VERSION "HNNBNNNYNNNNNNNNNNNNNNNNNNNNNNNNNNNNNNNNNN/4/%%%/4/'%**4NNN///"

NS_ :

BS_:

BU_: BAP_Tester BCM1 Gateway Gateway_PAG Klima_MSB Lift_VA VAS_L VAS_R

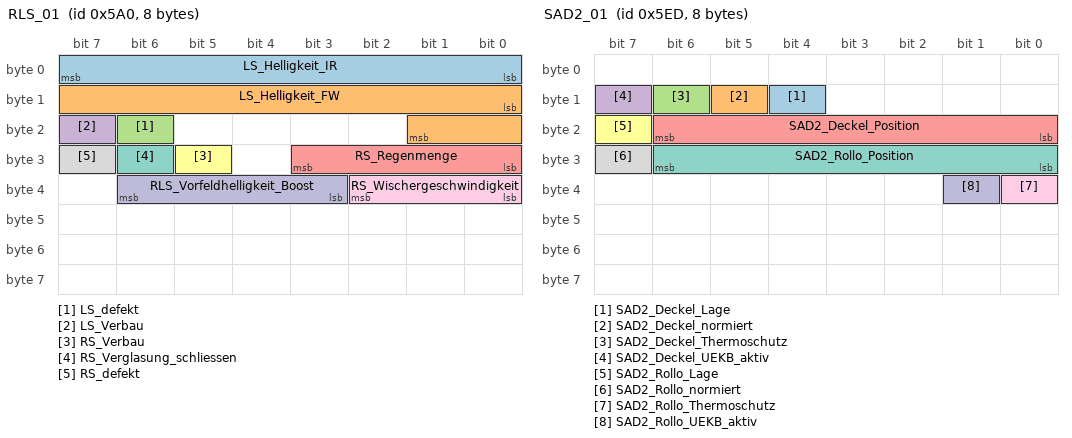
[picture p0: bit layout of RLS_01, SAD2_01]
BO_ 1440 RLS_01: 8 BCM1
 SG_ LS_Helligkeit_IR : 0|8@1+ (400,0) [0|101200] "Unit_Lux"  Gateway,Gateway_PAG,VAS_L,VAS_R
 SG_ LS_Helligkeit_FW : 8|10@1+ (6,0) [0|6126] "Unit_Lux"  Gateway,Gateway_PAG,VAS_L,VAS_R
 SG_ LS_defekt : 22|1@1+ (1.0,0.0) [0.0|1] ""  Gateway,Gateway_PAG,VAS_L,VAS_R
 SG_ LS_Verbau : 23|1@1+ (1.0,0.0) [0.0|1] ""  Gateway,Gateway_PAG,VAS_L,VAS_R
 SG_ RS_Regenmenge : 24|4@1+ (1.0,0.0) [0.0|15] ""  Gateway,Gateway_PAG,Klima_MSB
 SG_ RS_Verbau : 29|1@1+ (1.0,0.0) [0.0|1] ""  Gateway,Gateway_PAG,VAS_L,VAS_R
 SG_ RS_Verglasung_schliessen : 30|1@1+ (1.0,0.0) [0.0|1] ""  Gateway,Gateway_PAG
 SG_ RS_defekt : 31|1@1+ (1.0,0.0) [0.0|1] ""  Gateway,Gateway_PAG,VAS_L,VAS_R
 SG_ RS_Wischergeschwindigkeit : 32|3@1+ (1.0,0.0) [0.0|7] ""  Gateway,Gateway_PAG,VAS_L,VAS_R
 SG_ RLS_Vorfeldhelligkeit_Boost : 35|4@1+ (1.0,0.0) [0.0|15] ""  Gateway,Gateway_PAG

BO_ 1517 SAD2_01: 8 Gateway
 SG_ SAD2_Deckel_Lage : 12|1@1+ (1.0,0.0) [0.0|1] ""  Vector__XXX
 SG_ SAD2_Deckel_normiert : 13|1@1+ (1.0,0.0) [0.0|1] ""  Vector__XXX
 SG_ SAD2_Deckel_Thermoschutz : 14|1@1+ (1.0,0.0) [0.0|1] ""  Vector__XXX
 SG_ SAD2_Deckel_UEKB_aktiv : 15|1@1+ (1.0,0.0) [0.0|1] ""  Vector__XXX
 SG_ SAD2_Deckel_Position : 16|7@1+ (1,0) [0|100] "Unit_PerCent"  Vector__XXX
 SG_ SAD2_Rollo_Lage : 23|1@1+ (1.0,0.0) [0.0|1] ""  BCM1,Klima_MSB
 SG_ SAD2_Rollo_Position : 24|7@1+ (1,0) [0|100] "Unit_PerCent"  BCM1,Klima_MSB
 SG_ SAD2_Rollo_normiert : 31|1@1+ (1.0,0.0) [0.0|1] ""  Vector__XXX
 SG_ SAD2_Rollo_Thermoschutz : 32|1@1+ (1.0,0.0) [0.0|1] ""  Vector__XXX
 SG_ SAD2_Rollo_UEKB_aktiv : 33|1@1+ (1.0,0.0) [0.0|1] ""  Vector__XXX

BO_ 1504 SAD_01: 8 Gateway
 SG_ MD1_Position : 8|7@1+ (1,0) [0|100] "Unit_PerCent"  BCM1,Klima_MSB
 SG_ MD1_Lage : 15|1@1+ (1.0,0.0) [0.0|1] ""  BCM1,Klima_MSB
 SG_ MD3_Position : 16|7@1+ (1,0) [0|100] "Unit_PerCent"  BCM1,Klima_MSB
 SG_ MD3_Lage : 23|1@1+ (1.0,0.0) [0.0|1] ""  BCM1,Klima_MSB
 SG_ MRollo_Position : 24|7@1+ (1,0) [0|100] "Unit_PerCent"  BCM1,Klima_MSB
 SG_ MRollo_Lage : 31|1@1+ (1.0,0.0) [0.0|1] ""  BCM1,Klima_MSB
 SG_ SAD_normiert : 32|1@1+ (1.0,0.0) [0.0|1] ""  Vector__XXX
 SG_ SAD_Thermoschutz : 33|1@1+ (1.0,0.0) [0.0|1] ""  Vector__XXX
 SG_ SAD_UEKB_aktiv : 34|1@1+ (1.0,0.0) [0.0|1] ""  Vector__XXX
 SG_ Rollo_normiert : 35|1@1+ (1.0,0.0) [0.0|1] ""  Vector__XXX
 SG_ Rollo_Thermoschutz : 36|1@1+ (1.0,0.0) [0.0|1] ""  Vector__XXX
 SG_ Rollo_UEKB_aktiv : 37|1@1+ (1.0,0.0) [0.0|1] ""  Vector__XXX
 SG_ SAD_Taster_Deckel_hi : 38|4@1+ (1.0,0.0) [0.0|15] ""  Vector__XXX
 SG_ SAD_Taster_Deckel_vo : 42|4@1+ (1.0,0.0) [0.0|15] ""  Vector__XXX
 SG_ SAD_Taster_Rollo_hi : 46|3@1+ (1.0,0.0) [0.0|7] ""  Vector__XXX
 SG_ SAD_Taster_Rollo_vo : 49|3@1+ (1.0,0.0) [0.0|7] ""  Vector__XXX
 SG_ SAD_Anf_ESC_Zuschaltung : 52|1@1+ (1.0,0.0) [0.0|1] ""  Vector__XXX
 SG_ SAD_Text : 53|1@1+ (1.0,0.0) [0.0|1] ""  Vector__XXX
 SG_ SAD_ToggleBit : 54|1@1+ (1,0) [0|1] ""  Vector__XXX
 SG_ SAD_ParityBit : 55|1@1+ (1,0) [0|1] ""  Vector__XXX

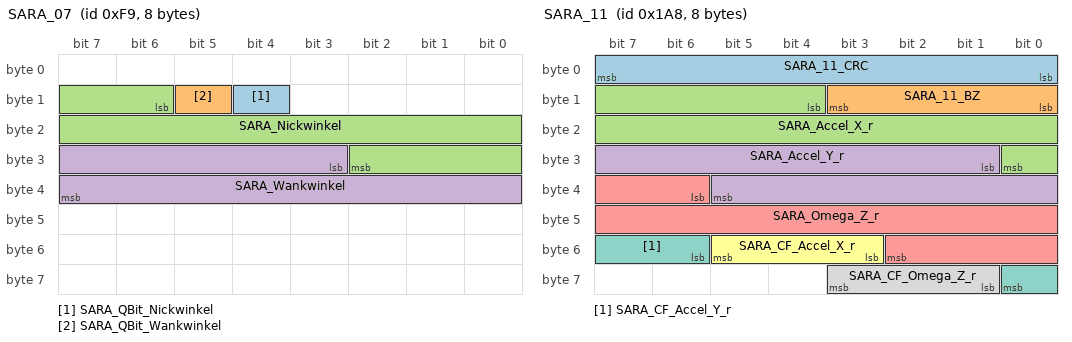
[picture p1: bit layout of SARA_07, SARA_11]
BO_ 249 SARA_07: 8 Gateway
 SG_ SARA_QBit_Nickwinkel : 12|1@1+ (1.0,0.0) [0.0|1] ""  BCM1,Klima_MSB
 SG_ SARA_QBit_Wankwinkel : 13|1@1+ (1.0,0.0) [0.0|1] ""  BCM1,Klima_MSB
 SG_ SARA_Nickwinkel : 14|13@1+ (0.025,-102.3) [-102.300|102.450] "Unit_DegreOfArc"  BCM1,Klima_MSB
 SG_ SARA_Wankwinkel : 27|13@1+ (0.025,-102.3) [-102.300|102.450] "Unit_DegreOfArc"  BCM1,Klima_MSB

BO_ 424 SARA_11: 8 Gateway
 SG_ SARA_11_CRC : 0|8@1+ (1,0) [0|255] ""  BCM1
 SG_ SARA_11_BZ : 8|4@1+ (1,0) [0|15] ""  BCM1
 SG_ SARA_Accel_X_r : 12|13@1+ (0.16,-655.36) [-655.20|655.04] "Unit_MeterPerSeconSquar"  BCM1,Lift_VA,VAS_L,VAS_R
 SG_ SARA_Accel_Y_r : 25|13@1+ (0.16,-655.36) [-655.20|655.04] "Unit_MeterPerSeconSquar"  BCM1,Lift_VA,VAS_L,VAS_R
 SG_ SARA_Omega_Z_r : 38|13@1+ (0.08,-327.68) [-327.60|327.52] "Unit_DegreOfArcPerSecon"  BCM1,VAS_L,VAS_R
 SG_ SARA_CF_Accel_X_r : 51|3@1+ (1.0,0.0) [0.0|7] ""  BCM1,VAS_L,VAS_R
 SG_ SARA_CF_Accel_Y_r : 54|3@1+ (1.0,0.0) [0.0|7] ""  BCM1,VAS_L,VAS_R
 SG_ SARA_CF_Omega_Z_r : 57|3@1+ (1.0,0.0) [0.0|7] ""  BCM1,VAS_L,VAS_R

BO_ 1522 Sensorik_Dimmung_01: 2 Gateway
 SG_ KBI_Phototransistor : 0|8@1+ (1,0) [0|253] ""  BCM1
 SG_ KBI_Dimmpoti : 8|7@1+ (1,0) [0|100] "Unit_PerCent"  BCM1

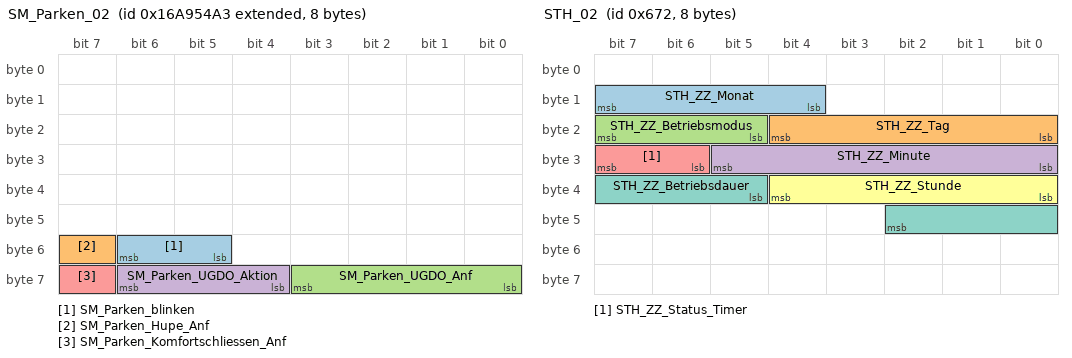
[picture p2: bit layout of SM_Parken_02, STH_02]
BO_ 2527679651 SM_Parken_02: 8 Gateway
 SG_ SM_Parken_blinken : 53|2@1+ (1.0,0.0) [0.0|3] ""  Vector__XXX
 SG_ SM_Parken_Hupe_Anf : 55|1@1+ (1.0,0.0) [0.0|1] ""  BCM1
 SG_ SM_Parken_UGDO_Anf : 56|4@1+ (1.0,0.0) [0.0|15] ""  BCM1
 SG_ SM_Parken_UGDO_Aktion : 60|3@1+ (1.0,0.0) [0.0|7] ""  BCM1
 SG_ SM_Parken_Komfortschliessen_Anf : 63|1@1+ (1.0,0.0) [0.0|1] ""  Vector__XXX

BO_ 980 SMLS_01: 8 Gateway
 SG_ SMLS_01_CRC : 0|8@1+ (1,0) [0|255] ""  BCM1
 SG_ SMLS_01_BZ : 8|4@1+ (1,0) [0|15] ""  BCM1
 SG_ BH_Blinker_li : 12|1@1+ (1.0,0.0) [0.0|1] ""  BCM1
 SG_ BH_Blinker_re : 13|1@1+ (1.0,0.0) [0.0|1] ""  BCM1
 SG_ BH_Lichthupe : 14|1@1+ (1.0,0.0) [0.0|1] ""  BCM1
 SG_ BH_Fernlicht : 15|1@1+ (1.0,0.0) [0.0|1] ""  BCM1
 SG_ WH_Tipwischen : 16|1@1+ (1.0,0.0) [0.0|1] ""  BCM1,VAS_L,VAS_R
 SG_ WH_Intervall : 17|1@1+ (1.0,0.0) [0.0|1] ""  BCM1
 SG_ WH_WischerStufe1 : 18|1@1+ (1.0,0.0) [0.0|1] ""  BCM1
 SG_ WH_WischerStufe2 : 19|1@1+ (1.0,0.0) [0.0|1] ""  BCM1
 SG_ WH_Frontwaschen : 20|1@1+ (1.0,0.0) [0.0|1] ""  BCM1
 SG_ WH_Heckintervall : 21|1@1+ (1.0,0.0) [0.0|1] ""  BCM1
 SG_ WH_Heckwaschen : 22|1@1+ (1.0,0.0) [0.0|1] ""  BCM1
 SG_ WH_Intervallstufen : 23|4@1+ (1.0,0.0) [0.0|15] ""  BCM1
 SG_ FAS_Taster : 27|1@1+ (1.0,0.0) [0.0|1] ""  Vector__XXX
 SG_ FAS_Taster_Fehler : 28|1@1+ (1.0,0.0) [0.0|1] ""  Vector__XXX
 SG_ SMLS_Hupe : 29|1@1+ (1.0,0.0) [0.0|1] ""  BCM1
 SG_ LRH_On_Off : 30|2@1+ (1.0,0.0) [0.0|3] ""  BCM1,Klima_MSB
 SG_ LRH_aktiv : 40|1@1+ (1.0,0.0) [0.0|1] ""  Vector__XXX
 SG_ SMLS_P_verriegelt_plausibel : 43|1@1+ (1.0,0.0) [0.0|1] ""  Vector__XXX
 SG_ WH_SRA : 44|1@1+ (1.0,0.0) [0.0|1] ""  BCM1
 SG_ WH_Wischer_Fehler : 45|1@1+ (1.0,0.0) [0.0|1] ""  BCM1
 SG_ BH_Blinker_Fehler : 46|1@1+ (1.0,0.0) [0.0|1] ""  Vector__XXX
 SG_ SMLS_PTT : 47|1@1+ (1.0,0.0) [0.0|1] ""  Vector__XXX
 SG_ WH_Tipwischen_lang : 48|1@1+ (1.0,0.0) [0.0|1] ""  BCM1

BO_ 1467 SoSe_01: 8 BCM1
 SG_ SoSe_SunInt_2D_Li : 0|8@1+ (5,0) [0|1200] "Unit_WattPerMeterSquar"  Gateway,Gateway_PAG,Klima_MSB
 SG_ SoSe_SunInt_2D_Re : 8|8@1+ (5,0) [0|1200] "Unit_WattPerMeterSquar"  Gateway,Gateway_PAG,Klima_MSB

BO_ 1710 Spiegel_01: 8 Gateway
 SG_ SP_FT_oben : 0|1@1+ (1.0,0.0) [0.0|1] ""  Vector__XXX
 SG_ SP_FT_unten : 1|1@1+ (1.0,0.0) [0.0|1] ""  Vector__XXX
 SG_ SP_FT_links : 2|1@1+ (1.0,0.0) [0.0|1] ""  Vector__XXX
 SG_ SP_FT_rechts : 3|1@1+ (1.0,0.0) [0.0|1] ""  Vector__XXX
 SG_ SP_BT_oben : 4|1@1+ (1.0,0.0) [0.0|1] ""  Vector__XXX
 SG_ SP_BT_unten : 5|1@1+ (1.0,0.0) [0.0|1] ""  Vector__XXX
 SG_ SP_BT_links : 6|1@1+ (1.0,0.0) [0.0|1] ""  Vector__XXX
 SG_ SP_BT_rechts : 7|1@1+ (1.0,0.0) [0.0|1] ""  Vector__XXX
 SG_ SP_abklappen : 8|1@1+ (1.0,0.0) [0.0|1] ""  Vector__XXX
 SG_ SP_anklappen : 9|1@1+ (1.0,0.0) [0.0|1] ""  Vector__XXX
 SG_ SP_normieren : 10|1@1+ (1.0,0.0) [0.0|1] ""  Vector__XXX
 SG_ SP_Hzg_Taster : 12|1@1+ (1.0,0.0) [0.0|1] ""  VAS_L,VAS_R
 SG_ SP_S_oben : 16|1@1+ (1.0,0.0) [0.0|1] ""  BCM1,VAS_L,VAS_R
 SG_ SP_S_unten : 17|1@1+ (1.0,0.0) [0.0|1] ""  BCM1,VAS_L,VAS_R
 SG_ SP_S_links : 18|1@1+ (1.0,0.0) [0.0|1] ""  BCM1,VAS_L,VAS_R
 SG_ SP_S_rechts : 19|1@1+ (1.0,0.0) [0.0|1] ""  BCM1,VAS_L,VAS_R
 SG_ SP_Auswahl_li : 20|1@1+ (1.0,0.0) [0.0|1] ""  BCM1,VAS_L,VAS_R
 SG_ SP_Auswahl_re : 21|1@1+ (1.0,0.0) [0.0|1] ""  BCM1,VAS_L,VAS_R
 SG_ SP_ARA_Status : 22|1@1+ (1.0,0.0) [0.0|1] ""  BCM1
 SG_ SP_S_Klappen : 23|1@1+ (1.0,0.0) [0.0|1] ""  BCM1,VAS_L,VAS_R
 SG_ SP_Verstellschalter_Fehler : 24|1@1+ (1.0,0.0) [0.0|1] ""  BCM1,VAS_L,VAS_R

BO_ 1313 STH_01: 8 Gateway
 SG_ STH_Funk_ein : 0|1@1+ (1.0,0.0) [0.0|1] ""  BCM1,Klima_MSB
 SG_ STH_Funk_aus : 1|1@1+ (1.0,0.0) [0.0|1] ""  BCM1,Klima_MSB
 SG_ STH_Zusatzheizung : 2|1@1+ (1.0,0.0) [0.0|1] ""  BCM1,Klima_MSB
 SG_ STH_LED : 3|1@1+ (1.0,0.0) [0.0|1] ""  BCM1,Klima_MSB
 SG_ STH_Pumpe_ein : 4|1@1+ (1,0) [0|1] ""  BCM1,Klima_MSB
 SG_ STH_Geblaese : 5|1@1+ (1.0,0.0) [0.0|1] ""  BCM1,Klima_MSB
 SG_ STH_EKP_Anst : 6|1@1+ (1.0,0.0) [0.0|1] ""  BCM1,Klima_MSB
 SG_ STH_Start_folgt : 7|1@1+ (1.0,0.0) [0.0|1] ""  Vector__XXX
 SG_ STH_Ventiloeffnungszeit : 8|6@1+ (1,0) [0|63] "Unit_Minut"  BCM1,Klima_MSB
 SG_ STH_Ventil_Status : 14|1@1+ (1.0,0.0) [0.0|1] ""  BCM1,Klima_MSB
 SG_ STH_Fehler_ElWaPu : 15|1@1+ (1.0,0.0) [0.0|1] ""  BCM1,Klima_MSB
 SG_ STH_Waermeeintrag : 16|6@1+ (1,0) [0|63] "Unit_None"  BCM1,Klima_MSB
 SG_ STH_Pumpen_Anf_extern : 22|1@1+ (1.0,0.0) [0.0|1] ""  Vector__XXX
 SG_ STH_KL_HUP : 23|1@1+ (1.0,0.0) [0.0|1] ""  Vector__XXX
 SG_ STH_KVS : 24|13@1+ (1,0) [0|8191] "Unit_MilliLiter"  BCM1,Klima_MSB
 SG_ STH_Fehlerstatus : 37|3@1+ (1.0,0.0) [0.0|7] ""  BCM1,Klima_MSB
 SG_ STH_Heizleistung : 40|8@1+ (1,0) [0|255] ""  BCM1,Klima_MSB
 SG_ STH_Wassertemp : 48|8@1+ (0.75,-40) [-40.00|142.25] "Unit_DegreCelsi"  BCM1,Klima_MSB
 SG_ STH_Texte : 56|3@1+ (1.0,0.0) [0.0|7] ""  BCM1,Klima_MSB
 SG_ STH_Motorvorwaermung : 59|1@1+ (1.0,0.0) [0.0|1] ""  BCM1,Klima_MSB
 SG_ STH_Servicemode : 60|1@1+ (1.0,0.0) [0.0|1] ""  BCM1,Klima_MSB
 SG_ STH_war_aktiv : 61|1@1+ (1.0,0.0) [0.0|1] ""  BCM1,Klima_MSB
 SG_ STH_KVS_Ueberlauf : 62|1@1+ (1.0,0.0) [0.0|1] ""  BCM1,Klima_MSB
 SG_ STH_SH_ZH : 63|1@1+ (1.0,0.0) [0.0|1] ""  Vector__XXX

BO_ 1650 STH_02: 8 Gateway
 SG_ STH_ZZ_Monat : 12|4@1+ (1,0) [1|12] ""  BCM1,Klima_MSB
 SG_ STH_ZZ_Tag : 16|5@1+ (1,0) [1|31] "Unit_Day"  BCM1,Klima_MSB
 SG_ STH_ZZ_Betriebsmodus : 21|3@1+ (1.0,0.0) [0.0|7] ""  BCM1,Klima_MSB
 SG_ STH_ZZ_Minute : 24|6@1+ (1,0) [0|59] ""  BCM1,Klima_MSB
 SG_ STH_ZZ_Status_Timer : 30|2@1+ (1.0,0.0) [0.0|3] ""  BCM1,Klima_MSB
 SG_ STH_ZZ_Stunde : 32|5@1+ (1,0) [0|23] ""  BCM1,Klima_MSB
 SG_ STH_ZZ_Betriebsdauer : 37|6@1+ (1,0) [0|63] "Unit_Minut"  BCM1,Klima_MSB

BO_ 505 STP_03: 8 Gateway
 SG_ STP_03_CRC : 0|8@1+ (1,0) [0|255] ""  Vector__XXX
 SG_ STP_03_BZ : 8|4@1+ (1,0) [0|15] ""  Vector__XXX
 SG_ STP_Slave_Status : 12|4@1+ (1.0,0.0) [0.0|15] ""  Vector__XXX
 SG_ FZE_STP_Abschaltbedingung : 16|3@1+ (1.0,0.0) [0.0|7] ""  Vector__XXX
 SG_ ACA_HF_Grund_AV_AB : 19|3@1+ (1.0,0.0) [0.0|7] ""  Vector__XXX
 SG_ FZE_STP_Status : 22|2@1+ (1.0,0.0) [0.0|3] ""  Vector__XXX
 SG_ STP_Notlaufaktivierung : 25|1@1+ (1.0,0.0) [0.0|1] ""  Vector__XXX
 SG_ STP_Funktion_freigegeben : 26|1@1+ (1.0,0.0) [0.0|1] ""  BCM1
 SG_ ACA_QF_Status_Anzeige : 27|4@1+ (1.0,0.0) [0.0|15] ""  Vector__XXX
 SG_ ACF_SwuFahrerUnaufmerksam : 31|1@1+ (1.0,0.0) [0.0|1] ""  Vector__XXX
 SG_ ACA_QF_Fahreruebernahme : 32|2@1+ (1.0,0.0) [0.0|3] ""  Vector__XXX
 SG_ ACA_HF_Status : 34|4@1+ (1.0,0.0) [0.0|15] ""  Vector__XXX
 SG_ FZE_Spurwechsel_erkannt_li : 40|1@1+ (1.0,0.0) [0.0|1] ""  Vector__XXX
 SG_ FZE_Spurwechsel_erkannt_re : 41|1@1+ (1.0,0.0) [0.0|1] ""  Vector__XXX
 SG_ ACF_Spurwechsel_moeglich : 42|1@1+ (1.0,0.0) [0.0|1] ""  Vector__XXX
 SG_ ACF_Spurwechsel_wahrscheinlich : 43|1@1+ (1.0,0.0) [0.0|1] ""  Vector__XXX
 SG_ FZE_STP_Aktivierverhinderung : 44|2@1+ (1.0,0.0) [0.0|3] ""  Vector__XXX

BO_ 1172 STS_01: 8 Gateway
 SG_ STS_01_CRC : 0|8@1+ (1,0) [0|255] ""  Vector__XXX
 SG_ STS_01_BZ : 8|4@1+ (1,0) [0|15] ""  Vector__XXX
 SG_ STS_Car_not_under_theft : 12|1@1+ (1.0,0.0) [0.0|1] ""  Vector__XXX
 SG_ STS_Car_under_theft : 13|1@1+ (1.0,0.0) [0.0|1] ""  Vector__XXX
 SG_ STS_Door_Lock : 14|1@1+ (1.0,0.0) [0.0|1] ""  Vector__XXX
 SG_ STS_Anlassersperre : 15|1@1+ (1.0,0.0) [0.0|1] ""  Vector__XXX
 SG_ STS_Typencodierung : 16|5@1+ (1.0,0.0) [0.0|31] ""  Vector__XXX
 SG_ STS_Spiegel_Anklappen : 21|1@1+ (1.0,0.0) [0.0|1] ""  Vector__XXX
 SG_ GW_STS2_Privatsphaere : 22|1@1+ (1.0,0.0) [0.0|1] ""  Vector__XXX
 SG_ STS_LIN_aktiv : 23|1@1+ (1.0,0.0) [0.0|1] ""  Vector__XXX
 SG_ STS_Standlicht : 24|1@1+ (1.0,0.0) [0.0|1] ""  BCM1
 SG_ STS_Fahrlicht : 25|1@1+ (1.0,0.0) [0.0|1] ""  BCM1
 SG_ STS_Alarm_still : 26|1@1+ (1.0,0.0) [0.0|1] ""  Vector__XXX
 SG_ STS_Texte : 27|4@1+ (1.0,0.0) [0.0|15] ""  Vector__XXX
 SG_ STS_Laderelais : 38|1@1+ (1.0,0.0) [0.0|1] ""  Vector__XXX
 SG_ STS_Summer : 48|1@1+ (1.0,0.0) [0.0|1] ""  Vector__XXX
 SG_ STS_Alarm_Blinker : 50|1@1+ (1.0,0.0) [0.0|1] ""  Vector__XXX
 SG_ STS_Notstart : 51|1@1+ (1.0,0.0) [0.0|1] ""  Vector__XXX
 SG_ STS_Signalhorn : 55|1@1+ (1.0,0.0) [0.0|1] ""  BCM1
 SG_ STS_Leerlaufschaltung : 56|1@1+ (1.0,0.0) [0.0|1] ""  Vector__XXX

BO_ 783 SWA_01: 8 Gateway
 SG_ SWA_01_CRC : 0|8@1+ (1,0) [0|255] ""  Vector__XXX
 SG_ SWA_01_BZ : 8|4@1+ (1,0) [0|15] ""  Vector__XXX
 SG_ SWA_Anzeigen : 12|4@1+ (1.0,0.0) [0.0|15] ""  Vector__XXX
 SG_ SWA_Blindheit_erkannt : 16|1@1+ (1.0,0.0) [0.0|1] ""  Vector__XXX
 SG_ SWA_rel_Nichtverf : 17|1@1+ (1.0,0.0) [0.0|1] ""  Vector__XXX
 SG_ SWA_rel_Fehler : 18|1@1+ (1.0,0.0) [0.0|1] ""  Vector__XXX
 SG_ SWA_Sta_aktiv : 19|1@1+ (1.0,0.0) [0.0|1] ""  Vector__XXX
 SG_ SWA_Sta_passiv : 20|1@1+ (1.0,0.0) [0.0|1] ""  Vector__XXX
 SG_ SWA_FT_RueckLED : 21|1@1+ (1.0,0.0) [0.0|1] ""  BCM1
 SG_ ASW_Status : 22|2@1+ (1.0,0.0) [0.0|3] ""  VAS_L,VAS_R
 SG_ SWA_Standziele_li : 24|1@1+ (1.0,0.0) [0.0|1] ""  Vector__XXX
 SG_ SWA_Kolonne_li : 25|1@1+ (1.0,0.0) [0.0|1] ""  Vector__XXX
 SG_ SWA_Infostufe_SWA_li : 26|1@1+ (1.0,0.0) [0.0|1] ""  VAS_L,VAS_R
 SG_ SWA_Warnung_SWA_li : 27|1@1+ (1.0,0.0) [0.0|1] ""  VAS_L,VAS_R
 SG_ ASW_Warnung_FS : 28|1@1+ (1.0,0.0) [0.0|1] ""  VAS_L,VAS_R
 SG_ ASW_Warnung_BFS : 29|1@1+ (1.0,0.0) [0.0|1] ""  VAS_L,VAS_R
 SG_ ASW_Kombitexte : 30|3@1+ (1.0,0.0) [0.0|7] ""  Vector__XXX
 SG_ SWA_Kolonne_mi : 33|1@1+ (1.0,0.0) [0.0|1] ""  Vector__XXX
 SG_ ASW_Modus : 34|3@1+ (1.0,0.0) [0.0|7] ""  VAS_L,VAS_R
 SG_ SWA_Modus : 37|3@1+ (1.0,0.0) [0.0|7] ""  VAS_L,VAS_R
 SG_ SWA_Standziele_re : 40|1@1+ (1.0,0.0) [0.0|1] ""  Vector__XXX
 SG_ SWA_Kolonne_re : 41|1@1+ (1.0,0.0) [0.0|1] ""  Vector__XXX
 SG_ SWA_Infostufe_SWA_re : 42|1@1+ (1.0,0.0) [0.0|1] ""  VAS_L,VAS_R
 SG_ SWA_Warnung_SWA_re : 43|1@1+ (1.0,0.0) [0.0|1] ""  VAS_L,VAS_R
 SG_ HRE_Anzeigetexte : 44|4@1+ (1.0,0.0) [0.0|15] ""  Vector__XXX
 SG_ SWA_Status_02 : 48|2@1+ (1.0,0.0) [0.0|3] ""  VAS_L,VAS_R
 SG_ Heckradar_Kombitexte : 56|5@1+ (1.0,0.0) [0.0|31] ""  Vector__XXX
 SG_ RCTA_Kombitexte : 61|3@1+ (1.0,0.0) [0.0|7] ""  Vector__XXX

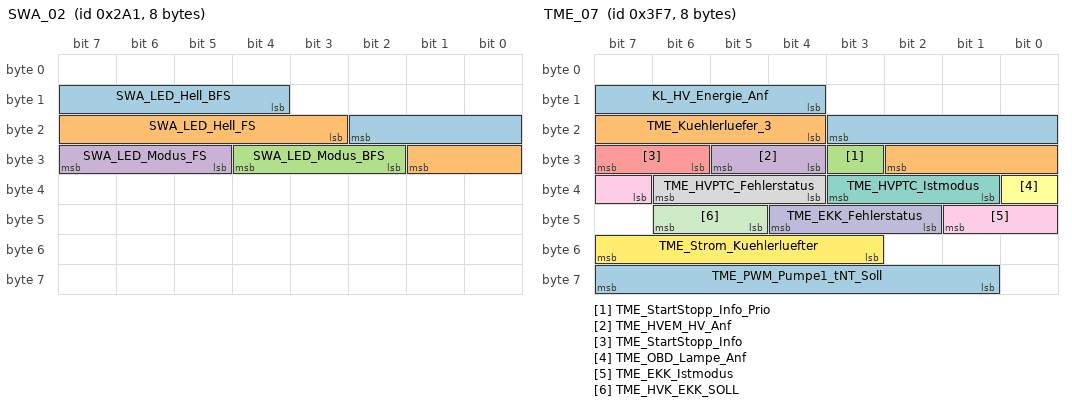
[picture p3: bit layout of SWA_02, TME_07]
BO_ 673 SWA_02: 8 Gateway
 SG_ SWA_LED_Hell_BFS : 12|7@1+ (1,0) [0|100] "Unit_PerCent"  VAS_L,VAS_R
 SG_ SWA_LED_Hell_FS : 19|7@1+ (1,0) [0|100] "Unit_PerCent"  VAS_L,VAS_R
 SG_ SWA_LED_Modus_BFS : 26|3@1+ (1.0,0.0) [0.0|7] ""  VAS_L,VAS_R
 SG_ SWA_LED_Modus_FS : 29|3@1+ (1.0,0.0) [0.0|7] ""  VAS_L,VAS_R

BO_ 1413 Systeminfo_01: 8 Gateway
 SG_ SI_Sammel_SG_Fehler : 0|6@1+ (1,0) [0|60] ""  Vector__XXX
 SG_ SI_Diagnose_Aktiv : 7|1@1+ (1.0,0.0) [0.0|1] ""  Vector__XXX
 SG_ SI_QRS_Mode : 8|1@1+ (1.0,0.0) [0.0|1] ""  BCM1,Klima_MSB,VAS_L,VAS_R
 SG_ SI_T_Mode : 9|1@1+ (1.0,0.0) [0.0|1] ""  BCM1,Klima_MSB,Lift_VA,VAS_L,VAS_R
 SG_ SI_NWDF : 10|1@1+ (1.0,0.0) [0.0|1] ""  BCM1,Klima_MSB,Lift_VA,VAS_L,VAS_R
 SG_ SI_NWDF_gueltig : 11|1@1+ (1.0,0.0) [0.0|1] ""  BCM1,Klima_MSB,Lift_VA,VAS_L,VAS_R
 SG_ SI_Sammelfehler : 12|1@1+ (1.0,0.0) [0.0|1] ""  Vector__XXX
 SG_ GW_KD_Fehler : 13|1@1+ (1.0,0.0) [0.0|1] ""  Vector__XXX
 SG_ SI_T_Schutz : 14|1@1+ (1.0,0.0) [0.0|1] ""  BCM1,Lift_VA
 SG_ SI_BUS_01 : 16|1@1+ (1.0,0.0) [0.0|1] ""  BCM1
 SG_ SI_BUS_02 : 17|1@1+ (1.0,0.0) [0.0|1] ""  Vector__XXX
 SG_ SI_BUS_03 : 18|1@1+ (1.0,0.0) [0.0|1] ""  BCM1
 SG_ SI_BUS_04 : 19|1@1+ (1.0,0.0) [0.0|1] ""  BCM1
 SG_ SI_BUS_05 : 20|1@1+ (1.0,0.0) [0.0|1] ""  Vector__XXX
 SG_ SI_BUS_06 : 21|1@1+ (1.0,0.0) [0.0|1] ""  BCM1
 SG_ SI_BUS_07 : 22|1@1+ (1.0,0.0) [0.0|1] ""  Vector__XXX
 SG_ SI_BUS_08 : 23|1@1+ (1.0,0.0) [0.0|1] ""  Vector__XXX
 SG_ SI_BUS_09 : 24|1@1+ (1.0,0.0) [0.0|1] ""  Vector__XXX
 SG_ SI_BUS_10 : 25|1@1+ (1.0,0.0) [0.0|1] ""  BCM1
 SG_ SI_BUS_11 : 26|1@1+ (1.0,0.0) [0.0|1] ""  Vector__XXX
 SG_ SI_BUS_12 : 27|1@1+ (1.0,0.0) [0.0|1] ""  Vector__XXX
 SG_ SI_BUS_13 : 28|1@1+ (1.0,0.0) [0.0|1] ""  BCM1
 SG_ SI_BUS_14 : 29|1@1+ (1.0,0.0) [0.0|1] ""  Vector__XXX
 SG_ SI_BUS_15 : 30|1@1+ (1.0,0.0) [0.0|1] ""  Vector__XXX
 SG_ SI_Bus_Identifikation : 32|8@1+ (1.0,0.0) [0.0|255] ""  Vector__XXX
 SG_ SI_CAB : 40|24@1+ (1.0,0.0) [0.0|16777215] ""  Vector__XXX

BO_ 1015 TME_07: 8 Gateway
 SG_ KL_HV_Energie_Anf : 12|8@1+ (50,0) [0|12600] "Unit_WattHour"  Vector__XXX
 SG_ TME_Kuehlerluefer_3 : 20|7@1+ (1,0) [0|100] "Unit_PerCent"  Vector__XXX
 SG_ TME_StartStopp_Info_Prio : 27|1@1+ (1.0,0.0) [0.0|1] ""  Vector__XXX
 SG_ TME_HVEM_HV_Anf : 28|2@1+ (1.0,0.0) [0.0|3] ""  Vector__XXX
 SG_ TME_StartStopp_Info : 30|2@1+ (1.0,0.0) [0.0|3] ""  Klima_MSB
 SG_ TME_OBD_Lampe_Anf : 32|1@1+ (1.0,0.0) [0.0|1] ""  Vector__XXX
 SG_ TME_HVPTC_Istmodus : 33|3@1+ (1.0,0.0) [0.0|7] ""  Vector__XXX
 SG_ TME_HVPTC_Fehlerstatus : 36|3@1+ (1.0,0.0) [0.0|7] ""  Vector__XXX
 SG_ TME_EKK_Istmodus : 39|3@1+ (1.0,0.0) [0.0|7] ""  Vector__XXX
 SG_ TME_EKK_Fehlerstatus : 42|3@1+ (1.0,0.0) [0.0|7] ""  Vector__XXX
 SG_ TME_HVK_EKK_SOLL : 45|2@1+ (1.0,0.0) [0.0|3] ""  Vector__XXX
 SG_ TME_Strom_Kuehlerluefter : 51|5@1+ (5,0) [0|145] "Unit_Amper"  Vector__XXX
 SG_ TME_PWM_Pumpe1_tNT_Soll : 57|7@1+ (1,0) [0|100] "Unit_PerCent"  Vector__XXX

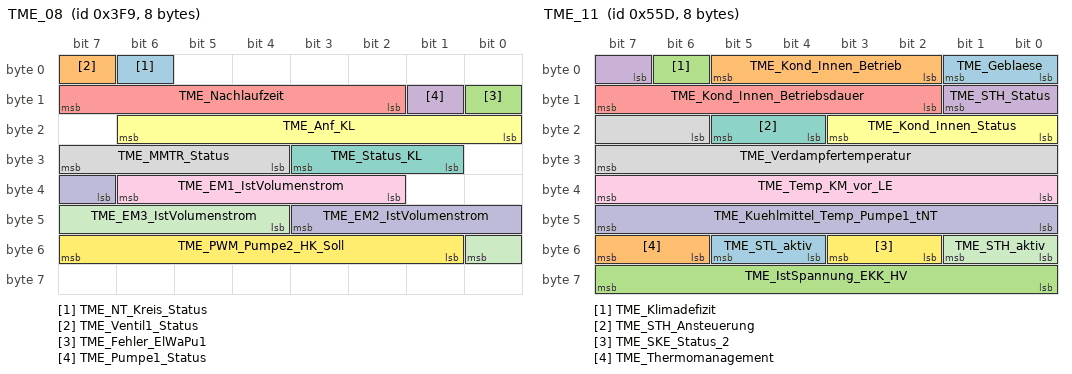
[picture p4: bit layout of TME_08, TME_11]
BO_ 1017 TME_08: 8 Gateway
 SG_ TME_NT_Kreis_Status : 6|1@1+ (1.0,0.0) [0.0|1] ""  Vector__XXX
 SG_ TME_Ventil1_Status : 7|1@1+ (1.0,0.0) [0.0|1] ""  BCM1,Klima_MSB
 SG_ TME_Fehler_ElWaPu1 : 8|1@1+ (1.0,0.0) [0.0|1] ""  BCM1,Klima_MSB
 SG_ TME_Pumpe1_Status : 9|1@1+ (1.0,0.0) [0.0|1] ""  BCM1
 SG_ TME_Nachlaufzeit : 10|6@1+ (15,0) [15|945] "Unit_Secon"  Vector__XXX
 SG_ TME_Anf_KL : 16|7@1+ (1,0) [0|100] "Unit_PerCent"  Vector__XXX
 SG_ TME_Status_KL : 25|3@1+ (1.0,0.0) [0.0|7] ""  Vector__XXX
 SG_ TME_MMTR_Status : 28|4@1+ (1.0,0.0) [0.0|15] ""  Klima_MSB
 SG_ TME_EM1_IstVolumenstrom : 34|5@1+ (0.5,0) [0.0|14.5] "Unit_LiterPerMinut"  Vector__XXX
 SG_ TME_EM2_IstVolumenstrom : 39|5@1+ (0.5,0) [0.0|14.5] "Unit_LiterPerMinut"  Vector__XXX
 SG_ TME_EM3_IstVolumenstrom : 44|5@1+ (0.5,0) [0.0|14.5] "Unit_LiterPerMinut"  Vector__XXX
 SG_ TME_PWM_Pumpe2_HK_Soll : 49|7@1+ (1,0) [0|100] "Unit_PerCent"  Vector__XXX

BO_ 1375 TME_10: 8 Gateway
 SG_ TME_VoKo_Strategie_Anzeige : 2|4@1+ (1.0,0.0) [0.0|15] ""  Vector__XXX
 SG_ TME_Zuheizer_Freigabe : 6|1@1+ (1.0,0.0) [0.0|1] ""  Vector__XXX
 SG_ TME_AC_LED : 7|1@1+ (1.0,0.0) [0.0|1] ""  BCM1,Klima_MSB
 SG_ TME_Heizstrategie : 8|4@1+ (1.0,0.0) [0.0|15] ""  BCM1,Klima_MSB
 SG_ TME_Systemstatus : 12|2@1+ (1.0,0.0) [0.0|3] ""  BCM1,Klima_MSB
 SG_ TME_Kbr_Innenraum : 14|1@1+ (1.0,0.0) [0.0|1] ""  BCM1,Klima_MSB
 SG_ TME_Freigabe_Vorkond : 15|1@1+ (1.0,0.0) [0.0|1] ""  BCM1,Klima_MSB
 SG_ TME_Verdampfer_Status : 16|1@1+ (1.0,0.0) [0.0|1] ""  BCM1,Klima_MSB
 SG_ TME_Kuehlmittel_Sensor : 17|1@1+ (1.0,0.0) [0.0|1] ""  Vector__XXX
 SG_ TME_AC_Rueckmeldung : 18|2@1+ (1.0,0.0) [0.0|3] ""  BCM1,Klima_MSB
 SG_ TME_Heizungspumpen_Anst : 20|4@1+ (10,0) [0|100] "Unit_PerCent"  Vector__XXX
 SG_ TME_Frischluftklappe_Soll : 24|7@1+ (1,0) [0|100] "Unit_PerCent"  BCM1,Klima_MSB
 SG_ TME_Freigabe_Luft_PTC : 31|1@1+ (1.0,0.0) [0.0|1] ""  BCM1,Klima_MSB
 SG_ TME_Umluftklappe_Soll : 32|7@1+ (1,0) [0|100] "Unit_PerCent"  BCM1,Klima_MSB
 SG_ TME_Waermepumpe_aktiv : 39|1@1+ (1.0,0.0) [0.0|1] ""  BCM1,Klima_MSB
 SG_ TME_Nachlaufzeit_Heizp : 40|6@1+ (15,0) [0|945] "Unit_Secon"  Vector__XXX
 SG_ TME_Absperrventil1_oeffnen : 46|2@1+ (1.0,0.0) [0.0|3] ""  Vector__XXX
 SG_ TME_Klima_Defizit : 48|8@1+ (40,0) [0|10000] "Unit_Watt"  BCM1,Klima_MSB
 SG_ TME_Temp_KM_vor_HWT : 56|8@1+ (0.75,-40) [-40.00|149.75] "Unit_DegreCelsi"  BCM1,Klima_MSB

BO_ 1373 TME_11: 8 Gateway
 SG_ TME_Geblaese : 0|2@1+ (1.0,0.0) [0.0|3] ""  Vector__XXX
 SG_ TME_Kond_Innen_Betrieb : 2|4@1+ (1.0,0.0) [0.0|15] ""  BCM1
 SG_ TME_Klimadefizit : 6|1@1+ (1.0,0.0) [0.0|1] ""  BCM1,Klima_MSB
 SG_ TME_STH_Status : 7|3@1+ (1.0,0.0) [0.0|7] ""  Vector__XXX
 SG_ TME_Kond_Innen_Betriebsdauer : 10|6@1+ (1,0) [0|60] "Unit_Minut"  BCM1,Klima_MSB
 SG_ TME_Kond_Innen_Status : 16|4@1+ (1.0,0.0) [0.0|15] ""  BCM1
 SG_ TME_STH_Ansteuerung : 20|2@1+ (1.0,0.0) [0.0|3] ""  BCM1
 SG_ TME_Verdampfertemperatur : 22|10@1+ (0.1,-20) [-20.0|70.0] "Unit_DegreCelsi"  Vector__XXX
 SG_ TME_Temp_KM_vor_LE : 32|8@1+ (0.75,-48) [-48.00|141.75] "Unit_DegreCelsi"  Vector__XXX
 SG_ TME_Kuehlmittel_Temp_Pumpe1_tNT : 40|8@1+ (1,-40) [-40|213] "Unit_DegreCelsi"  Vector__XXX
 SG_ TME_STH_aktiv : 48|2@1+ (1.0,0.0) [0.0|3] ""  BCM1
 SG_ TME_SKE_Status_2 : 50|2@1+ (1.0,0.0) [0.0|3] ""  Vector__XXX
 SG_ TME_STL_aktiv : 52|2@1+ (1.0,0.0) [0.0|3] ""  BCM1
 SG_ TME_Thermomanagement : 54|2@1+ (1.0,0.0) [0.0|3] ""  Vector__XXX
 SG_ TME_IstSpannung_EKK_HV : 56|8@1+ (2,0) [0|508] "Unit_Volt"  Vector__XXX

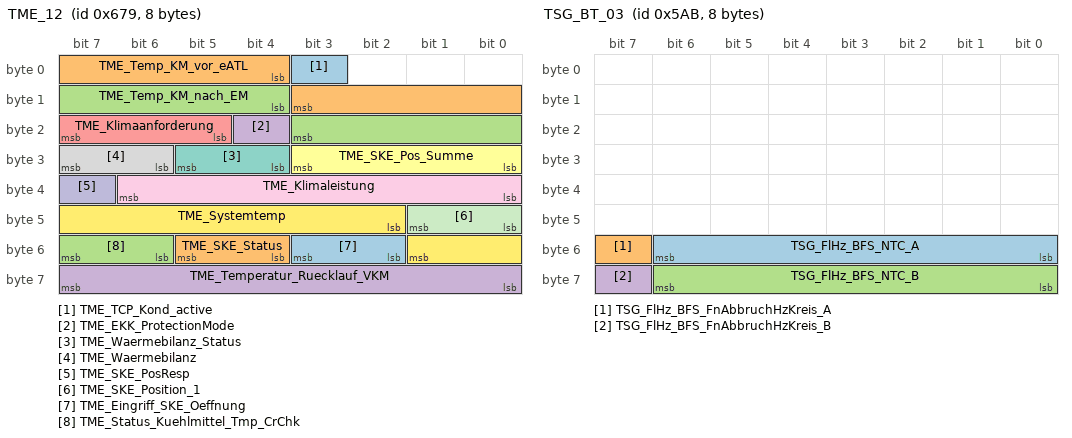
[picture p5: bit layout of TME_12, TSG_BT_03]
BO_ 1657 TME_12: 8 Gateway
 SG_ TME_TCP_Kond_active : 3|1@1+ (1.0,0.0) [0.0|1] ""  Klima_MSB
 SG_ TME_Temp_KM_vor_eATL : 4|8@1+ (1,-40) [-40|213] "Unit_DegreCelsi"  Vector__XXX
 SG_ TME_Temp_KM_nach_EM : 12|8@1+ (0.75,-48) [-48.00|141.00] "Unit_DegreCelsi"  Vector__XXX
 SG_ TME_EKK_ProtectionMode : 20|1@1+ (1.0,0.0) [0.0|1] ""  Vector__XXX
 SG_ TME_Klimaanforderung : 21|3@1+ (1.0,0.0) [0.0|7] ""  BCM1
 SG_ TME_SKE_Pos_Summe : 24|4@1+ (10,0) [0|100] "Unit_PerCent"  Vector__XXX
 SG_ TME_Waermebilanz_Status : 28|2@1+ (1.0,0.0) [0.0|3] ""  Vector__XXX
 SG_ TME_Waermebilanz : 30|2@1+ (1.0,0.0) [0.0|3] ""  Vector__XXX
 SG_ TME_Klimaleistung : 32|7@1+ (0.04,0) [0.00|5.00] "Unit_KiloWatt"  Vector__XXX
 SG_ TME_SKE_PosResp : 39|1@1+ (1.0,0.0) [0.0|1] ""  Vector__XXX
 SG_ TME_SKE_Position_1 : 40|2@1+ (1.0,0.0) [0.0|3] ""  Vector__XXX
 SG_ TME_Systemtemp : 42|8@1+ (0.75,-48) [-48.00|141.75] "Unit_DegreCelsi"  Vector__XXX
 SG_ TME_Eingriff_SKE_Oeffnung : 50|2@1+ (1.0,0.0) [0.0|3] ""  Vector__XXX
 SG_ TME_SKE_Status : 52|2@1+ (1.0,0.0) [0.0|3] ""  Vector__XXX
 SG_ TME_Status_Kuehlmittel_Tmp_CrChk : 54|2@1+ (1.0,0.0) [0.0|3] ""  Vector__XXX
 SG_ TME_Temperatur_Ruecklauf_VKM : 56|8@1+ (0.75,-40) [-40.00|149.75] "Unit_DegreCelsi"  BCM1,Klima_MSB

BO_ 977 TSG_BT_01: 8 Gateway
 SG_ BT_Tuer_geoeffnet : 0|1@1+ (1.0,0.0) [0.0|1] ""  BCM1,Klima_MSB,Lift_VA,VAS_L,VAS_R
 SG_ BT_verriegelt : 1|1@1+ (1.0,0.0) [0.0|1] ""  VAS_L,VAS_R
 SG_ BT_gesafet : 2|1@1+ (1.0,0.0) [0.0|1] ""  Vector__XXX
 SG_ BT_Schluesselschalter_auf : 3|1@1+ (1.0,0.0) [0.0|1] ""  Vector__XXX
 SG_ BT_Schluesselschalter_zu : 4|1@1+ (1.0,0.0) [0.0|1] ""  Vector__XXX
 SG_ BT_Unlock_Taster : 5|1@1+ (1.0,0.0) [0.0|1] ""  Vector__XXX
 SG_ BT_Lock_Taster : 6|1@1+ (1.0,0.0) [0.0|1] ""  Vector__XXX
 SG_ BT_Sperrklinke : 7|1@1+ (1.0,0.0) [0.0|1] ""  Vector__XXX
 SG_ BT_TAG_betaetigt : 8|1@1+ (1.0,0.0) [0.0|1] ""  VAS_L,VAS_R
 SG_ BT_TIG_betaetigt : 9|1@1+ (1.0,0.0) [0.0|1] ""  BCM1,VAS_L,VAS_R
 SG_ BT_EC_Spiegel_Helligkeit : 10|5@1+ (3.125,0) [0.000|96.875] "Unit_PerCent"  Vector__XXX
 SG_ BT_Sp_Heizung_Anf : 15|1@1+ (100,0) [0|100] "Unit_PerCent"  Vector__XXX
 SG_ BT_Tuer_Status : 16|2@1+ (1.0,0.0) [0.0|3] ""  Vector__XXX
 SG_ BT_TSG_hinten_verbaut : 18|1@1+ (1.0,0.0) [0.0|1] ""  Vector__XXX
 SG_ BT_Sp_Blk_def : 19|1@1+ (1.0,0.0) [0.0|1] ""  BCM1
 SG_ BT_FH_S_ManHoch : 20|1@1+ (1.0,0.0) [0.0|1] ""  Vector__XXX
 SG_ BT_FH_S_AutoHoch : 21|1@1+ (1.0,0.0) [0.0|1] ""  Vector__XXX
 SG_ BT_FH_S_ManTief : 22|1@1+ (1.0,0.0) [0.0|1] ""  Vector__XXX
 SG_ BT_FH_S_AutoTief : 23|1@1+ (1.0,0.0) [0.0|1] ""  Vector__XXX
 SG_ BT_FH_Oeffnung : 24|8@1+ (0.5,0) [0.0|100.0] "Unit_PerCent"  BCM1,Klima_MSB
 SG_ BT_FH_Bew_hoch : 32|1@1+ (1.0,0.0) [0.0|1] ""  Vector__XXX
 SG_ BT_FH_Bew_tief : 33|1@1+ (1.0,0.0) [0.0|1] ""  Vector__XXX
 SG_ BT_FH_Fang : 34|1@1+ (1.0,0.0) [0.0|1] ""  Vector__XXX
 SG_ BT_FH_Block : 35|1@1+ (1.0,0.0) [0.0|1] ""  Vector__XXX
 SG_ BT_FH_Thermo : 36|1@1+ (1.0,0.0) [0.0|1] ""  Vector__XXX
 SG_ BT_UEKB_aktiviert : 37|1@1+ (1.0,0.0) [0.0|1] ""  Vector__XXX
 SG_ BT_Kisi_Fehler : 38|1@1+ (1.0,0.0) [0.0|1] ""  Vector__XXX
 SG_ BT_FH_normiert : 39|1@1+ (1.0,0.0) [0.0|1] ""  Vector__XXX
 SG_ BT_Schliesstaster : 40|1@1+ (1.0,0.0) [0.0|1] ""  Vector__XXX
 SG_ BT_Zuziehhilfe_aktiv : 41|1@1+ (1.0,0.0) [0.0|1] ""  Vector__XXX
 SG_ BT_SP_ausgerastet : 42|1@1+ (1.0,0.0) [0.0|1] ""  Vector__XXX
 SG_ BT_SP_lr_aktiv : 43|1@1+ (1.0,0.0) [0.0|1] ""  Vector__XXX
 SG_ BT_SP_ht_aktiv : 44|1@1+ (1.0,0.0) [0.0|1] ""  Vector__XXX
 SG_ BT_SP_Heizung_aktiv : 45|1@1+ (1.0,0.0) [0.0|1] ""  Vector__XXX
 SG_ BT_Oben_Block_erw : 46|1@1+ (1.0,0.0) [0.0|1] ""  Vector__XXX
 SG_ BT_Unten_Block_erw : 47|1@1+ (1.0,0.0) [0.0|1] ""  Vector__XXX
 SG_ BT_Tuer_Status_QBit : 48|1@1+ (1.0,0.0) [0.0|1] ""  Vector__XXX
 SG_ BFS_Status_eTAG : 49|2@1+ (1.0,0.0) [0.0|3] ""  Vector__XXX
 SG_ BT_TCR_Mode_aktiv : 51|1@1+ (1.0,0.0) [0.0|1] ""  Vector__XXX
 SG_ BT_SP_Heizung_Status : 55|1@1+ (1.0,0.0) [0.0|1] ""  BCM1
 SG_ ASW_Warnung_aktiv_BFS : 56|1@1+ (1.0,0.0) [0.0|1] ""  BCM1
 SG_ BT_FH_Pos_oben : 57|1@1+ (1.0,0.0) [0.0|1] ""  Vector__XXX
 SG_ BT_Tuerschloss_defekt : 58|1@1+ (1.0,0.0) [0.0|1] ""  Vector__XXX
 SG_ BT_Tueroeffnen_Warnung : 59|1@1+ (1.0,0.0) [0.0|1] ""  Vector__XXX
 SG_ BT_Lock_Taster_inv : 60|1@1+ (1.0,0.0) [0.0|1] ""  Vector__XXX
 SG_ BT_Schluesselschalter_zu_inv : 61|1@1+ (1.0,0.0) [0.0|1] ""  Vector__XXX
 SG_ BT_SWA_HMI_defekt : 62|1@1+ (1.0,0.0) [0.0|1] ""  Vector__XXX
 SG_ BT_ASW_HMI_defekt : 63|1@1+ (1.0,0.0) [0.0|1] ""  Vector__XXX

BO_ 1451 TSG_BT_03: 8 Gateway
 SG_ TSG_FlHz_BFS_NTC_A : 48|7@1+ (1,-40) [-40|80] "Unit_DegreCelsi"  BCM1,Klima_MSB
 SG_ TSG_FlHz_BFS_FnAbbruchHzKreis_A : 55|1@1+ (1.0,0.0) [0.0|1] ""  BCM1,Klima_MSB
 SG_ TSG_FlHz_BFS_NTC_B : 56|7@1+ (1,-40) [-40|80] "Unit_DegreCelsi"  BCM1
 SG_ TSG_FlHz_BFS_FnAbbruchHzKreis_B : 63|1@1+ (1.0,0.0) [0.0|1] ""  BCM1

BO_TX_BU_ 1517 :Gateway,Gateway_PAG;
BO_TX_BU_ 1504 :Gateway,Gateway_PAG;
BO_TX_BU_ 249 :Gateway,Gateway_PAG;
BO_TX_BU_ 424 :Gateway,Gateway_PAG;
BO_TX_BU_ 1522 :Gateway,Gateway_PAG;
BO_TX_BU_ 2527679651 :Gateway,Gateway_PAG;
BO_TX_BU_ 980 :Gateway,Gateway_PAG;
BO_TX_BU_ 1710 :Gateway,Gateway_PAG;
BO_TX_BU_ 1313 :Gateway,Gateway_PAG;
BO_TX_BU_ 1650 :Gateway,Gateway_PAG;
BO_TX_BU_ 505 :Gateway,Gateway_PAG;
BO_TX_BU_ 1172 :Gateway,Gateway_PAG;
BO_TX_BU_ 783 :Gateway,Gateway_PAG;
BO_TX_BU_ 673 :Gateway,Gateway_PAG;
BO_TX_BU_ 1413 :Gateway,Gateway_PAG;
BO_TX_BU_ 1015 :Gateway,Gateway_PAG;
BO_TX_BU_ 1017 :Gateway,Gateway_PAG;
BO_TX_BU_ 1375 :Gateway,Gateway_PAG;
BO_TX_BU_ 1373 :Gateway,Gateway_PAG;
BO_TX_BU_ 1657 :Gateway,Gateway_PAG;
BO_TX_BU_ 977 :Gateway,Gateway_PAG;
BO_TX_BU_ 1451 :Gateway,Gateway_PAG;
CM_ BO_ 1440 "8Byte ab MLBevo
LIN-CAN (1:1) Botschaften werden geroutet
-  wenn entsprechender Slave codiert ist
-  wenn fehlerfreie Kommunikation zum Slave besteht
-  bei fehlerhafter Kommunikation zum Slave wird die Botschaft für 4s mit den letzten gültigen Werte";
CM_ BO_ 1517 "


";
CM_ BO_ 1504 "MLBevo 8Byte
LIN-CAN (1:1) Botschaft wird geroutet:
- wenn entsprechender Slave codiert ist
- wenn fehlerfreie Kommunikation zum Slave besteht
- bei fehlerhafter Kommunikation zum Slave wird die Botschaft für 4s mit den letzten gültigen Werten versend";
CM_ BO_ 424 "CAN-Botschaft";
CM_ BO_ 1522 "MQB";
CM_ BO_ 980 "Ab MQB 7.2";
CM_ BO_ 1710 "MLBevo 8Byte";
CM_ BO_ 1650 "Zielzeittimeranzeige im Display des MMI";
CM_ BO_ 783 "ab MQB mit CRC-8";
CM_ BO_ 1413 "MQB, MLBevo";
CM_ BO_ 977 "ab MQB 7.05";

CM_ SG_ 1440 LS_defekt "Fehlererkennung Lichtsensor
";
CM_ SG_ 1440 LS_Helligkeit_FW "Vorfeldhelligkeit";
CM_ SG_ 1440 LS_Helligkeit_IR "Globalfeldhelligkeit";
CM_ SG_ 1440 LS_Verbau "Verbauinfo Lichtsensor";
CM_ SG_ 1440 RLS_Vorfeldhelligkeit_Boost "erweiterte Helligkeitssensierung für HUD";
CM_ SG_ 1440 RS_defekt "Fehlererkennung Regensensor";
CM_ SG_ 1440 RS_Regenmenge "Regenmenge";
CM_ SG_ 1440 RS_Verbau "Verbauinfo Regensensor";
CM_ SG_ 1440 RS_Verglasung_schliessen "Anforderung: Verglasung schliessen
";
CM_ SG_ 1440 RS_Wischergeschwindigkeit "Wischergeschwindigkeit (Hübe/min)";

CM_ SG_ 1517 SAD2_Deckel_Lage "Lage Schiebeausstelldach";
CM_ SG_ 1517 SAD2_Deckel_normiert "Anzeige Normierung des Schiebeausstelldaches 2";
CM_ SG_ 1517 SAD2_Deckel_Position "Aktuelle Öffnungsweite des Schiebeausstelldaches 2";
CM_ SG_ 1517 SAD2_Deckel_Thermoschutz "Anzeige aktivierter Thermoschutz des Schiebeausstelldaches 2";
CM_ SG_ 1517 SAD2_Deckel_UEKB_aktiv "Anzeige aktivierter Überschusskraftbegrenzung des Schiebeausstelldaches 2";
CM_ SG_ 1517 SAD2_Rollo_Lage "Lage des Rollo 2";
CM_ SG_ 1517 SAD2_Rollo_normiert "Signal für die Anzeige, dass das Rollo2 korrekt normiert wurde.";
CM_ SG_ 1517 SAD2_Rollo_Position "Aktuelle Öffnungsweite des Dachrollo 2.";
CM_ SG_ 1517 SAD2_Rollo_Thermoschutz "Anzeigen aktivierter Thermoschutz des Dachrollo 2";
CM_ SG_ 1517 SAD2_Rollo_UEKB_aktiv "Anzeigen aktivierter Überschusskraftbegrenzung des Dachrollos 2";

CM_ SG_ 1504 MD1_Lage "Lage Schiebedachstellung 1 (Signal wird 1:1 vom BCM2 geroutet; ursprünglicher Sender: SAD = LIN-Slave vom BCM2)";
CM_ SG_ 1504 MD1_Position "Aktuelle Öffnungsweite Schiebedach.";
CM_ SG_ 1504 MD3_Lage "Lage Schiebedachstellung 3 
(Signal wird 1:1 vom BCM2 geroutet; ursprünglicher Sender: SAD = LIN-Slave vom BCM2) 
";
CM_ SG_ 1504 MD3_Position "Schiebedachstellung 3 
(Signal wird 1:1 vom BCM2 geroutet; ursprünglicher Sender: SAD = LIN-Slave vom BCM2)
";
CM_ SG_ 1504 MRollo_Lage "Lage Rollo
(Signal wird 1:1 vom BCM2 geroutet; ursprünglicher Sender: Rollo = LIN-Slave vom BCM2)";
CM_ SG_ 1504 MRollo_Position "Aktuelle Öffnungsweite des Dachrollos.";
CM_ SG_ 1504 Rollo_normiert "Anzeigen Normierung des Dachrollos";
CM_ SG_ 1504 Rollo_Thermoschutz "Anzeigen aktivierter Thermoschutz des Dachrollo";
CM_ SG_ 1504 Rollo_UEKB_aktiv "Anzeigen aktivierter Überschusskraftbegrenzung des Dachrollos";
CM_ SG_ 1504 SAD_Anf_ESC_Zuschaltung "Zwangsaktivierung ESP durch SAD-SG (bei geöffnetem Schiebedach und V> xx km/h).";
CM_ SG_ 1504 SAD_normiert "Anzeige Normierung des Schiebeausstelldaches";
CM_ SG_ 1504 SAD_ParityBit "SIL A Absicherung für die Signale: SAD_normiert, MD1_Lage, MD1_Position, SAD_Anf_ESC_Zuschaltung";
CM_ SG_ 1504 SAD_Taster_Deckel_hi "Taster für SAD Deckel hinten";
CM_ SG_ 1504 SAD_Taster_Deckel_vo "Taster für SAD Deckel vorne";
CM_ SG_ 1504 SAD_Taster_Rollo_hi "Taster für SAD Rollo hinten";
CM_ SG_ 1504 SAD_Taster_Rollo_vo "Taster für SAD Rollo vorne";
CM_ SG_ 1504 SAD_Text "Fehler Windabweiser in Abhängigkeit von der Geschwindigkeit";
CM_ SG_ 1504 SAD_Thermoschutz "Anzeige aktivierter Thermoschutz des Schiebeausstelldaches";
CM_ SG_ 1504 SAD_ToggleBit "SIL A Absicherung für die Signale: SAD_normiert, MD1_Lage, MD1_Position, SAD_Anf_ESC_Zuschaltung";
CM_ SG_ 1504 SAD_UEKB_aktiv "Anzeige aktivierter Überschusskraftbegrenzung des Schiebeausstelldaches";

CM_ SG_ 249 SARA_Nickwinkel "Nickwinkel des Fahrzeugs relativ zum Gravitationsvektor; 
Vorzeichen nach DIN70000";
CM_ SG_ 249 SARA_Wankwinkel "Wankwinkel des Fahrzeugs relativ zum Gravitationsvektor; 
Vorzeichen nach DIN70000";

CM_ SG_ 424 SARA_11_CRC "Für MLB:
'Berechnung siehe Lastenheft 'Kommunikationsabsicherung für Flexray und CAN''

Ab MQB und MLBevo:
'Berechnung siehe Lastenheft 'End-to-End Kommunikationsabsicherung'

Endwerte siehe Begleitdokument 'S-PDU Kennungsfolge'";
CM_ SG_ 424 SARA_Accel_X_r "Beschleunigung Acceleration-X routable:
- 0x0000= Sensor nicht verbaut, Signal wird nicht berechnet
- genutzter Wertebereich ± 640 m/s²

Filterung: 60 Hz Sensorfilter + 15 Hz uC-Filter (Cheby-II 3.Ordnung)";
CM_ SG_ 424 SARA_Accel_Y_r "Beschleunigung Acceleration-Y routable:
- 0x0000= Sensor nicht verbaut, Signal wird nicht berechnet
- genutzter Wertebereich ± 640 m/s²

Filterung: 60 Hz Sensorfilter + 15 Hz uC-Filter (Cheby-II 3.Ordnung)";
CM_ SG_ 424 SARA_CF_Accel_X_r "Confidence Faktor Beschleunigung Acceleration-X routable:

0=gültiger Wert
1=nicht belegt
2=nicht belegt
3=Temporärer Fehler {solange möglich werden aktuelle Sensorwerte gesendet, ansonsten 0xFFFF}
4=Init {0x8000 wird gesendet}
5=Sensor nicht verba";
CM_ SG_ 424 SARA_CF_Accel_Y_r "Confidence Faktor Beschleunigung Acceleration-Y routable:

0=gültiger Wert
1=nicht belegt
2=nicht belegt
3=Temporärer Fehler {solange möglich werden aktuelle Sensorwerte gesendet, ansonsten 0xFFFF}
4=Init {0x8000 wird gesendet}
5=Sensor nicht verba";
CM_ SG_ 424 SARA_CF_Omega_Z_r "Confidence Faktor Winkelgeschwindigkeit Omega-Z routable:

0=gültiger Wert
1=nicht belegt
2=nicht belegt
3=Temporärer Fehler {solange möglich werden aktuelle Sensorwerte gesendet, ansonsten 0xFFFF}
4=Init {0x8000 wird gesendet}
5=Sensor nicht verba";
CM_ SG_ 424 SARA_Omega_Z_r "Winkelgeschwindigkeit Omega-Z routable:
- 0x0000 = Sensor nicht verbaut, Signal wird nicht berechnet
- genutzter Wertebereich ± 320 Deg/s

Filterung: 60 Hz Sensorfilter + 15 Hz uC-Filter (Cheby-II 3.Ordnung)";

CM_ SG_ 1522 KBI_Dimmpoti "Signal wird benötigt für Dimmung im Audi B8. Der Signalfluss erfolgt vom Kombi an das BCM1.";
CM_ SG_ 1522 KBI_Phototransistor "Signal wird benötigt für die Dimmung von Such- Funktions- und Displaybeleuchtungen. Der Signalfluss erfolgt vom Steuergerät mit Fotosensor an die jeweiligen Dimmmaster-Steuergeräte.

Für Audi B8/Q5 und D4/C7/VW526 vor PA: 
0xFE Phototransistor nicht ve";

CM_ SG_ 2527679651 SM_Parken_blinken "Blinkerstatus ARA auf Smartphone";
CM_ SG_ 2527679651 SM_Parken_Hupe_Anf "Ansteuerung der Hupe beim PiloPa";
CM_ SG_ 2527679651 SM_Parken_Komfortschliessen_Anf "Anforderung für Komfortschließen der Fenster und des SAD (Schiebeaufstelldach) beim PiloPa";
CM_ SG_ 2527679651 SM_Parken_UGDO_Aktion "Ansteuerung des UGDO (Universal Garage Door Opener) beim PiloPa für:
- Garagentor öffnen oder toggeln (garagentorabhängig),
- Garagentor schließen,
- Garagentor stoppen (z. B. bei Gefahr),
- Status des Garagentors abfragen (Antwort ist UGDO_DoorState)";
CM_ SG_ 2527679651 SM_Parken_UGDO_Anf "Ansteuerung von bis zu 15 verschiedenen UGDOs (Universal Garage Door Opener) beim PiloPa";

CM_ SG_ 980 BH_Blinker_Fehler "Anzeige, ob am Lenkstockschalter ein Fehler anliegt.
Notwendig aufgrund ASIL-Einstufung";
CM_ SG_ 980 BH_Blinker_li "Blinkerhebel Richtung links";
CM_ SG_ 980 BH_Blinker_re "Blinkerhebel Richtung rechts";
CM_ SG_ 980 BH_Fernlicht "Betaetigung Fernlicht
";
CM_ SG_ 980 BH_Lichthupe "Betaetigung Lichthupe
";
CM_ SG_ 980 FAS_Taster "Betaetigung FAS Taster
";
CM_ SG_ 980 FAS_Taster_Fehler "Fehlerstatus FAS Taster
";
CM_ SG_ 980 LRH_aktiv "Signal gibt an, ob ein Heizstrom durch die Lenkradheizung fließt. Es dient der Auswertung durch das Energiemanagement.";
CM_ SG_ 980 LRH_On_Off "Status Lenkradheizung";
CM_ SG_ 980 SMLS_01_BZ "4bit Botschaftszaehler, wird mit jeder Sendebotschaft inkrementiert";
CM_ SG_ 980 SMLS_01_CRC "Für MLB:
'Berechnung siehe Lastenheft 'Kommunikationsabsicherung für FlexRay und CAN''

Ab MQB und MLBevo:
'Berechnung siehe Lastenheft 'End-to-End Kommunikationsabsicherung''

Endwerte siehe Begleitdokument 'S-PDU Kennungsfolgen'";
CM_ SG_ 980 SMLS_Hupe "Betaetigung Hupe
";
CM_ SG_ 980 SMLS_P_verriegelt_plausibel "Signal stellt den Plausibilisierungstatus des Signals p_verriegelt auf den Fahrzeugbus zur Verfügung. Eine Plausibilität muss explizit erkannt werden. Initial wird 'unplausibel' gesendet. Ein plausibles Signal wird erkannt, wenn p_verriegelt plausibel geg";
CM_ SG_ 980 SMLS_PTT "Betaetigung PTT";
CM_ SG_ 980 WH_Frontwaschen "Wischerhebel: Stellung Wisch Wasch vorne
";
CM_ SG_ 980 WH_Heckintervall "Wischerhebel: Stellung Heckintervall
";
CM_ SG_ 980 WH_Heckwaschen "Wischerhebel: Stellung Wisch Wasch hinten
";
CM_ SG_ 980 WH_Intervall "Wischerhebel: Stellung Intervall
";
CM_ SG_ 980 WH_Intervallstufen "Wischerhebel: Stellung Intervallstufen";
CM_ SG_ 980 WH_SRA "Scheinwerferreinigungsanlage

derzeit nur bei PAG umgesetzt";
CM_ SG_ 980 WH_Tipwischen "Wischerhebel: Tippwischen

MQB A0/ PQ26: Bei Verbau LSS (kein SMLS): gespiegelter Wert zu Signal WH_WischerStufe1";
CM_ SG_ 980 WH_Tipwischen_lang "Wischerhebel: Tippwischen lang
(dient zur Auswertung für die Unterscheidung Tippwischen oder Serviceposition Wischer)";
CM_ SG_ 980 WH_Wischer_Fehler "Anzeige, ob am Lenkstockschalter ein Fehler anliegt.
Notwendig aufgrund ASIL-Einstufung";
CM_ SG_ 980 WH_WischerStufe1 "Wischerhebel: Stufe Wischen 1
";
CM_ SG_ 980 WH_WischerStufe2 "Wischerhebel: Stufe Wischen 2
";

CM_ SG_ 1467 SoSe_SunInt_2D_Li "Sonnenintensität links (2D Sensor)";
CM_ SG_ 1467 SoSe_SunInt_2D_Re "Sonnenintensität rechts (2D Sensor)";

CM_ SG_ 1710 SP_abklappen "Spiegel abklappen";
CM_ SG_ 1710 SP_anklappen "Spiegel anklappen";
CM_ SG_ 1710 SP_ARA_Status "Rückkanal TSG im ARA-Modus";
CM_ SG_ 1710 SP_Auswahl_li "Spiegelschalter in Stellung Auswahl links";
CM_ SG_ 1710 SP_Auswahl_re "Spiegelschalter in Stellung Auswahl rechts";
CM_ SG_ 1710 SP_BT_links "Spiegel Beifahrertür nach links";
CM_ SG_ 1710 SP_BT_oben "Spiegel Beifahrertür nach oben";
CM_ SG_ 1710 SP_BT_rechts "Spiegel Beifahrertür nach rechts";
CM_ SG_ 1710 SP_BT_unten "Spiegel Beifahrertür nach unten";
CM_ SG_ 1710 SP_FT_links "Spiegel Fahrertür nach links";
CM_ SG_ 1710 SP_FT_oben "Spiegel Fahrertür nach oben";
CM_ SG_ 1710 SP_FT_rechts "Spiegel Fahrertür nach rechts";
CM_ SG_ 1710 SP_FT_unten "Spiegel Fahrertür nach unten";
CM_ SG_ 1710 SP_Hzg_Taster "Heizungstaster/schalter aktiv";
CM_ SG_ 1710 SP_normieren "Spiegel normieren";
CM_ SG_ 1710 SP_S_Klappen "Spiegelschalter in Stellung Klappen";
CM_ SG_ 1710 SP_S_links "Spiegelschalter in Stellung links";
CM_ SG_ 1710 SP_S_oben "Spiegelschalter in Stellung oben";
CM_ SG_ 1710 SP_S_rechts "Spiegelschalter in Stellung rechts";
CM_ SG_ 1710 SP_S_unten "Spiegelschalter in Stellung unten";
CM_ SG_ 1710 SP_Verstellschalter_Fehler "Erkennung eines hängenden Spiegelverstellschalters";

CM_ SG_ 1313 STH_EKP_Anst "STH sendet die Anforderung zur Ansteuerung der EKP an den Motor, um Kraftstoffbehälter der STH zu befüllen.";
CM_ SG_ 1313 STH_Fehler_ElWaPu "Fehler der el. Zusatzwasserpumpe der zur Deaktivierung der Wasserpumpe führt ";
CM_ SG_ 1313 STH_Fehlerstatus "Übermittlung der unterschiedlichen Fehlerzustände der Standheizung";
CM_ SG_ 1313 STH_Funk_aus "Funkbefehl über Funkfernbedienung zum Ausschalten Standheizung";
CM_ SG_ 1313 STH_Funk_ein "Funkbefehl über Funkfernbedienung zum Einschalten Standheizung";
CM_ SG_ 1313 STH_Geblaese "Ein-/ Ausschaltbefehl an die Klimaanlage, Gebläse";
CM_ SG_ 1313 STH_Heizleistung "Heizleistung in %";
CM_ SG_ 1313 STH_KL_HUP "Signal HUP Aktivierung an Klima

0 = HUP aus
1 = HUP ein";
CM_ SG_ 1313 STH_KVS "Kraftstoffverbrauch";
CM_ SG_ 1313 STH_KVS_Ueberlauf "Kraftstoffverbrauch, Überlauf hat stattgefunden";
CM_ SG_ 1313 STH_LED "Funktionslampe";
CM_ SG_ 1313 STH_Motorvorwaermung "Info an der Motor, dass der Aufheizvorgang mit Motorvorwärmung erfolgt ist";
CM_ SG_ 1313 STH_Pumpen_Anf_extern "Anforderung der motorseitigen elektr. (externen) Wasserpumpe zur Kreislaufunterstützung im Standheizbetrieb";
CM_ SG_ 1313 STH_Servicemode "Rückmeldung, dass die Standheizung sich gerade im Diagnosemodus befindet, gestartet über Diagnosetester";
CM_ SG_ 1313 STH_SH_ZH "0 = Heizgerät ist Standheizung
1 = Heizgerät ist Zuheizer
Gerätekennung WZH oder ZH
";
CM_ SG_ 1313 STH_Start_folgt "Thema Start/Stop: Im Stop-Modus muß das KBT einen Wiederstart anfordern, da ein STH-Start notwendig ist.";
CM_ SG_ 1313 STH_Texte "Anforderung der unterschiedlichen Anzeigetexte im Mitteldisplay des Kombi.

0: Keine Anzeige
1: Kein Standheizungs- bzw Lueftungsbetrieb wegen Batteriemanagementeinschraenkung
2: Kein Standheizungs- bzw Lueftungsbetrieb wegen Kraftstoffmangels
3: Kei";
CM_ SG_ 1313 STH_Ventil_Status "Statusrückmeldung Ansteuerung 3/2 Wege-Ventil";
CM_ SG_ 1313 STH_Ventiloeffnungszeit "Die Standheizung sendet an den Motor die Information darüber wie lange das Magnetventil die Wasserkreisläufe von 'klein' aus 'gross' geschaltet hat. ";
CM_ SG_ 1313 STH_Waermeeintrag "Signal enthält die Brenndauer in 1min-Schritten, über welche die Standheizung gelaufen ist";
CM_ SG_ 1313 STH_war_aktiv "Bit beeinhaltet die Info, dass die Standheizung während der letzten halbe Stunde aktiv war.";
CM_ SG_ 1313 STH_Wassertemp "Kühlmitteltemperatur der Standheizung";
CM_ SG_ 1313 STH_Zusatzheizung "Kraftstoffzuheizer aktiv";

CM_ SG_ 1650 STH_ZZ_Betriebsdauer "Betriebsdauer der Standheizung, die über die Funkfernbedienung verändert wurde";
CM_ SG_ 1650 STH_ZZ_Betriebsmodus "Betriebsdauerberechnung anhand Aussentemperaturauswertung mit Faktor 'ZZ_Betriebsmodus'";
CM_ SG_ 1650 STH_ZZ_Minute "Zielzeittimeranzeige im Display des MMI (Minute); Initwert ist der zuletzt gültige Wert";
CM_ SG_ 1650 STH_ZZ_Monat "Zielzeittimeranzeige im Display des MMI (Datum, Monat); Initwert ist der zuletzt gültige Wert";
CM_ SG_ 1650 STH_ZZ_Status_Timer "Zielzeittimeranzeige im Display des MMI (Timer aktiv/n.aktiv)";
CM_ SG_ 1650 STH_ZZ_Stunde "Zielzeittimeranzeige im Display des MMI (Stunde); Initwert ist der zuletzt gültige Wert";
CM_ SG_ 1650 STH_ZZ_Tag "Zielzeittimeranzeige im Display des MMI (Datum, Tag); Initwert ist der zuletzt gültige Wert";

CM_ SG_ 505 ACA_HF_Grund_AV_AB "Abschaltbedingung und Aktivierverhinderung";
CM_ SG_ 505 ACA_HF_Status "Status der Hands-Off-Querfuehrung";
CM_ SG_ 505 ACA_QF_Fahreruebernahme "Anforderung einer Fahrerübernhame durch die ACA Querführung für die HMI Ansteuerung im ACC-SG";
CM_ SG_ 505 ACA_QF_Status_Anzeige "Status der ACA Querführung, angepasst für die HMI Ansteuerung im ACC-SG";
CM_ SG_ 505 ACF_Spurwechsel_moeglich "Spurwechselmöglichkeit in Überholrichtung (verkehrssinnabh.) gegeben";
CM_ SG_ 505 ACF_Spurwechsel_wahrscheinlich "Spurwechsel in Überholrichtung (verkehrssinnabh.) wahrscheinlich";
CM_ SG_ 505 ACF_SwuFahrerUnaufmerksam "Erkannte Fahrerunaufmerksamkeit von der FZE (ACF)";
CM_ SG_ 505 FZE_Spurwechsel_erkannt_li "Spurwechsel nach links erkannt.";
CM_ SG_ 505 FZE_Spurwechsel_erkannt_re "Spurwechsel nach rechts erkannt.";
CM_ SG_ 505 FZE_STP_Abschaltbedingung "Es liegt eine FZE Bedienhandlung für eine Abschaltung vor";
CM_ SG_ 505 FZE_STP_Aktivierverhinderung "Aktivierverhinderungen STP aus Sicht der FZE";
CM_ SG_ 505 FZE_STP_Status "'Initialisierung / Auskodiert
FZE_STP Signale können verwendet werden
Es liegt ein reversibler Fehler für STP Signale vor
Es liegt ein irreversibler Fehler für STP Signale vor'
";
CM_ SG_ 505 STP_03_BZ "Botschaftszähler
Botschaft asynchron geroutet. Zählerwert kann springen.";
CM_ SG_ 505 STP_03_CRC "End-to-End Absicherung";
CM_ SG_ 505 STP_Funktion_freigegeben "Gibt in ASIL D an, ob die Funktion Staupilot zum Betrieb freigegeben ist.";
CM_ SG_ 505 STP_Notlaufaktivierung "Aktivierung des Notlaufs im ESC/EBKV durch den STP";
CM_ SG_ 505 STP_Slave_Status "Zustandsbeschreibung für STP-Slave-State-Machine";

CM_ SG_ 1172 GW_STS2_Privatsphaere "Übertraegt den Status der Privatsphaere vom ZR/MIB an das Steuergeraet VTS (STS2).";
CM_ SG_ 1172 STS_01_BZ "4bit Botschaftszähler, wird in jeder Sendebotschaft inkrementiert
";
CM_ SG_ 1172 STS_01_CRC "Für MLB:
'Berechnung siehe Lastenheft 'Kommunikationsabsicherung für FlexRay und CAN''

Ab MQB und MLBevo:
'Berechnung siehe Lastenheft 'End-to-End Kommunikationsabsicherung''

Endwerte siehe Begleitdokument 'S-PDU Kennungsfolgen'";
CM_ SG_ 1172 STS_Alarm_Blinker "Taxialarmblinken, wie DWA ohne Fanfare";
CM_ SG_ 1172 STS_Alarm_still "VTS hat einen Alarm erkannt. Alarm ist aber noch nicht bestätigt.";
CM_ SG_ 1172 STS_Anlassersperre "Wiederstartverhinderung (Anlassersperre)";
CM_ SG_ 1172 STS_Door_Lock "Remote Door lock angefordert: ZV zu/verriegeln";
CM_ SG_ 1172 STS_Fahrlicht "statisch oder auch mit Blink_modi für interm. Fahrlicht";
CM_ SG_ 1172 STS_Laderelais "Signal für die Auswertung zur Anzeige der Batterie-Schwach-Anzeige im Kombi ";
CM_ SG_ 1172 STS_Leerlaufschaltung "Versetzt das Fahrzeug in einen Zustand in dem es nicht mehr auf EGas-Anforderungen reagiert";
CM_ SG_ 1172 STS_LIN_aktiv "Tracking System über LIN";
CM_ SG_ 1172 STS_Notstart "Signal zeigt an, dass ein Notstart erfolgte.";
CM_ SG_ 1172 STS_Signalhorn "Versehrte, Fahrschule oder Taxi (bei Alarm)";
CM_ SG_ 1172 STS_Spiegel_Anklappen "Anklappen der Außenspiegel über Remote MOD Anforderung";
CM_ SG_ 1172 STS_Standlicht "statisch oder auch mit Blink_modi für Taxialarm";
CM_ SG_ 1172 STS_Summer "Warnsummer für Funkhauptschalter und Fahrschulpedal";
CM_ SG_ 1172 STS_Texte "Nummer des Textes die im Kombi angezeigt werden soll.

Signalwert ---- Meldungstext Audi ---- Meldungstext PAG:
0x0, kein_Text ---- kein Text ---- kein Text
0x1, Text_01 ---- kein Text ---- Driver Card nicht erkannt
0x2, Text_02 ---- Ortungsassistent";
CM_ SG_ 1172 STS_Typencodierung "Typcodierung Schnittstelle für Tracking Systeme
";

CM_ SG_ 783 ASW_Kombitexte "ASW_Kombitexte bestimmt welcher Text im Kombi angezeigt wird. Darüber hinaus werden auch Kombi-Akkustik durch dieses Signal ausgelöst.

Dieses Signal ersetzt SWA_Anzeigen für den ASW-Anteil. Der SWA-Anteil des alten Signals findet sich in SWA-Kombitexte";
CM_ SG_ 783 ASW_Modus "gibt die Verfügbarkeit der ASW Modus an";
CM_ SG_ 783 ASW_Status "Funktionsstatus Ausstiegswarnung (ASW)";
CM_ SG_ 783 ASW_Warnung_BFS "Modus Beifahrerseite der Funktion Ausstiegswarnung (ASW)";
CM_ SG_ 783 ASW_Warnung_FS "Modus Beifahrerseite der Funktion Ausstiegswarnung (ASW)";
CM_ SG_ 783 Heckradar_Kombitexte "Heckradar_Kombitexte bestimmt welcher Text im Kombi angezeigt wird. Darüber hinaus werden auch Kombi-Akkustik durch dieses Signal ausgelöst.

Dieses Signal ersetzt SWA_Anzeigen und deckt alle Kombinationsmöglichkeiten der Heckradarfunktionen ab. Die Fun";
CM_ SG_ 783 HRE_Anzeigetexte "HRE-Texte und -Akustik zur Anzeige im Kombiinstrument";
CM_ SG_ 783 RCTA_Kombitexte "RCTA_Kombitexte bestimmt welcher Text im Kombi angezeigt wird. Darüber hinaus werden auch Kombi-Akkustik durch dieses Signal ausgelöst.";
CM_ SG_ 783 SWA_01_BZ "Fehlende Beschreibung (Import)
Botschaft asynchron geroutet. Zählerwert kann springen.";
CM_ SG_ 783 SWA_01_CRC "Für MLB:
'Berechnung siehe Lastenheft 'Kommunikationsabsicherung für FlexRay und CAN''

Ab MQB und MLBevo:
'Berechnung siehe Lastenheft 'End-to-End Kommunikationsabsicherung''

Endwerte siehe Begleitdokument 'S-PDU Kennungsfolgen'";
CM_ SG_ 783 SWA_Anzeigen "SWA- Texte und -Akustik zur Anzeige im Kombiinstrument
0x7-0xF = reserviert";
CM_ SG_ 783 SWA_Blindheit_erkannt "SWA erkennt selbständig eigene Blindheit durch äußere Einflüsse.";
CM_ SG_ 783 SWA_FT_RueckLED "SWA/ASW Rückmelde-LED. Zeigt den Aktivierungszustand der Funktionen SWA/ASW";
CM_ SG_ 783 SWA_Infostufe_SWA_li "Aktion der SWA-Funktion auf der entsprechenden Fahrzeugseite";
CM_ SG_ 783 SWA_Infostufe_SWA_re "Aktion der SWA-Funktion auf der entsprechenden Fahrzeugseite";
CM_ SG_ 783 SWA_Kolonne_li "Info, dass auf der entspr. Spur mehr als zwei Fahrzeuge zu finden sind. ";
CM_ SG_ 783 SWA_Kolonne_mi "Info, dass auf der entspr. Spur mehr als zwei Fahrzeuge zu finden sind. ";
CM_ SG_ 783 SWA_Kolonne_re "Info, dass auf der entspr. Spur mehr als zwei Fahrzeuge zu finden sind. ";
CM_ SG_ 783 SWA_Modus "gibt die Verfügbarkeit der SWA Modus an";
CM_ SG_ 783 SWA_rel_Fehler "Hinweis: In Zukunft das Signal SWA_Modus anstatt SWA_rel_Fehler verwenden!

SWA erkennt einen Fehler, die Objektdetektion betreffend, mit FSP-Eintrag.";
CM_ SG_ 783 SWA_rel_Nichtverf "Hinweis: In Zukunft das Signal SWA_Modus anstatt SWA_rel_Nichtverf verwenden!

SWA erkennt eine Nichtverfuegbarkeit, die Objektdetektion betreffend, ohne FSP-Eintrag";
CM_ SG_ 783 SWA_Sta_aktiv "SWA Status aktiv; Lampenansteuerung im Kombi";
CM_ SG_ 783 SWA_Sta_passiv "Hinweis: In Zukunft das Signal SWA_Status anstatt SWA_Sta_passiv verwenden!

SWA Status passiv; Lampenansteuerung im Kombi";
CM_ SG_ 783 SWA_Standziele_li "Hinweis: In Zukunft das Signal SWA_StrukturLinks_querAbstand anstatt SWA_Standziele_li verwenden!

Abstand zwischen Fahrzeug und Standziele links geringer als ein applizierbarer Wert.";
CM_ SG_ 783 SWA_Standziele_re "Hinweis: In Zukunft das Signal SWA_StrukturRechts_querAbstand anstatt SWA_Standziele_re verwenden!

Abstand zwischen Fahrzeug und Standziele links geringer als ein applizierbarer Wert.";
CM_ SG_ 783 SWA_Status_02 "gibt die Verfügbarkeit der SWA_Status an";
CM_ SG_ 783 SWA_Warnung_SWA_li "Aktion der SWA-Funktion auf der entsprechenden Fahrzeugseite";
CM_ SG_ 783 SWA_Warnung_SWA_re "Aktion der SWA-Funktion auf der entsprechenden Fahrzeugseite";

CM_ SG_ 673 SWA_LED_Hell_BFS "Helligkeitswert SWA LED Beifahrerseite";
CM_ SG_ 673 SWA_LED_Hell_FS "Helligkeitswert SWA LED Fahrerseite";
CM_ SG_ 673 SWA_LED_Modus_BFS "Ansteuerung SWA LED Beifahrerseite";
CM_ SG_ 673 SWA_LED_Modus_FS "Ansteuerung SWA LED Fahrerseite";

CM_ SG_ 1413 GW_KD_Fehler "Kundendienstfehlerbit Gateway zur Anzeige eines im Gateway abgelegten Fehlerspeichereintrages.";
CM_ SG_ 1413 SI_BUS_01 "MQB/MQB_A0/PQ26: ACAN
MQB2020: ACAN(FD)
MLBevo: HCAN
E3_Volumen: ACAN(FD)
MQBw_Baseline: ACAN(FD)";
CM_ SG_ 1413 SI_BUS_02 "MQB/MQB A0 Standard+, High: FCAN
MQB2020: FCAN(FD)
MLBevo: Frei
E3_Volumen: FCAN(FD)
MQBw_Baseline: FCAN(FD)";
CM_ SG_ 1413 SI_BUS_03 "MQB/MQB A0/PQ26: KCAN
MQB2020: KCAN
MLBevo: KCAN
E3_Volumen: KCAN(HS) / K2CAN(FD) (Buskopplung)
MQBw_Baseline: KCAN(HS)";
CM_ SG_ 1413 SI_BUS_04 "MQB/MQB A0 Standard+, High: ICAN
MQB2020: ICAN(HS)
MLBevo: ICAN
E3_Volumen: ABCAN(FD)
MQBw_Baseline: ICAN(HS)";
CM_ SG_ 1413 SI_BUS_05 "MQB/MQB A0/PQ26: DiagCAN
MQB2020: DiagCAN(FD)
MLBevo: DiagCAN
E3_Volumen: DiagCAN(FD)
MQBw_Baseline: DiagCAN(FD)";
CM_ SG_ 1413 SI_BUS_06 "MQB/MQB A0/PQ26: ECAN
MQB2020: FASCAN(FD)
MLBevo: ECAN
E3_Volumen: FASCAN_1(FD)
MQBw_Baseline: FASCAN_1(FD)";
CM_ SG_ 1413 SI_BUS_07 "MQB: LIN1 (Energie)
MQB2020: LIN1 (Energie)
MLBevo: LIN1 (Energie)
E3_Volumen: LIN 1 (Energie)
MQBw_Baseline: LIN1 (Energie)";
CM_ SG_ 1413 SI_BUS_08 "MQB: LIN2 (MFL)
MQB2020: LIN2 (MFL)
MLBevo: LIN2 (MFL)
E3_Volumen: LIN2 (MFL)
MQBw_Baseline: LIN2 (MFL)";
CM_ SG_ 1413 SI_BUS_09 "MQB: LIN3 (unbelegt)
MQB2020: LIN3 (Uhr/FES)
MLBevo: LIN3 (Energie2)
MEB: LIN3
E³ 1.1 UNECE: MDKCAN";
CM_ SG_ 1413 SI_BUS_10 "MLBevo: Flexray
MQB2020: MCAN
MQBw_Baseline: FASCAN_2(FD)
E³ 1.1 UNECE: FASCAN_2(FD)";
CM_ SG_ 1413 SI_BUS_11 "MLBevo: Ethernet
MEB: LIN4";
CM_ SG_ 1413 SI_BUS_12 "MQB: unbelegt
MLBevo: K2CAN
E3_Volumen: MFLCAN
MQBw_Baseline: K2CAN(FD)";
CM_ SG_ 1413 SI_BUS_13 "MQB: unbelegt
MLBevo: DCAN
MEB: CCAN
MQBw_Baseline: K3CAN(FD)";
CM_ SG_ 1413 SI_BUS_14 "MQB/MQB A0: unbelegt
MQB2020: HCAN
MLBevo: CCAN
E3_Volumen: EVCAN(FD)
MQBw_Baseline: EVCANFD(FD)";
CM_ SG_ 1413 SI_BUS_15 "MQB: frei
MQB2020: frei
MLBevo: frei
MEB: AFSCAN";
CM_ SG_ 1413 SI_Bus_Identifikation "Das Signal identifiziert den Bus eindeutig. Das Signal ist konstant auf jedem Bus.
Der Signalwert entspricht dem Wert 'Busnummer' aus der VW80127 Gateway_component_list_databus_identification (0x2A2D) 'Bus-Identifier'.";
CM_ SG_ 1413 SI_CAB "CAB = Clusteraktivbits 
(Verwendung nur für Empfänger die nicht den AutoSar-SSW Stack implementiert haben)";
CM_ SG_ 1413 SI_Diagnose_Aktiv "Gibt an ob Diagnose-Botschaften empfangen werden und somit eine Diagnose aktiv ist.
MQB: Gibt an ob Diagnose-Bus Botschaften empfangen werden und somit eine Diagnose aktiv ist.";
CM_ SG_ 1413 SI_NWDF "Netzwerk-Diagnose Freigebe zur zentralen Aktivierung der Netzwerkdiagnose";
CM_ SG_ 1413 SI_NWDF_gueltig "Gültigkeitsbit zu SI_NWDF gemäß Lastenheft: Zentrale Aktivierung Netzwerkdiagnose";
CM_ SG_ 1413 SI_QRS_Mode "Messmodus Quick-Ruhestrom";
CM_ SG_ 1413 SI_Sammel_SG_Fehler "Anzahl der gesetzten KD-Fehler direkt angeschlossener Steuergeräte der DK3 und DK4 gemäß 80127.
Hinweis: Ein Subbusmaster stellt nur die gesammelte Information der an ihn angeschlossenen Steuergeräte der DK3 und DK4 zur Verfügung.

Für ServiceKey Auswe";
CM_ SG_ 1413 SI_Sammelfehler "Sammelfehlermeldung zur Anzeige im Kombi - siehe Spez. Sammelfehlermeldung
Hinweis: Einzelne Steuergeräte können zur Anpassung an den Produktionsprozess im Gateway auskodiert werden!";
CM_ SG_ 1413 SI_T_Mode "0x0: Transportmodus nicht aktiv
0x1: Transportmodus aktiv";
CM_ SG_ 1413 SI_T_Schutz "Transportschutz-Signal, das bei Transportmodus und Motorlauf aktiv bleibt
0x0: Transportschutz nicht aktiv
0x1: Transportschutz aktiv";

CM_ SG_ 1015 KL_HV_Energie_Anf "Anforderung HV - Energiebedarf, für VoKo 
";
CM_ SG_ 1015 TME_EKK_Fehlerstatus "aktueller Fehlerstatus des EKK";
CM_ SG_ 1015 TME_EKK_Istmodus "aktuelle IstModus des elektrischen Klimakompressors";
CM_ SG_ 1015 TME_HVEM_HV_Anf "Anforderung 'HV-Netz aktivieren' wegen Innenraumkonditionierung mit HV-Komponente";
CM_ SG_ 1015 TME_HVK_EKK_SOLL "Anforderung an HVK den HV EKK abzuschalten.";
CM_ SG_ 1015 TME_HVPTC_Fehlerstatus "aktueller Fehlerstatus des HVPTC";
CM_ SG_ 1015 TME_HVPTC_Istmodus "aktuelle Ist-Betriebsart der HV-PTC";
CM_ SG_ 1015 TME_Kuehlerluefer_3 "Soll-PWM für Lüfter3";
CM_ SG_ 1015 TME_OBD_Lampe_Anf "MIL-Request durch TME-Steuergerät";
CM_ SG_ 1015 TME_PWM_Pumpe1_tNT_Soll "Soll-PWM für Pumpe 1 im Tiefniedertemperaturkreis";
CM_ SG_ 1015 TME_StartStopp_Info "Stopp-Freigabe und Start-Anforderung an den Start-Stopp-Koordinator";
CM_ SG_ 1015 TME_StartStopp_Info_Prio "Priorität der Stopp-Freigabe und Start-Anforderung an den Start-Stopp-Koordinator";
CM_ SG_ 1015 TME_Strom_Kuehlerluefter "aktueller Kühlerlüfterstrom, +-20% ";

CM_ SG_ 1017 TME_Anf_KL "Max. Kühlerlüfteransteuerung der TME in %";
CM_ SG_ 1017 TME_EM1_IstVolumenstrom "Aktueller Ist-Wert des Vorlaufvolumenstromes LE/EM 1";
CM_ SG_ 1017 TME_EM2_IstVolumenstrom "Aktueller Ist-Wert des Vorlaufvolumenstromes LE/EM 2";
CM_ SG_ 1017 TME_EM3_IstVolumenstrom "Aktueller Ist-Wert des Vorlaufvolumenstromes LE/EM 3";
CM_ SG_ 1017 TME_Fehler_ElWaPu1 "Fehler der el. Zusatzwasserpumpe der zur Deaktivierung der Wasserpumpe führt";
CM_ SG_ 1017 TME_MMTR_Status "Status der Funktion Make me track ready für die Anzeige im Zentraldisplay";
CM_ SG_ 1017 TME_Nachlaufzeit "Nachlaufzeit TME für SKE am MSG";
CM_ SG_ 1017 TME_NT_Kreis_Status "Status gibt an ob der NT Kreis funktional i.O ist. (Komponenten i.O)";
CM_ SG_ 1017 TME_Pumpe1_Status "Rückmeldung des Heizungspumpenstatus";
CM_ SG_ 1017 TME_PWM_Pumpe2_HK_Soll "Soll-PWM für Heizkreispumpe vor Motorchiller";
CM_ SG_ 1017 TME_Status_KL "Fehlerstatus des Kühlerlüftermodules";
CM_ SG_ 1017 TME_Ventil1_Status "Statusrückmeldung Ansteuerung 3/2 Wege-Ventil";

CM_ SG_ 1375 TME_Absperrventil1_oeffnen "Signal an Standheizungs-SG das Absperrrventil anzusteuern";
CM_ SG_ 1375 TME_AC_LED "Steuerung der LED in der AC-Taste des KBTs";
CM_ SG_ 1375 TME_AC_Rueckmeldung "Status des Elektrischen Klimakompressors";
CM_ SG_ 1375 TME_Freigabe_Luft_PTC "Freigabe des Zuheizers im Klimagerät";
CM_ SG_ 1375 TME_Freigabe_Vorkond "Freigabe an das KBT, mit dem Innenraumkonditionieren zu beginnen.";
CM_ SG_ 1375 TME_Frischluftklappe_Soll "Sollvorgabe der Frischluftklappenstellung bei speziellem Heizbetrieb, z.B. Wärmepumpe";
CM_ SG_ 1375 TME_Heizstrategie "Info über aktuelle Heizstrategie an KBT";
CM_ SG_ 1375 TME_Heizungspumpen_Anst "Anforderung Heizungspumpenansteuerung";
CM_ SG_ 1375 TME_Kbr_Innenraum "Vorhandensein der Klimabereitschaft für Innenraum";
CM_ SG_ 1375 TME_Klima_Defizit "Für Innennraumklimatisierung aktuell nicht verfügbare  Leistung (Defizit = Istleistung - Solleistung)";
CM_ SG_ 1375 TME_Kuehlmittel_Sensor "Signal der Sensorelektroden für die Kühlmittelreserve aktuell, entstört, bewertet (OK/Mangel)
Signalaenderung BEV: Zusaetzlich zum Kuehlmittelsensor werden Fehler an Wasserpumpe des Kuehlsystems auf das Fehlerbit gemappt.";
CM_ SG_ 1375 TME_Nachlaufzeit_Heizp "Nachlaufzeit für Heizungspumpe";
CM_ SG_ 1375 TME_Systemstatus "Systemstatus der TME";
CM_ SG_ 1375 TME_Temp_KM_vor_HWT "Kühlmitteltemperatur vor HWT";
CM_ SG_ 1375 TME_Umluftklappe_Soll "Sollvorgabe der Umluftklappenstellung bei speziellem Heizbetrieb, z.B. Wärmepumpe";
CM_ SG_ 1375 TME_Verdampfer_Status "Verdampfer wird vom Kältemittel durchströmt";
CM_ SG_ 1375 TME_VoKo_Strategie_Anzeige "rueckgemeldete VoKo-Strategie fuer Anzeige
";
CM_ SG_ 1375 TME_Waermepumpe_aktiv "Aktivierungszustand der Wärmepumpe für Innenraumheizen";
CM_ SG_ 1375 TME_Zuheizer_Freigabe "Freigabe-Signal für Verbrennungszuheizfunktion";

CM_ SG_ 1373 TME_Geblaese "Aktivierung des Klimagebläses für Innenraumkonditionierung";
CM_ SG_ 1373 TME_IstSpannung_EKK_HV "Vom EKV gemessene HV-Spannung";
CM_ SG_ 1373 TME_Klimadefizit "Erkanntes Leistungsdefizit für die Klimatisierung";
CM_ SG_ 1373 TME_Kond_Innen_Betrieb "Funktionsrückmeldung über Betriebsstatus (an/aus) als Anzeige bzw  Kundenrückmeldung.";
CM_ SG_ 1373 TME_Kond_Innen_Betriebsdauer "Signal beeinhaltet die Zeitdauer welche vom TME_Steuergerät für die entsprechende Konditionierungsmaßnahme des Innenraumes errechnet wurde.
Die Dauer dient zur Aktivierung der entsrpechenden Komponenten und zur Anzeige im HMI.";
CM_ SG_ 1373 TME_Kond_Innen_Status "Innenraumkonditionierung ist möglich/n.möglich (wegen Komponentendefekt bzw-einschränkung)
Information wird zwecks Einschränkung/Freigabe der  Menübedienbarkeit im MMI benötigt.";
CM_ SG_ 1373 TME_Kuehlmittel_Temp_Pumpe1_tNT "Kühlwassertemperatur nach Batteriekreispumpe";
CM_ SG_ 1373 TME_SKE_Status_2 "Statusinformation über den Zustand der Kühlerjalousie 2";
CM_ SG_ 1373 TME_STH_aktiv "Funktionsrückmeldung für Standheizung aktiv";
CM_ SG_ 1373 TME_STH_Ansteuerung "Einschaltbefehl an die Standheizung seitens TME/Wärmepumpensteuergerät ";
CM_ SG_ 1373 TME_STH_Status "Verfügbarkeitsinformation über den Standheizungsbetrieb.
Information für MMI-Lade-Menü-bedienbarkeit";
CM_ SG_ 1373 TME_STL_aktiv "Funktionsrückmeldung Standlüftung aktiv ";
CM_ SG_ 1373 TME_Temp_KM_vor_LE "Kuehlmittelvorlauftemperatur vor der Leistungselektronik";
CM_ SG_ 1373 TME_Thermomanagement "Stufen des Thermomanagement";
CM_ SG_ 1373 TME_Verdampfertemperatur "Istwert der Verdampfertemperatur  (Verdampfer hängt am TME C7PHEV)";

CM_ SG_ 1657 TME_Eingriff_SKE_Oeffnung "TME Anforderung zur Öffnung der SKE";
CM_ SG_ 1657 TME_EKK_ProtectionMode "Bei akuter Ueberhitzungsgefahr des elektrischen Klimakompressors wird der ProtectionMode aktiviert.";
CM_ SG_ 1657 TME_Klimaanforderung "Anforderungsgrund der Klimaapplikation durch die TME";
CM_ SG_ 1657 TME_Klimaleistung "Leistung des elektrischen Klimakompressors";
CM_ SG_ 1657 TME_SKE_Pos_Summe "Aerodynamisch wirksamer Gesamtöffnungswinkel der am TME angeschlossenen Kühlerjalousiesteller.";
CM_ SG_ 1657 TME_SKE_Position_1 "Position der SKE 1

0 => Geöffnet
1 => Teilgeschlossen
2 => Geschlossen
3 => Init / Anforderung Initialisierung / Anforderung Referenzierung / Fehler heilen";
CM_ SG_ 1657 TME_SKE_PosResp "Rückmeldung SKE Position erreicht";
CM_ SG_ 1657 TME_SKE_Status "Status Information über den Zustand der SKE";
CM_ SG_ 1657 TME_Status_Kuehlmittel_Tmp_CrChk "Status des Cross Checks der Kuehlmitteltemperaturen von TME und MSG";
CM_ SG_ 1657 TME_Systemtemp "Systemtemperatur Antriebe für Kombi";
CM_ SG_ 1657 TME_TCP_Kond_active "Info über eine aktive HV-Batterie Konditionierung welche durch den Turbo Charging Planer ausgelöst wurde";
CM_ SG_ 1657 TME_Temp_KM_nach_EM "Momentanwert Kuehlmitteltemperatur nach E-Maschine";
CM_ SG_ 1657 TME_Temp_KM_vor_eATL "Kühlwassertemperatur vor eATL";
CM_ SG_ 1657 TME_Temperatur_Ruecklauf_VKM "Kühlmitteltemperatur Rücklauf VKM";
CM_ SG_ 1657 TME_Waermebilanz "TME bilanziert die Wärmeentnahme aus VKM";
CM_ SG_ 1657 TME_Waermebilanz_Status "Diagnosestatus zur Wärmebilanz. OBDI berücksichtigt die elektrischen Diagnosen. OBDII berücksichtigt die funktionalen Diagnosen bzw. Sensorwertplausibilisierung.";

CM_ SG_ 977 ASW_Warnung_aktiv_BFS "Abschaltung der Ambientefunktion Beifahrertür bei aktiver ASW Warnung an der Fahrertür";
CM_ SG_ 977 BFS_Status_eTAG "Status des elektrischen Tueraussengriffes Beifahrertuer";
CM_ SG_ 977 BT_ASW_HMI_defekt "Zeigt an, ob die ASW-Anzeige defekt ist.";
CM_ SG_ 977 BT_EC_Spiegel_Helligkeit "Dimmung für den Aussenspiegel in %";
CM_ SG_ 977 BT_FH_Bew_hoch "Fensterheber in Bewegung Richtung hoch";
CM_ SG_ 977 BT_FH_Bew_tief "Fensterheber in Bewegung Richtung tief";
CM_ SG_ 977 BT_FH_Block "Fensterscheibe befindet sich im mechanischen Block (oben oder unten)";
CM_ SG_ 977 BT_FH_Fang "Fangbereich ist 4mm von oberer Lippendichtung";
CM_ SG_ 977 BT_FH_normiert "Die Position der Fensterheberscheibe ist bekannt";
CM_ SG_ 977 BT_FH_Oeffnung "Gibt den Fensteröffnungswert in % an.";
CM_ SG_ 977 BT_FH_S_AutoHoch "FH Schalter automatisch hoch gedrückt";
CM_ SG_ 977 BT_FH_S_AutoTief "FH Schalter automatisch tief gedrückt";
CM_ SG_ 977 BT_FH_S_ManHoch "FH Schalter manuell hoch gedrückt";
CM_ SG_ 977 BT_FH_S_ManTief "FH Schalter manuell tief gedrückt";
CM_ SG_ 977 BT_FH_Thermo "gibt an ob Fensterheber im Thermoschutz ist";
CM_ SG_ 977 BT_gesafet "Im Zustand Safe wird auch das Signal BT_verriegelt = 1 gesendet";
CM_ SG_ 977 BT_Kisi_Fehler "Fehlerstatus Kindersicherungsfunktion";
CM_ SG_ 977 BT_Lock_Taster "Verriegelungstaster";
CM_ SG_ 977 BT_Lock_Taster_inv "Lock Taster nicht betätigt";
CM_ SG_ 977 BT_Oben_Block_erw "Fensterheber in Blockerwartung oben";
CM_ SG_ 977 BT_Schluesselschalter_auf "Schlüsselschalter Richtung auf betätigt";
CM_ SG_ 977 BT_Schluesselschalter_zu "Schluesselschalter Richtung zu betaetigt";
CM_ SG_ 977 BT_Schluesselschalter_zu_inv "Schluesselschalter zu nicht betaetigt";
CM_ SG_ 977 BT_SP_ausgerastet "Spiegel ausgerastet";
CM_ SG_ 977 BT_Sp_Blk_def "Blinker am Spiegel defekt";
CM_ SG_ 977 BT_Sp_Heizung_Anf "Kundenanforderung der Außenspiegelheizung Beifahrertür";
CM_ SG_ 977 BT_SP_Heizung_Status "Status der Spiegelheizung";
CM_ SG_ 977 BT_SP_ht_aktiv "Spiegelverstellung in Richtung hoch/tief aktiv";
CM_ SG_ 977 BT_SP_lr_aktiv "Spiegelverstellung in Richtung links/rechts aktiv";
CM_ SG_ 977 BT_Sperrklinke "Vorraste für Schloß

zwischen Vor- und Hauptraste Signal kurz auf 1, danach wieder auf 0 wenn Tür in Hauptraste (Tür ist sicher zu wenn Sperrklinke und Türkontakt auf 0 sind)";
CM_ SG_ 977 BT_SWA_HMI_defekt "Zeigt an, ob die SWA-Anzeige defekt ist.";
CM_ SG_ 977 BT_TAG_betaetigt "Türaussengriff";
CM_ SG_ 977 BT_TCR_Mode_aktiv "Signal zeigt eine aktive mechanische Redundanz am Türschloss an.";
CM_ SG_ 977 BT_TIG_betaetigt "Türinnengriff";
CM_ SG_ 977 BT_Tuer_geoeffnet "Zeigt eine geöffnete Tür an";
CM_ SG_ 977 BT_Tuer_Status "Türstatus mit Fehler und Initwert";
CM_ SG_ 977 BT_Tuer_Status_QBit "Dieses Bit gibt die Zuverlässigkeit des Türkontakts an. Ein auf dieses Bit folgender Fehlereintrag ist mit dem Sender des Bits abzustimmen (gültig ab PPE).";
CM_ SG_ 977 BT_Tueroeffnen_Warnung "Bit wird gesetzt, wenn Tür während der Fahrt geoeffnet werden soll.";
CM_ SG_ 977 BT_Tuerschloss_defekt "Das Beifahrertürschloss ist nicht mehr funktionsfähig.";
CM_ SG_ 977 BT_UEKB_aktiviert "Überschutzbegrenzungskraft bei Reversieren";
CM_ SG_ 977 BT_Unlock_Taster "Entriegelungstaster betätigt";
CM_ SG_ 977 BT_Unten_Block_erw "Fensterheber in Blockerwartung unten";
CM_ SG_ 977 BT_verriegelt "Zeigt eine verriegelte Tür an ( Status wird erst nach vollständiger Schlossansteuerung ausgegeben (<=1,5sek))";
CM_ SG_ 977 BT_Zuziehhilfe_aktiv "Zuziehhilfe aktiv";

CM_ SG_ 1451 TSG_FlHz_BFS_FnAbbruchHzKreis_A "Flächenheizung: Status";
CM_ SG_ 1451 TSG_FlHz_BFS_FnAbbruchHzKreis_B "Flächenheizung: Status";
CM_ SG_ 1451 TSG_FlHz_BFS_NTC_A "Flächenheizung: Temperatur und Fehlerwert des Heizaktors";
CM_ SG_ 1451 TSG_FlHz_BFS_NTC_B "Flächenheizung: Temperatur und Fehlerwert des Heizaktors";
BA_DEF_REL_ BU_SG_REL_  "GenSigTimeoutTime" INT 0 65535;
BA_DEF_ BO_  "DiagRequest" ENUM "No", "Yes";
BA_DEF_ BO_  "DiagResponse" ENUM "No", "Yes";
BA_DEF_ BO_  "DiagState" ENUM "No", "Yes";
BA_DEF_ BO_  "GenMsgChkConstant" HEX 0 4095;
BA_DEF_ BO_  "GenMsgCycleTime" INT 0 65535;
BA_DEF_ BO_  "GenMsgCycleTimeFast" INT 0 65535;
BA_DEF_ BO_  "GenMsgDelayTime" INT 0 100000;
BA_DEF_ BO_  "GenMsgILSupport" ENUM "No", "Yes";
BA_DEF_ BO_  "GenMsgNrOfRepetition" INT 0 100;
BA_DEF_ BO_  "GenMsgPDUConstants" STRING;
BA_DEF_ BO_  "GenMsgSendType" ENUM "Cyclic", "not_used", "not_used", "not_used", "not_used", "not_used", "not_used", "IfActive", "NoMsgSendType";
BA_DEF_ BO_  "GenMsgStartDelayTime" INT 0 100000;
BA_DEF_ BO_  "NmMessage" ENUM "No", "Yes";
BA_DEF_ BO_  "NmhMessage" ENUM "No", "Yes";
BA_DEF_ BO_  "MsgType" ENUM "Application", "NM ", "NMH", "TP2.0", "ISO-TP ", "BAP", "EID", "KS", "XCP_PRE_CONFIGURED", "XCP_RUNTIME_CONFIGURED";
BA_DEF_ BO_  "VAGTP20_API" HEX 0 255;
BA_DEF_ BO_  "VAGTP20_DynConnection" ENUM "No", "Yes";
BA_DEF_ BO_  "VAGTP20_DynSetup" ENUM "No", "Yes";
BA_DEF_ BO_  "VAGTP20_StatConnection" ENUM "No", "Yes";
BA_DEF_ SG_  "GenSigActiveRepetitions" INT -2147483648 2147483647;
BA_DEF_ SG_  "GenSigInactiveValue" INT -2147483648 2147483647;
BA_DEF_ SG_  "GenSigSendType" ENUM "Cyclic", "OnWrite", "OnWriteWithRepetition", "OnChange", "OnChangeWithRepetition", "IfActive", "IfActiveWithRepetition", "NoSigSendType", "OnChangeAndIfActive", "OnChangeAndIfActiveWithRepetition";
BA_DEF_ SG_  "GenSigStartValue" INT -2147483648 2147483647;
BA_DEF_ SG_  "NWM-WakeupAllowed" ENUM "No", "Yes";
BA_DEF_ SG_  "GenSigFuncType" ENUM "NoFunction", "MsgCounter", "CRC-8", "XOR", "XOR-2", "DatedBit", "SW-Kl15", "CHK", "Constant", "Protocol", "CRC-8-SAE_J1850", "CRC-32", "DataLength", "DataID", "MsgCounter16", "SOK-Signatur", "Cluster";
BA_DEF_ SG_  "GenSigSwitchedByIgnition" ENUM "No", "Yes";
BA_DEF_ SG_  "Fehlerwert" HEX 0 2147483647;
BA_DEF_ SG_  "GenSigMissingSourceValue" HEX 0 2147483647;
BA_DEF_DEF_REL_  "GenSigTimeoutTime" 0;
BA_DEF_DEF_  "DiagRequest" "No";
BA_DEF_DEF_  "DiagResponse" "No";
BA_DEF_DEF_  "DiagState" "No";
BA_DEF_DEF_  "GenMsgChkConstant" 0;
BA_DEF_DEF_  "GenMsgCycleTime" 0;
BA_DEF_DEF_  "GenMsgCycleTimeFast" 0;
BA_DEF_DEF_  "GenMsgDelayTime" 0;
BA_DEF_DEF_  "GenMsgILSupport" "No";
BA_DEF_DEF_  "GenMsgNrOfRepetition" 0;
BA_DEF_DEF_  "GenMsgPDUConstants" "";
BA_DEF_DEF_  "GenMsgSendType" "NoMsgSendType";
BA_DEF_DEF_  "GenMsgStartDelayTime" 0;
BA_DEF_DEF_  "NmMessage" "No";
BA_DEF_DEF_  "NmhMessage" "No";
BA_DEF_DEF_  "MsgType" "Application";
BA_DEF_DEF_  "VAGTP20_API" 0;
BA_DEF_DEF_  "VAGTP20_DynConnection" "No";
BA_DEF_DEF_  "VAGTP20_DynSetup" "No";
BA_DEF_DEF_  "VAGTP20_StatConnection" "No";
BA_DEF_DEF_  "GenSigActiveRepetitions" 0;
BA_DEF_DEF_  "GenSigInactiveValue" 0;
BA_DEF_DEF_  "GenSigSendType" "NoSigSendType";
BA_DEF_DEF_  "GenSigStartValue" 0;
BA_DEF_DEF_  "NWM-WakeupAllowed" "No";
BA_DEF_DEF_  "GenSigFuncType" "NoFunction";
BA_DEF_DEF_  "GenSigSwitchedByIgnition" "Yes";
BA_DEF_DEF_  "Fehlerwert" 0;
BA_DEF_DEF_  "GenSigMissingSourceValue" 0;
BA_ "GenMsgCycleTime" BO_ 1440 200;
BA_ "GenMsgILSupport" BO_ 1440 1;
BA_ "GenMsgSendType" BO_ 1440 0;
BA_ "GenMsgCycleTime" BO_ 1517 500;
BA_ "GenMsgDelayTime" BO_ 1517 100;
BA_ "GenMsgILSupport" BO_ 1517 1;
BA_ "GenMsgSendType" BO_ 1517 0;
BA_ "GenMsgCycleTime" BO_ 1504 500;
BA_ "GenMsgCycleTimeFast" BO_ 1504 100;
BA_ "GenMsgDelayTime" BO_ 1504 50;
BA_ "GenMsgILSupport" BO_ 1504 1;
BA_ "GenMsgNrOfRepetition" BO_ 1504 5;
BA_ "GenMsgSendType" BO_ 1504 0;
BA_ "GenMsgCycleTime" BO_ 249 500;
BA_ "GenMsgILSupport" BO_ 249 1;
BA_ "GenMsgSendType" BO_ 249 0;
BA_ "GenMsgCycleTime" BO_ 424 20;
BA_ "GenMsgILSupport" BO_ 424 1;
BA_ "GenMsgPDUConstants" BO_ 424 "0x11,0x17,0xbb,0xaa,0xd0,0x83,0xe1,0x8e,0xa3,0x4d,0xef,0x50,0x88,0xa5,0x22,0xf6";
BA_ "GenMsgSendType" BO_ 424 0;
BA_ "GenMsgCycleTime" BO_ 1522 200;
BA_ "GenMsgDelayTime" BO_ 1522 50;
BA_ "GenMsgILSupport" BO_ 1522 1;
BA_ "GenMsgSendType" BO_ 1522 0;
BA_ "GenMsgCycleTime" BO_ 2527679651 200;
BA_ "GenMsgILSupport" BO_ 2527679651 1;
BA_ "GenMsgSendType" BO_ 2527679651 0;
BA_ "GenMsgCycleTime" BO_ 980 200;
BA_ "GenMsgCycleTimeFast" BO_ 980 80;
BA_ "GenMsgDelayTime" BO_ 980 40;
BA_ "GenMsgILSupport" BO_ 980 1;
BA_ "GenMsgNrOfRepetition" BO_ 980 5;
BA_ "GenMsgPDUConstants" BO_ 980 "0xc3,0x79,0xbf,0xdb,0xe9,0x11,0x46,0x86,0x69,0xb6,0x9b,0x29,0x15,0x9c,0x45,0x0d";
BA_ "GenMsgSendType" BO_ 980 0;
BA_ "GenMsgCycleTime" BO_ 1467 500;
BA_ "GenMsgILSupport" BO_ 1467 1;
BA_ "GenMsgSendType" BO_ 1467 0;
BA_ "GenMsgCycleTime" BO_ 1710 1000;
BA_ "GenMsgCycleTimeFast" BO_ 1710 100;
BA_ "GenMsgDelayTime" BO_ 1710 50;
BA_ "GenMsgILSupport" BO_ 1710 1;
BA_ "GenMsgNrOfRepetition" BO_ 1710 5;
BA_ "GenMsgSendType" BO_ 1710 0;
BA_ "GenMsgCycleTime" BO_ 1313 200;
BA_ "GenMsgILSupport" BO_ 1313 1;
BA_ "GenMsgSendType" BO_ 1313 0;
BA_ "GenMsgCycleTime" BO_ 1650 500;
BA_ "GenMsgDelayTime" BO_ 1650 50;
BA_ "GenMsgILSupport" BO_ 1650 1;
BA_ "GenMsgSendType" BO_ 1650 0;
BA_ "GenMsgCycleTime" BO_ 505 500;
BA_ "GenMsgILSupport" BO_ 505 1;
BA_ "GenMsgPDUConstants" BO_ 505 "0x14,0xf8,0xf6,0x94,0x2a,0x12,0x39,0x3d,0x98,0x3f,0xfb,0x9d,0x36,0xca,0x1d,0xe0";
BA_ "GenMsgSendType" BO_ 505 0;
BA_ "GenMsgChkConstant" BO_ 1172 144;
BA_ "GenMsgCycleTime" BO_ 1172 200;
BA_ "GenMsgDelayTime" BO_ 1172 20;
BA_ "GenMsgILSupport" BO_ 1172 1;
BA_ "GenMsgPDUConstants" BO_ 1172 "0x90,0x90,0x90,0x90,0x90,0x90,0x90,0x90,0x90,0x90,0x90,0x90,0x90,0x90,0x90,0x90";
BA_ "GenMsgSendType" BO_ 1172 0;
BA_ "GenMsgChkConstant" BO_ 783 12;
BA_ "GenMsgCycleTime" BO_ 783 200;
BA_ "GenMsgDelayTime" BO_ 783 50;
BA_ "GenMsgILSupport" BO_ 783 1;
BA_ "GenMsgPDUConstants" BO_ 783 "0x0c,0x0c,0x0c,0x0c,0x0c,0x0c,0x0c,0x0c,0x0c,0x0c,0x0c,0x0c,0x0c,0x0c,0x0c,0x0c";
BA_ "GenMsgSendType" BO_ 783 0;
BA_ "GenMsgCycleTime" BO_ 673 200;
BA_ "GenMsgDelayTime" BO_ 673 40;
BA_ "GenMsgILSupport" BO_ 673 1;
BA_ "GenMsgSendType" BO_ 673 0;
BA_ "GenMsgCycleTime" BO_ 1413 1000;
BA_ "GenMsgILSupport" BO_ 1413 1;
BA_ "GenMsgSendType" BO_ 1413 0;
BA_ "GenMsgStartDelayTime" BO_ 1413 85;
BA_ "GenMsgCycleTime" BO_ 1015 100;
BA_ "GenMsgILSupport" BO_ 1015 1;
BA_ "GenMsgSendType" BO_ 1015 0;
BA_ "GenMsgCycleTime" BO_ 1017 200;
BA_ "GenMsgILSupport" BO_ 1017 1;
BA_ "GenMsgSendType" BO_ 1017 0;
BA_ "GenMsgCycleTime" BO_ 1375 500;
BA_ "GenMsgDelayTime" BO_ 1375 20;
BA_ "GenMsgILSupport" BO_ 1375 1;
BA_ "GenMsgSendType" BO_ 1375 0;
BA_ "GenMsgCycleTime" BO_ 1373 500;
BA_ "GenMsgDelayTime" BO_ 1373 200;
BA_ "GenMsgILSupport" BO_ 1373 1;
BA_ "GenMsgSendType" BO_ 1373 0;
BA_ "GenMsgCycleTime" BO_ 1657 500;
BA_ "GenMsgILSupport" BO_ 1657 1;
BA_ "GenMsgSendType" BO_ 1657 0;
BA_ "GenMsgCycleTime" BO_ 977 100;
BA_ "GenMsgDelayTime" BO_ 977 20;
BA_ "GenMsgILSupport" BO_ 977 1;
BA_ "GenMsgSendType" BO_ 977 0;
BA_ "GenMsgCycleTime" BO_ 1451 1000;
BA_ "GenMsgDelayTime" BO_ 1451 100;
BA_ "GenMsgILSupport" BO_ 1451 1;
BA_ "GenMsgSendType" BO_ 1451 0;
BA_ "GenSigSendType" SG_ 1440 LS_defekt 0;
BA_ "GenSigSwitchedByIgnition" SG_ 1440 LS_defekt 0;
BA_ "GenSigSendType" SG_ 1440 LS_Helligkeit_FW 0;
BA_ "GenSigStartValue" SG_ 1440 LS_Helligkeit_FW 1022;
BA_ "GenSigSwitchedByIgnition" SG_ 1440 LS_Helligkeit_FW 0;
BA_ "Fehlerwert" SG_ 1440 LS_Helligkeit_FW 1023;
BA_ "GenSigMissingSourceValue" SG_ 1440 LS_Helligkeit_FW 1023;
BA_ "GenSigSendType" SG_ 1440 LS_Helligkeit_IR 0;
BA_ "GenSigStartValue" SG_ 1440 LS_Helligkeit_IR 254;
BA_ "GenSigSwitchedByIgnition" SG_ 1440 LS_Helligkeit_IR 0;
BA_ "Fehlerwert" SG_ 1440 LS_Helligkeit_IR 255;
BA_ "GenSigMissingSourceValue" SG_ 1440 LS_Helligkeit_IR 255;
BA_ "GenSigSendType" SG_ 1440 LS_Verbau 0;
BA_ "GenSigSwitchedByIgnition" SG_ 1440 LS_Verbau 0;
BA_ "GenSigSendType" SG_ 1440 RLS_Vorfeldhelligkeit_Boost 0;
BA_ "GenSigStartValue" SG_ 1440 RLS_Vorfeldhelligkeit_Boost 15;
BA_ "GenSigSwitchedByIgnition" SG_ 1440 RLS_Vorfeldhelligkeit_Boost 0;
BA_ "GenSigSendType" SG_ 1440 RS_defekt 0;
BA_ "GenSigSwitchedByIgnition" SG_ 1440 RS_defekt 0;
BA_ "GenSigSendType" SG_ 1440 RS_Regenmenge 0;
BA_ "GenSigStartValue" SG_ 1440 RS_Regenmenge 14;
BA_ "GenSigSwitchedByIgnition" SG_ 1440 RS_Regenmenge 0;
BA_ "Fehlerwert" SG_ 1440 RS_Regenmenge 15;
BA_ "GenSigMissingSourceValue" SG_ 1440 RS_Regenmenge 15;
BA_ "GenSigSendType" SG_ 1440 RS_Verbau 0;
BA_ "GenSigSwitchedByIgnition" SG_ 1440 RS_Verbau 0;
BA_ "GenSigSendType" SG_ 1440 RS_Verglasung_schliessen 0;
BA_ "GenSigSwitchedByIgnition" SG_ 1440 RS_Verglasung_schliessen 0;
BA_ "GenSigSendType" SG_ 1440 RS_Wischergeschwindigkeit 0;
BA_ "GenSigSwitchedByIgnition" SG_ 1440 RS_Wischergeschwindigkeit 0;
BA_ "GenSigSendType" SG_ 1517 SAD2_Deckel_Lage 0;
BA_ "GenSigSwitchedByIgnition" SG_ 1517 SAD2_Deckel_Lage 0;
BA_ "GenSigSendType" SG_ 1517 SAD2_Deckel_normiert 3;
BA_ "GenSigSwitchedByIgnition" SG_ 1517 SAD2_Deckel_normiert 0;
BA_ "GenSigSendType" SG_ 1517 SAD2_Deckel_Position 3;
BA_ "GenSigStartValue" SG_ 1517 SAD2_Deckel_Position 126;
BA_ "GenSigSwitchedByIgnition" SG_ 1517 SAD2_Deckel_Position 0;
BA_ "GenSigSendType" SG_ 1517 SAD2_Deckel_Thermoschutz 3;
BA_ "GenSigSwitchedByIgnition" SG_ 1517 SAD2_Deckel_Thermoschutz 0;
BA_ "GenSigSendType" SG_ 1517 SAD2_Deckel_UEKB_aktiv 3;
BA_ "GenSigSwitchedByIgnition" SG_ 1517 SAD2_Deckel_UEKB_aktiv 0;
BA_ "GenSigSendType" SG_ 1517 SAD2_Rollo_Lage 0;
BA_ "GenSigSwitchedByIgnition" SG_ 1517 SAD2_Rollo_Lage 0;
BA_ "GenSigSendType" SG_ 1517 SAD2_Rollo_normiert 3;
BA_ "GenSigSwitchedByIgnition" SG_ 1517 SAD2_Rollo_normiert 0;
BA_ "GenSigSendType" SG_ 1517 SAD2_Rollo_Position 0;
BA_ "GenSigStartValue" SG_ 1517 SAD2_Rollo_Position 126;
BA_ "GenSigSwitchedByIgnition" SG_ 1517 SAD2_Rollo_Position 0;
BA_ "GenSigSendType" SG_ 1517 SAD2_Rollo_Thermoschutz 3;
BA_ "GenSigSwitchedByIgnition" SG_ 1517 SAD2_Rollo_Thermoschutz 0;
BA_ "GenSigSendType" SG_ 1517 SAD2_Rollo_UEKB_aktiv 3;
BA_ "GenSigSwitchedByIgnition" SG_ 1517 SAD2_Rollo_UEKB_aktiv 0;
BA_ "GenSigSendType" SG_ 1504 MD1_Lage 0;
BA_ "GenSigSwitchedByIgnition" SG_ 1504 MD1_Lage 0;
BA_ "GenSigSendType" SG_ 1504 MD1_Position 3;
BA_ "GenSigStartValue" SG_ 1504 MD1_Position 126;
BA_ "GenSigSwitchedByIgnition" SG_ 1504 MD1_Position 0;
BA_ "GenSigSendType" SG_ 1504 MD3_Lage 0;
BA_ "GenSigSwitchedByIgnition" SG_ 1504 MD3_Lage 0;
BA_ "GenSigSendType" SG_ 1504 MD3_Position 0;
BA_ "GenSigSwitchedByIgnition" SG_ 1504 MD3_Position 0;
BA_ "GenSigSendType" SG_ 1504 MRollo_Lage 0;
BA_ "GenSigSwitchedByIgnition" SG_ 1504 MRollo_Lage 0;
BA_ "GenSigSendType" SG_ 1504 MRollo_Position 0;
BA_ "GenSigStartValue" SG_ 1504 MRollo_Position 126;
BA_ "GenSigSwitchedByIgnition" SG_ 1504 MRollo_Position 0;
BA_ "GenSigSendType" SG_ 1504 Rollo_normiert 3;
BA_ "GenSigSwitchedByIgnition" SG_ 1504 Rollo_normiert 0;
BA_ "GenSigSendType" SG_ 1504 Rollo_Thermoschutz 3;
BA_ "GenSigSwitchedByIgnition" SG_ 1504 Rollo_Thermoschutz 0;
BA_ "GenSigSendType" SG_ 1504 Rollo_UEKB_aktiv 3;
BA_ "GenSigSwitchedByIgnition" SG_ 1504 Rollo_UEKB_aktiv 0;
BA_ "GenSigSendType" SG_ 1504 SAD_Anf_ESC_Zuschaltung 3;
BA_ "GenSigSwitchedByIgnition" SG_ 1504 SAD_Anf_ESC_Zuschaltung 0;
BA_ "GenSigSendType" SG_ 1504 SAD_normiert 3;
BA_ "GenSigSwitchedByIgnition" SG_ 1504 SAD_normiert 0;
BA_ "GenSigSendType" SG_ 1504 SAD_ParityBit 0;
BA_ "GenSigSwitchedByIgnition" SG_ 1504 SAD_ParityBit 0;
BA_ "GenSigActiveRepetitions" SG_ 1504 SAD_Taster_Deckel_hi 5;
BA_ "GenSigSendType" SG_ 1504 SAD_Taster_Deckel_hi 4;
BA_ "GenSigSwitchedByIgnition" SG_ 1504 SAD_Taster_Deckel_hi 0;
BA_ "GenSigActiveRepetitions" SG_ 1504 SAD_Taster_Deckel_vo 5;
BA_ "GenSigSendType" SG_ 1504 SAD_Taster_Deckel_vo 4;
BA_ "GenSigSwitchedByIgnition" SG_ 1504 SAD_Taster_Deckel_vo 0;
BA_ "GenSigActiveRepetitions" SG_ 1504 SAD_Taster_Rollo_hi 5;
BA_ "GenSigSendType" SG_ 1504 SAD_Taster_Rollo_hi 4;
BA_ "GenSigSwitchedByIgnition" SG_ 1504 SAD_Taster_Rollo_hi 0;
BA_ "GenSigActiveRepetitions" SG_ 1504 SAD_Taster_Rollo_vo 5;
BA_ "GenSigSendType" SG_ 1504 SAD_Taster_Rollo_vo 4;
BA_ "GenSigSwitchedByIgnition" SG_ 1504 SAD_Taster_Rollo_vo 0;
BA_ "GenSigActiveRepetitions" SG_ 1504 SAD_Text 5;
BA_ "GenSigSendType" SG_ 1504 SAD_Text 4;
BA_ "GenSigSwitchedByIgnition" SG_ 1504 SAD_Text 0;
BA_ "GenSigSendType" SG_ 1504 SAD_Thermoschutz 3;
BA_ "GenSigSwitchedByIgnition" SG_ 1504 SAD_Thermoschutz 0;
BA_ "GenSigSendType" SG_ 1504 SAD_ToggleBit 0;
BA_ "GenSigSwitchedByIgnition" SG_ 1504 SAD_ToggleBit 0;
BA_ "GenSigSendType" SG_ 1504 SAD_UEKB_aktiv 3;
BA_ "GenSigSwitchedByIgnition" SG_ 1504 SAD_UEKB_aktiv 0;
BA_ "GenSigSendType" SG_ 249 SARA_Nickwinkel 0;
BA_ "GenSigStartValue" SG_ 249 SARA_Nickwinkel 8191;
BA_ "GenSigSwitchedByIgnition" SG_ 249 SARA_Nickwinkel 0;
BA_ "GenSigSendType" SG_ 249 SARA_QBit_Nickwinkel 0;
BA_ "GenSigStartValue" SG_ 249 SARA_QBit_Nickwinkel 1;
BA_ "GenSigSwitchedByIgnition" SG_ 249 SARA_QBit_Nickwinkel 0;
BA_ "GenSigSendType" SG_ 249 SARA_QBit_Wankwinkel 0;
BA_ "GenSigStartValue" SG_ 249 SARA_QBit_Wankwinkel 1;
BA_ "GenSigSwitchedByIgnition" SG_ 249 SARA_QBit_Wankwinkel 0;
BA_ "GenSigSendType" SG_ 249 SARA_Wankwinkel 0;
BA_ "GenSigStartValue" SG_ 249 SARA_Wankwinkel 8191;
BA_ "GenSigSwitchedByIgnition" SG_ 249 SARA_Wankwinkel 0;
BA_ "GenSigSendType" SG_ 424 SARA_11_BZ 0;
BA_ "GenSigFuncType" SG_ 424 SARA_11_BZ 1;
BA_ "GenSigSwitchedByIgnition" SG_ 424 SARA_11_BZ 0;
BA_ "GenSigSendType" SG_ 424 SARA_11_CRC 0;
BA_ "GenSigFuncType" SG_ 424 SARA_11_CRC 2;
BA_ "GenSigSwitchedByIgnition" SG_ 424 SARA_11_CRC 0;
BA_ "GenSigSendType" SG_ 424 SARA_Accel_X_r 0;
BA_ "GenSigStartValue" SG_ 424 SARA_Accel_X_r 4096;
BA_ "GenSigSwitchedByIgnition" SG_ 424 SARA_Accel_X_r 0;
BA_ "Fehlerwert" SG_ 424 SARA_Accel_X_r 8191;
BA_ "GenSigSendType" SG_ 424 SARA_Accel_Y_r 0;
BA_ "GenSigStartValue" SG_ 424 SARA_Accel_Y_r 4096;
BA_ "GenSigSwitchedByIgnition" SG_ 424 SARA_Accel_Y_r 0;
BA_ "Fehlerwert" SG_ 424 SARA_Accel_Y_r 8191;
BA_ "GenSigSendType" SG_ 424 SARA_CF_Accel_X_r 0;
BA_ "GenSigStartValue" SG_ 424 SARA_CF_Accel_X_r 4;
BA_ "GenSigSwitchedByIgnition" SG_ 424 SARA_CF_Accel_X_r 0;
BA_ "GenSigSendType" SG_ 424 SARA_CF_Accel_Y_r 0;
BA_ "GenSigStartValue" SG_ 424 SARA_CF_Accel_Y_r 4;
BA_ "GenSigSwitchedByIgnition" SG_ 424 SARA_CF_Accel_Y_r 0;
BA_ "GenSigSendType" SG_ 424 SARA_CF_Omega_Z_r 0;
BA_ "GenSigStartValue" SG_ 424 SARA_CF_Omega_Z_r 4;
BA_ "GenSigSwitchedByIgnition" SG_ 424 SARA_CF_Omega_Z_r 0;
BA_ "GenSigSendType" SG_ 424 SARA_Omega_Z_r 0;
BA_ "GenSigStartValue" SG_ 424 SARA_Omega_Z_r 4096;
BA_ "GenSigSwitchedByIgnition" SG_ 424 SARA_Omega_Z_r 0;
BA_ "Fehlerwert" SG_ 424 SARA_Omega_Z_r 8191;
BA_ "GenSigSendType" SG_ 1522 KBI_Dimmpoti 0;
BA_ "GenSigSwitchedByIgnition" SG_ 1522 KBI_Dimmpoti 0;
BA_ "Fehlerwert" SG_ 1522 KBI_Dimmpoti 127;
BA_ "GenSigSendType" SG_ 1522 KBI_Phototransistor 3;
BA_ "GenSigStartValue" SG_ 1522 KBI_Phototransistor 254;
BA_ "GenSigSwitchedByIgnition" SG_ 1522 KBI_Phototransistor 0;
BA_ "Fehlerwert" SG_ 1522 KBI_Phototransistor 255;
BA_ "GenSigSendType" SG_ 2527679651 SM_Parken_blinken 0;
BA_ "GenSigSwitchedByIgnition" SG_ 2527679651 SM_Parken_blinken 0;
BA_ "GenSigSendType" SG_ 2527679651 SM_Parken_Hupe_Anf 0;
BA_ "GenSigSwitchedByIgnition" SG_ 2527679651 SM_Parken_Hupe_Anf 0;
BA_ "GenSigSendType" SG_ 2527679651 SM_Parken_Komfortschliessen_Anf 0;
BA_ "GenSigSwitchedByIgnition" SG_ 2527679651 SM_Parken_Komfortschliessen_Anf 0;
BA_ "GenSigSendType" SG_ 2527679651 SM_Parken_UGDO_Aktion 0;
BA_ "GenSigSwitchedByIgnition" SG_ 2527679651 SM_Parken_UGDO_Aktion 0;
BA_ "GenSigSendType" SG_ 2527679651 SM_Parken_UGDO_Anf 0;
BA_ "GenSigSwitchedByIgnition" SG_ 2527679651 SM_Parken_UGDO_Anf 0;
BA_ "GenSigSendType" SG_ 980 BH_Blinker_Fehler 3;
BA_ "GenSigSwitchedByIgnition" SG_ 980 BH_Blinker_Fehler 0;
BA_ "Fehlerwert" SG_ 980 BH_Blinker_Fehler 1;
BA_ "GenSigActiveRepetitions" SG_ 980 BH_Blinker_li 5;
BA_ "GenSigSendType" SG_ 980 BH_Blinker_li 4;
BA_ "GenSigSwitchedByIgnition" SG_ 980 BH_Blinker_li 0;
BA_ "GenSigActiveRepetitions" SG_ 980 BH_Blinker_re 5;
BA_ "GenSigSendType" SG_ 980 BH_Blinker_re 4;
BA_ "GenSigSwitchedByIgnition" SG_ 980 BH_Blinker_re 0;
BA_ "GenSigSendType" SG_ 980 BH_Fernlicht 3;
BA_ "GenSigSwitchedByIgnition" SG_ 980 BH_Fernlicht 0;
BA_ "GenSigActiveRepetitions" SG_ 980 BH_Lichthupe 5;
BA_ "GenSigSendType" SG_ 980 BH_Lichthupe 4;
BA_ "GenSigSwitchedByIgnition" SG_ 980 BH_Lichthupe 0;
BA_ "GenSigSendType" SG_ 980 FAS_Taster 3;
BA_ "GenSigSwitchedByIgnition" SG_ 980 FAS_Taster 0;
BA_ "GenSigSendType" SG_ 980 FAS_Taster_Fehler 3;
BA_ "GenSigSwitchedByIgnition" SG_ 980 FAS_Taster_Fehler 0;
BA_ "Fehlerwert" SG_ 980 FAS_Taster_Fehler 1;
BA_ "GenSigSendType" SG_ 980 LRH_aktiv 3;
BA_ "GenSigSwitchedByIgnition" SG_ 980 LRH_aktiv 0;
BA_ "GenSigSendType" SG_ 980 LRH_On_Off 3;
BA_ "GenSigSwitchedByIgnition" SG_ 980 LRH_On_Off 0;
BA_ "Fehlerwert" SG_ 980 LRH_On_Off 3;
BA_ "GenSigSendType" SG_ 980 SMLS_01_BZ 0;
BA_ "GenSigFuncType" SG_ 980 SMLS_01_BZ 1;
BA_ "GenSigSwitchedByIgnition" SG_ 980 SMLS_01_BZ 0;
BA_ "GenSigSendType" SG_ 980 SMLS_01_CRC 0;
BA_ "GenSigFuncType" SG_ 980 SMLS_01_CRC 2;
BA_ "GenSigSwitchedByIgnition" SG_ 980 SMLS_01_CRC 0;
BA_ "GenSigActiveRepetitions" SG_ 980 SMLS_Hupe 5;
BA_ "GenSigSendType" SG_ 980 SMLS_Hupe 4;
BA_ "GenSigSwitchedByIgnition" SG_ 980 SMLS_Hupe 0;
BA_ "GenSigSendType" SG_ 980 SMLS_P_verriegelt_plausibel 3;
BA_ "GenSigSwitchedByIgnition" SG_ 980 SMLS_P_verriegelt_plausibel 0;
BA_ "GenSigActiveRepetitions" SG_ 980 SMLS_PTT 5;
BA_ "GenSigSendType" SG_ 980 SMLS_PTT 4;
BA_ "GenSigSendType" SG_ 980 WH_Frontwaschen 3;
BA_ "GenSigSwitchedByIgnition" SG_ 980 WH_Frontwaschen 0;
BA_ "GenSigSendType" SG_ 980 WH_Heckintervall 3;
BA_ "GenSigSwitchedByIgnition" SG_ 980 WH_Heckintervall 0;
BA_ "GenSigSendType" SG_ 980 WH_Heckwaschen 3;
BA_ "GenSigSwitchedByIgnition" SG_ 980 WH_Heckwaschen 0;
BA_ "GenSigSendType" SG_ 980 WH_Intervall 3;
BA_ "GenSigSwitchedByIgnition" SG_ 980 WH_Intervall 0;
BA_ "GenSigSendType" SG_ 980 WH_Intervallstufen 3;
BA_ "GenSigSwitchedByIgnition" SG_ 980 WH_Intervallstufen 0;
BA_ "Fehlerwert" SG_ 980 WH_Intervallstufen 15;
BA_ "GenSigMissingSourceValue" SG_ 980 WH_Intervallstufen 15;
BA_ "GenSigActiveRepetitions" SG_ 980 WH_SRA 5;
BA_ "GenSigSendType" SG_ 980 WH_SRA 4;
BA_ "GenSigSwitchedByIgnition" SG_ 980 WH_SRA 0;
BA_ "GenSigActiveRepetitions" SG_ 980 WH_Tipwischen 5;
BA_ "GenSigSendType" SG_ 980 WH_Tipwischen 4;
BA_ "GenSigSwitchedByIgnition" SG_ 980 WH_Tipwischen 0;
BA_ "GenSigActiveRepetitions" SG_ 980 WH_Tipwischen_lang 5;
BA_ "GenSigSendType" SG_ 980 WH_Tipwischen_lang 4;
BA_ "GenSigSwitchedByIgnition" SG_ 980 WH_Tipwischen_lang 0;
BA_ "GenSigSendType" SG_ 980 WH_Wischer_Fehler 3;
BA_ "GenSigSwitchedByIgnition" SG_ 980 WH_Wischer_Fehler 0;
BA_ "Fehlerwert" SG_ 980 WH_Wischer_Fehler 1;
BA_ "GenSigSendType" SG_ 980 WH_WischerStufe1 3;
BA_ "GenSigSwitchedByIgnition" SG_ 980 WH_WischerStufe1 0;
BA_ "GenSigSendType" SG_ 980 WH_WischerStufe2 3;
BA_ "GenSigSwitchedByIgnition" SG_ 980 WH_WischerStufe2 0;
BA_ "GenSigSendType" SG_ 1467 SoSe_SunInt_2D_Li 0;
BA_ "GenSigStartValue" SG_ 1467 SoSe_SunInt_2D_Li 254;
BA_ "GenSigSwitchedByIgnition" SG_ 1467 SoSe_SunInt_2D_Li 0;
BA_ "Fehlerwert" SG_ 1467 SoSe_SunInt_2D_Li 255;
BA_ "GenSigSendType" SG_ 1467 SoSe_SunInt_2D_Re 0;
BA_ "GenSigStartValue" SG_ 1467 SoSe_SunInt_2D_Re 254;
BA_ "GenSigSwitchedByIgnition" SG_ 1467 SoSe_SunInt_2D_Re 0;
BA_ "Fehlerwert" SG_ 1467 SoSe_SunInt_2D_Re 255;
BA_ "GenSigActiveRepetitions" SG_ 1710 SP_abklappen 5;
BA_ "GenSigSendType" SG_ 1710 SP_abklappen 4;
BA_ "GenSigSwitchedByIgnition" SG_ 1710 SP_abklappen 0;
BA_ "GenSigActiveRepetitions" SG_ 1710 SP_anklappen 5;
BA_ "GenSigSendType" SG_ 1710 SP_anklappen 4;
BA_ "GenSigSwitchedByIgnition" SG_ 1710 SP_anklappen 0;
BA_ "GenSigSendType" SG_ 1710 SP_ARA_Status 0;
BA_ "GenSigActiveRepetitions" SG_ 1710 SP_Auswahl_li 5;
BA_ "GenSigSendType" SG_ 1710 SP_Auswahl_li 4;
BA_ "GenSigSwitchedByIgnition" SG_ 1710 SP_Auswahl_li 0;
BA_ "GenSigActiveRepetitions" SG_ 1710 SP_Auswahl_re 5;
BA_ "GenSigSendType" SG_ 1710 SP_Auswahl_re 4;
BA_ "GenSigSwitchedByIgnition" SG_ 1710 SP_Auswahl_re 0;
BA_ "GenSigActiveRepetitions" SG_ 1710 SP_BT_links 5;
BA_ "GenSigSendType" SG_ 1710 SP_BT_links 4;
BA_ "GenSigSwitchedByIgnition" SG_ 1710 SP_BT_links 0;
BA_ "GenSigActiveRepetitions" SG_ 1710 SP_BT_oben 5;
BA_ "GenSigSendType" SG_ 1710 SP_BT_oben 4;
BA_ "GenSigSwitchedByIgnition" SG_ 1710 SP_BT_oben 0;
BA_ "GenSigActiveRepetitions" SG_ 1710 SP_BT_rechts 5;
BA_ "GenSigSendType" SG_ 1710 SP_BT_rechts 4;
BA_ "GenSigSwitchedByIgnition" SG_ 1710 SP_BT_rechts 0;
BA_ "GenSigActiveRepetitions" SG_ 1710 SP_BT_unten 5;
BA_ "GenSigSendType" SG_ 1710 SP_BT_unten 4;
BA_ "GenSigSwitchedByIgnition" SG_ 1710 SP_BT_unten 0;
BA_ "GenSigActiveRepetitions" SG_ 1710 SP_FT_links 5;
BA_ "GenSigSendType" SG_ 1710 SP_FT_links 4;
BA_ "GenSigSwitchedByIgnition" SG_ 1710 SP_FT_links 0;
BA_ "GenSigActiveRepetitions" SG_ 1710 SP_FT_oben 5;
BA_ "GenSigSendType" SG_ 1710 SP_FT_oben 4;
BA_ "GenSigSwitchedByIgnition" SG_ 1710 SP_FT_oben 0;
BA_ "GenSigActiveRepetitions" SG_ 1710 SP_FT_rechts 5;
BA_ "GenSigSendType" SG_ 1710 SP_FT_rechts 4;
BA_ "GenSigSwitchedByIgnition" SG_ 1710 SP_FT_rechts 0;
BA_ "GenSigActiveRepetitions" SG_ 1710 SP_FT_unten 5;
BA_ "GenSigSendType" SG_ 1710 SP_FT_unten 4;
BA_ "GenSigSwitchedByIgnition" SG_ 1710 SP_FT_unten 0;
BA_ "GenSigSendType" SG_ 1710 SP_Hzg_Taster 3;
BA_ "GenSigSwitchedByIgnition" SG_ 1710 SP_Hzg_Taster 0;
BA_ "GenSigActiveRepetitions" SG_ 1710 SP_normieren 5;
BA_ "GenSigSendType" SG_ 1710 SP_normieren 4;
BA_ "GenSigSwitchedByIgnition" SG_ 1710 SP_normieren 0;
BA_ "GenSigActiveRepetitions" SG_ 1710 SP_S_Klappen 5;
BA_ "GenSigSendType" SG_ 1710 SP_S_Klappen 4;
BA_ "GenSigSwitchedByIgnition" SG_ 1710 SP_S_Klappen 0;
BA_ "GenSigActiveRepetitions" SG_ 1710 SP_S_links 5;
BA_ "GenSigSendType" SG_ 1710 SP_S_links 4;
BA_ "GenSigSwitchedByIgnition" SG_ 1710 SP_S_links 0;
BA_ "GenSigActiveRepetitions" SG_ 1710 SP_S_oben 5;
BA_ "GenSigSendType" SG_ 1710 SP_S_oben 4;
BA_ "GenSigSwitchedByIgnition" SG_ 1710 SP_S_oben 0;
BA_ "GenSigActiveRepetitions" SG_ 1710 SP_S_rechts 5;
BA_ "GenSigSendType" SG_ 1710 SP_S_rechts 4;
BA_ "GenSigSwitchedByIgnition" SG_ 1710 SP_S_rechts 0;
BA_ "GenSigActiveRepetitions" SG_ 1710 SP_S_unten 5;
BA_ "GenSigSendType" SG_ 1710 SP_S_unten 4;
BA_ "GenSigSwitchedByIgnition" SG_ 1710 SP_S_unten 0;
BA_ "GenSigSendType" SG_ 1710 SP_Verstellschalter_Fehler 0;
BA_ "Fehlerwert" SG_ 1710 SP_Verstellschalter_Fehler 1;
BA_ "GenSigSendType" SG_ 1313 STH_EKP_Anst 0;
BA_ "GenSigSwitchedByIgnition" SG_ 1313 STH_EKP_Anst 0;
BA_ "GenSigSendType" SG_ 1313 STH_Fehler_ElWaPu 0;
BA_ "GenSigSwitchedByIgnition" SG_ 1313 STH_Fehler_ElWaPu 0;
BA_ "Fehlerwert" SG_ 1313 STH_Fehler_ElWaPu 1;
BA_ "GenSigSendType" SG_ 1313 STH_Fehlerstatus 0;
BA_ "GenSigSwitchedByIgnition" SG_ 1313 STH_Fehlerstatus 0;
BA_ "GenSigSendType" SG_ 1313 STH_Funk_aus 0;
BA_ "GenSigSwitchedByIgnition" SG_ 1313 STH_Funk_aus 0;
BA_ "GenSigSendType" SG_ 1313 STH_Funk_ein 0;
BA_ "GenSigSwitchedByIgnition" SG_ 1313 STH_Funk_ein 0;
BA_ "GenSigSendType" SG_ 1313 STH_Geblaese 0;
BA_ "GenSigSwitchedByIgnition" SG_ 1313 STH_Geblaese 0;
BA_ "GenSigSendType" SG_ 1313 STH_Heizleistung 0;
BA_ "GenSigSwitchedByIgnition" SG_ 1313 STH_Heizleistung 0;
BA_ "GenSigSendType" SG_ 1313 STH_KL_HUP 0;
BA_ "GenSigSwitchedByIgnition" SG_ 1313 STH_KL_HUP 0;
BA_ "GenSigSendType" SG_ 1313 STH_KVS 0;
BA_ "GenSigSwitchedByIgnition" SG_ 1313 STH_KVS 0;
BA_ "GenSigSendType" SG_ 1313 STH_KVS_Ueberlauf 0;
BA_ "GenSigSwitchedByIgnition" SG_ 1313 STH_KVS_Ueberlauf 0;
BA_ "GenSigSendType" SG_ 1313 STH_LED 0;
BA_ "GenSigSwitchedByIgnition" SG_ 1313 STH_LED 0;
BA_ "GenSigSendType" SG_ 1313 STH_Motorvorwaermung 0;
BA_ "GenSigSwitchedByIgnition" SG_ 1313 STH_Motorvorwaermung 0;
BA_ "GenSigSendType" SG_ 1313 STH_Pumpe_ein 0;
BA_ "GenSigSwitchedByIgnition" SG_ 1313 STH_Pumpe_ein 0;
BA_ "GenSigSendType" SG_ 1313 STH_Pumpen_Anf_extern 0;
BA_ "GenSigSwitchedByIgnition" SG_ 1313 STH_Pumpen_Anf_extern 0;
BA_ "GenSigSendType" SG_ 1313 STH_Servicemode 0;
BA_ "GenSigSwitchedByIgnition" SG_ 1313 STH_Servicemode 0;
BA_ "GenSigSendType" SG_ 1313 STH_SH_ZH 0;
BA_ "GenSigSwitchedByIgnition" SG_ 1313 STH_SH_ZH 0;
BA_ "GenSigSendType" SG_ 1313 STH_Start_folgt 0;
BA_ "GenSigSwitchedByIgnition" SG_ 1313 STH_Start_folgt 0;
BA_ "GenSigSendType" SG_ 1313 STH_Texte 0;
BA_ "GenSigSwitchedByIgnition" SG_ 1313 STH_Texte 0;
BA_ "GenSigSendType" SG_ 1313 STH_Ventil_Status 0;
BA_ "GenSigSwitchedByIgnition" SG_ 1313 STH_Ventil_Status 0;
BA_ "GenSigSendType" SG_ 1313 STH_Ventiloeffnungszeit 0;
BA_ "GenSigSwitchedByIgnition" SG_ 1313 STH_Ventiloeffnungszeit 0;
BA_ "GenSigSendType" SG_ 1313 STH_Waermeeintrag 0;
BA_ "GenSigSwitchedByIgnition" SG_ 1313 STH_Waermeeintrag 0;
BA_ "GenSigSendType" SG_ 1313 STH_war_aktiv 0;
BA_ "GenSigSwitchedByIgnition" SG_ 1313 STH_war_aktiv 0;
BA_ "GenSigSendType" SG_ 1313 STH_Wassertemp 0;
BA_ "GenSigStartValue" SG_ 1313 STH_Wassertemp 254;
BA_ "GenSigSwitchedByIgnition" SG_ 1313 STH_Wassertemp 0;
BA_ "Fehlerwert" SG_ 1313 STH_Wassertemp 255;
BA_ "GenSigSendType" SG_ 1313 STH_Zusatzheizung 0;
BA_ "GenSigSwitchedByIgnition" SG_ 1313 STH_Zusatzheizung 0;
BA_ "GenSigSendType" SG_ 1650 STH_ZZ_Betriebsdauer 3;
BA_ "GenSigSwitchedByIgnition" SG_ 1650 STH_ZZ_Betriebsdauer 0;
BA_ "GenSigSendType" SG_ 1650 STH_ZZ_Betriebsmodus 3;
BA_ "GenSigSwitchedByIgnition" SG_ 1650 STH_ZZ_Betriebsmodus 0;
BA_ "GenSigSendType" SG_ 1650 STH_ZZ_Minute 3;
BA_ "GenSigSwitchedByIgnition" SG_ 1650 STH_ZZ_Minute 0;
BA_ "GenSigSendType" SG_ 1650 STH_ZZ_Monat 3;
BA_ "GenSigSwitchedByIgnition" SG_ 1650 STH_ZZ_Monat 0;
BA_ "GenSigSendType" SG_ 1650 STH_ZZ_Status_Timer 3;
BA_ "GenSigSwitchedByIgnition" SG_ 1650 STH_ZZ_Status_Timer 0;
BA_ "GenSigSendType" SG_ 1650 STH_ZZ_Stunde 3;
BA_ "GenSigSwitchedByIgnition" SG_ 1650 STH_ZZ_Stunde 0;
BA_ "GenSigSendType" SG_ 1650 STH_ZZ_Tag 3;
BA_ "GenSigSwitchedByIgnition" SG_ 1650 STH_ZZ_Tag 0;
BA_ "GenSigSendType" SG_ 505 ACA_HF_Grund_AV_AB 0;
BA_ "GenSigSendType" SG_ 505 ACA_HF_Status 0;
BA_ "GenSigStartValue" SG_ 505 ACA_HF_Status 1;
BA_ "GenSigSendType" SG_ 505 ACA_QF_Fahreruebernahme 0;
BA_ "GenSigSendType" SG_ 505 ACA_QF_Status_Anzeige 0;
BA_ "GenSigSendType" SG_ 505 ACF_Spurwechsel_moeglich 0;
BA_ "GenSigSendType" SG_ 505 ACF_Spurwechsel_wahrscheinlich 0;
BA_ "GenSigSendType" SG_ 505 ACF_SwuFahrerUnaufmerksam 0;
BA_ "GenSigSwitchedByIgnition" SG_ 505 ACF_SwuFahrerUnaufmerksam 0;
BA_ "GenSigSendType" SG_ 505 FZE_Spurwechsel_erkannt_li 0;
BA_ "GenSigSendType" SG_ 505 FZE_Spurwechsel_erkannt_re 0;
BA_ "GenSigSendType" SG_ 505 FZE_STP_Abschaltbedingung 0;
BA_ "GenSigStartValue" SG_ 505 FZE_STP_Abschaltbedingung 1;
BA_ "GenSigSendType" SG_ 505 FZE_STP_Aktivierverhinderung 0;
BA_ "GenSigSwitchedByIgnition" SG_ 505 FZE_STP_Aktivierverhinderung 0;
BA_ "GenSigSendType" SG_ 505 FZE_STP_Status 0;
BA_ "GenSigSendType" SG_ 505 STP_03_BZ 0;
BA_ "GenSigFuncType" SG_ 505 STP_03_BZ 1;
BA_ "GenSigSendType" SG_ 505 STP_03_CRC 0;
BA_ "GenSigFuncType" SG_ 505 STP_03_CRC 2;
BA_ "GenSigSendType" SG_ 505 STP_Funktion_freigegeben 0;
BA_ "GenSigSendType" SG_ 505 STP_Notlaufaktivierung 0;
BA_ "GenSigSendType" SG_ 505 STP_Slave_Status 0;
BA_ "GenSigSendType" SG_ 1172 GW_STS2_Privatsphaere 0;
BA_ "GenSigSwitchedByIgnition" SG_ 1172 GW_STS2_Privatsphaere 0;
BA_ "GenSigSendType" SG_ 1172 STS_01_BZ 0;
BA_ "GenSigFuncType" SG_ 1172 STS_01_BZ 1;
BA_ "GenSigSwitchedByIgnition" SG_ 1172 STS_01_BZ 0;
BA_ "GenSigSendType" SG_ 1172 STS_01_CRC 0;
BA_ "GenSigFuncType" SG_ 1172 STS_01_CRC 2;
BA_ "GenSigSwitchedByIgnition" SG_ 1172 STS_01_CRC 0;
BA_ "GenSigSendType" SG_ 1172 STS_Alarm_Blinker 3;
BA_ "GenSigSwitchedByIgnition" SG_ 1172 STS_Alarm_Blinker 0;
BA_ "GenSigSendType" SG_ 1172 STS_Alarm_still 0;
BA_ "GenSigSwitchedByIgnition" SG_ 1172 STS_Alarm_still 0;
BA_ "GenSigSendType" SG_ 1172 STS_Anlassersperre 0;
BA_ "GenSigSwitchedByIgnition" SG_ 1172 STS_Anlassersperre 0;
BA_ "GenSigSendType" SG_ 1172 STS_Car_not_under_theft 0;
BA_ "GenSigStartValue" SG_ 1172 STS_Car_not_under_theft 1;
BA_ "GenSigSwitchedByIgnition" SG_ 1172 STS_Car_not_under_theft 0;
BA_ "GenSigSendType" SG_ 1172 STS_Car_under_theft 0;
BA_ "GenSigSwitchedByIgnition" SG_ 1172 STS_Car_under_theft 0;
BA_ "GenSigSendType" SG_ 1172 STS_Door_Lock 3;
BA_ "GenSigSwitchedByIgnition" SG_ 1172 STS_Door_Lock 0;
BA_ "GenSigSendType" SG_ 1172 STS_Fahrlicht 3;
BA_ "GenSigSwitchedByIgnition" SG_ 1172 STS_Fahrlicht 0;
BA_ "GenSigSendType" SG_ 1172 STS_Laderelais 3;
BA_ "GenSigSwitchedByIgnition" SG_ 1172 STS_Laderelais 0;
BA_ "GenSigSendType" SG_ 1172 STS_Leerlaufschaltung 0;
BA_ "GenSigSwitchedByIgnition" SG_ 1172 STS_Leerlaufschaltung 0;
BA_ "GenSigSendType" SG_ 1172 STS_LIN_aktiv 0;
BA_ "GenSigSwitchedByIgnition" SG_ 1172 STS_LIN_aktiv 0;
BA_ "GenSigSendType" SG_ 1172 STS_Notstart 3;
BA_ "GenSigSwitchedByIgnition" SG_ 1172 STS_Notstart 0;
BA_ "GenSigSendType" SG_ 1172 STS_Signalhorn 3;
BA_ "GenSigSwitchedByIgnition" SG_ 1172 STS_Signalhorn 0;
BA_ "GenSigSendType" SG_ 1172 STS_Spiegel_Anklappen 3;
BA_ "GenSigSwitchedByIgnition" SG_ 1172 STS_Spiegel_Anklappen 0;
BA_ "GenSigSendType" SG_ 1172 STS_Standlicht 3;
BA_ "GenSigSwitchedByIgnition" SG_ 1172 STS_Standlicht 0;
BA_ "GenSigSendType" SG_ 1172 STS_Summer 3;
BA_ "GenSigSwitchedByIgnition" SG_ 1172 STS_Summer 0;
BA_ "GenSigSendType" SG_ 1172 STS_Texte 0;
BA_ "GenSigStartValue" SG_ 1172 STS_Texte 14;
BA_ "GenSigSwitchedByIgnition" SG_ 1172 STS_Texte 0;
BA_ "Fehlerwert" SG_ 1172 STS_Texte 15;
BA_ "GenSigSendType" SG_ 1172 STS_Typencodierung 0;
BA_ "GenSigSwitchedByIgnition" SG_ 1172 STS_Typencodierung 0;
BA_ "GenSigSendType" SG_ 783 ASW_Kombitexte 3;
BA_ "GenSigSwitchedByIgnition" SG_ 783 ASW_Kombitexte 0;
BA_ "GenSigSendType" SG_ 783 ASW_Modus 0;
BA_ "GenSigStartValue" SG_ 783 ASW_Modus 4;
BA_ "GenSigSendType" SG_ 783 ASW_Status 3;
BA_ "GenSigSwitchedByIgnition" SG_ 783 ASW_Status 0;
BA_ "Fehlerwert" SG_ 783 ASW_Status 2;
BA_ "GenSigSendType" SG_ 783 ASW_Warnung_BFS 3;
BA_ "GenSigSwitchedByIgnition" SG_ 783 ASW_Warnung_BFS 0;
BA_ "GenSigSendType" SG_ 783 ASW_Warnung_FS 3;
BA_ "GenSigSwitchedByIgnition" SG_ 783 ASW_Warnung_FS 0;
BA_ "GenSigSendType" SG_ 783 Heckradar_Kombitexte 3;
BA_ "GenSigSwitchedByIgnition" SG_ 783 Heckradar_Kombitexte 0;
BA_ "GenSigSendType" SG_ 783 HRE_Anzeigetexte 0;
BA_ "GenSigSwitchedByIgnition" SG_ 783 HRE_Anzeigetexte 0;
BA_ "GenSigSendType" SG_ 783 RCTA_Kombitexte 3;
BA_ "GenSigSwitchedByIgnition" SG_ 783 RCTA_Kombitexte 0;
BA_ "GenSigSendType" SG_ 783 SWA_01_BZ 0;
BA_ "GenSigFuncType" SG_ 783 SWA_01_BZ 1;
BA_ "GenSigSwitchedByIgnition" SG_ 783 SWA_01_BZ 0;
BA_ "GenSigSendType" SG_ 783 SWA_01_CRC 0;
BA_ "GenSigFuncType" SG_ 783 SWA_01_CRC 2;
BA_ "GenSigSwitchedByIgnition" SG_ 783 SWA_01_CRC 0;
BA_ "GenSigSendType" SG_ 783 SWA_Anzeigen 3;
BA_ "GenSigSwitchedByIgnition" SG_ 783 SWA_Anzeigen 0;
BA_ "GenSigSendType" SG_ 783 SWA_Blindheit_erkannt 0;
BA_ "GenSigSendType" SG_ 783 SWA_FT_RueckLED 3;
BA_ "GenSigSwitchedByIgnition" SG_ 783 SWA_FT_RueckLED 0;
BA_ "GenSigSendType" SG_ 783 SWA_Infostufe_SWA_li 0;
BA_ "GenSigSendType" SG_ 783 SWA_Infostufe_SWA_re 0;
BA_ "GenSigSendType" SG_ 783 SWA_Kolonne_li 0;
BA_ "GenSigSendType" SG_ 783 SWA_Kolonne_mi 0;
BA_ "GenSigSendType" SG_ 783 SWA_Kolonne_re 0;
BA_ "GenSigSendType" SG_ 783 SWA_Modus 0;
BA_ "GenSigSendType" SG_ 783 SWA_rel_Fehler 0;
BA_ "Fehlerwert" SG_ 783 SWA_rel_Fehler 1;
BA_ "GenSigSendType" SG_ 783 SWA_rel_Nichtverf 0;
BA_ "GenSigSendType" SG_ 783 SWA_Sta_aktiv 0;
BA_ "GenSigSendType" SG_ 783 SWA_Sta_passiv 0;
BA_ "GenSigSendType" SG_ 783 SWA_Standziele_li 0;
BA_ "GenSigSendType" SG_ 783 SWA_Standziele_re 0;
BA_ "GenSigSendType" SG_ 783 SWA_Status_02 0;
BA_ "Fehlerwert" SG_ 783 SWA_Status_02 3;
BA_ "GenSigSendType" SG_ 783 SWA_Warnung_SWA_li 0;
BA_ "GenSigSendType" SG_ 783 SWA_Warnung_SWA_re 0;
BA_ "GenSigSendType" SG_ 673 SWA_LED_Hell_BFS 3;
BA_ "GenSigStartValue" SG_ 673 SWA_LED_Hell_BFS 126;
BA_ "Fehlerwert" SG_ 673 SWA_LED_Hell_BFS 127;
BA_ "GenSigSendType" SG_ 673 SWA_LED_Hell_FS 3;
BA_ "GenSigStartValue" SG_ 673 SWA_LED_Hell_FS 126;
BA_ "Fehlerwert" SG_ 673 SWA_LED_Hell_FS 127;
BA_ "GenSigSendType" SG_ 673 SWA_LED_Modus_BFS 3;
BA_ "GenSigSendType" SG_ 673 SWA_LED_Modus_FS 3;
BA_ "GenSigSendType" SG_ 1413 GW_KD_Fehler 3;
BA_ "GenSigSendType" SG_ 1413 SI_BUS_01 3;
BA_ "GenSigStartValue" SG_ 1413 SI_BUS_01 1;
BA_ "GenSigSwitchedByIgnition" SG_ 1413 SI_BUS_01 0;
BA_ "GenSigSendType" SG_ 1413 SI_BUS_02 3;
BA_ "GenSigStartValue" SG_ 1413 SI_BUS_02 1;
BA_ "GenSigSwitchedByIgnition" SG_ 1413 SI_BUS_02 0;
BA_ "GenSigSendType" SG_ 1413 SI_BUS_03 3;
BA_ "GenSigStartValue" SG_ 1413 SI_BUS_03 1;
BA_ "GenSigSwitchedByIgnition" SG_ 1413 SI_BUS_03 0;
BA_ "GenSigSendType" SG_ 1413 SI_BUS_04 3;
BA_ "GenSigStartValue" SG_ 1413 SI_BUS_04 1;
BA_ "GenSigSwitchedByIgnition" SG_ 1413 SI_BUS_04 0;
BA_ "GenSigSendType" SG_ 1413 SI_BUS_05 3;
BA_ "GenSigStartValue" SG_ 1413 SI_BUS_05 1;
BA_ "GenSigSwitchedByIgnition" SG_ 1413 SI_BUS_05 0;
BA_ "GenSigSendType" SG_ 1413 SI_BUS_06 3;
BA_ "GenSigStartValue" SG_ 1413 SI_BUS_06 1;
BA_ "GenSigSwitchedByIgnition" SG_ 1413 SI_BUS_06 0;
BA_ "GenSigSendType" SG_ 1413 SI_BUS_07 3;
BA_ "GenSigStartValue" SG_ 1413 SI_BUS_07 1;
BA_ "GenSigSwitchedByIgnition" SG_ 1413 SI_BUS_07 0;
BA_ "GenSigSendType" SG_ 1413 SI_BUS_08 3;
BA_ "GenSigStartValue" SG_ 1413 SI_BUS_08 1;
BA_ "GenSigSwitchedByIgnition" SG_ 1413 SI_BUS_08 0;
BA_ "GenSigSendType" SG_ 1413 SI_BUS_09 3;
BA_ "GenSigStartValue" SG_ 1413 SI_BUS_09 1;
BA_ "GenSigSwitchedByIgnition" SG_ 1413 SI_BUS_09 0;
BA_ "GenSigSendType" SG_ 1413 SI_BUS_10 3;
BA_ "GenSigStartValue" SG_ 1413 SI_BUS_10 1;
BA_ "GenSigSwitchedByIgnition" SG_ 1413 SI_BUS_10 0;
BA_ "GenSigSendType" SG_ 1413 SI_BUS_11 3;
BA_ "GenSigStartValue" SG_ 1413 SI_BUS_11 1;
BA_ "GenSigSwitchedByIgnition" SG_ 1413 SI_BUS_11 0;
BA_ "GenSigSendType" SG_ 1413 SI_BUS_12 3;
BA_ "GenSigStartValue" SG_ 1413 SI_BUS_12 1;
BA_ "GenSigSwitchedByIgnition" SG_ 1413 SI_BUS_12 0;
BA_ "GenSigSendType" SG_ 1413 SI_BUS_13 3;
BA_ "GenSigStartValue" SG_ 1413 SI_BUS_13 1;
BA_ "GenSigSwitchedByIgnition" SG_ 1413 SI_BUS_13 0;
BA_ "GenSigSendType" SG_ 1413 SI_BUS_14 3;
BA_ "GenSigStartValue" SG_ 1413 SI_BUS_14 1;
BA_ "GenSigSwitchedByIgnition" SG_ 1413 SI_BUS_14 0;
BA_ "GenSigSendType" SG_ 1413 SI_BUS_15 3;
BA_ "GenSigStartValue" SG_ 1413 SI_BUS_15 1;
BA_ "GenSigSwitchedByIgnition" SG_ 1413 SI_BUS_15 0;
BA_ "GenSigSendType" SG_ 1413 SI_Bus_Identifikation 0;
BA_ "GenSigSwitchedByIgnition" SG_ 1413 SI_Bus_Identifikation 0;
BA_ "GenSigSendType" SG_ 1413 SI_CAB 3;
BA_ "GenSigFuncType" SG_ 1413 SI_CAB 16;
BA_ "GenSigSwitchedByIgnition" SG_ 1413 SI_CAB 0;
BA_ "GenSigSendType" SG_ 1413 SI_Diagnose_Aktiv 3;
BA_ "GenSigSwitchedByIgnition" SG_ 1413 SI_Diagnose_Aktiv 0;
BA_ "GenSigSendType" SG_ 1413 SI_NWDF 3;
BA_ "GenSigSwitchedByIgnition" SG_ 1413 SI_NWDF 0;
BA_ "GenSigSendType" SG_ 1413 SI_NWDF_gueltig 3;
BA_ "GenSigFuncType" SG_ 1413 SI_NWDF_gueltig 8;
BA_ "GenSigSwitchedByIgnition" SG_ 1413 SI_NWDF_gueltig 0;
BA_ "GenSigSendType" SG_ 1413 SI_QRS_Mode 3;
BA_ "GenSigSwitchedByIgnition" SG_ 1413 SI_QRS_Mode 0;
BA_ "GenSigSendType" SG_ 1413 SI_Sammel_SG_Fehler 0;
BA_ "GenSigStartValue" SG_ 1413 SI_Sammel_SG_Fehler 63;
BA_ "GenSigSwitchedByIgnition" SG_ 1413 SI_Sammel_SG_Fehler 0;
BA_ "GenSigSendType" SG_ 1413 SI_Sammelfehler 3;
BA_ "GenSigSwitchedByIgnition" SG_ 1413 SI_Sammelfehler 0;
BA_ "GenSigSendType" SG_ 1413 SI_T_Mode 3;
BA_ "GenSigSwitchedByIgnition" SG_ 1413 SI_T_Mode 0;
BA_ "GenSigSendType" SG_ 1413 SI_T_Schutz 3;
BA_ "GenSigSwitchedByIgnition" SG_ 1413 SI_T_Schutz 0;
BA_ "GenSigSendType" SG_ 1015 KL_HV_Energie_Anf 0;
BA_ "GenSigStartValue" SG_ 1015 KL_HV_Energie_Anf 254;
BA_ "GenSigSwitchedByIgnition" SG_ 1015 KL_HV_Energie_Anf 0;
BA_ "Fehlerwert" SG_ 1015 KL_HV_Energie_Anf 255;
BA_ "GenSigSendType" SG_ 1015 TME_EKK_Fehlerstatus 0;
BA_ "GenSigStartValue" SG_ 1015 TME_EKK_Fehlerstatus 7;
BA_ "GenSigSwitchedByIgnition" SG_ 1015 TME_EKK_Fehlerstatus 0;
BA_ "GenSigSendType" SG_ 1015 TME_EKK_Istmodus 0;
BA_ "GenSigStartValue" SG_ 1015 TME_EKK_Istmodus 7;
BA_ "GenSigSwitchedByIgnition" SG_ 1015 TME_EKK_Istmodus 0;
BA_ "Fehlerwert" SG_ 1015 TME_EKK_Istmodus 5;
BA_ "GenSigSendType" SG_ 1015 TME_HVEM_HV_Anf 0;
BA_ "GenSigSwitchedByIgnition" SG_ 1015 TME_HVEM_HV_Anf 0;
BA_ "Fehlerwert" SG_ 1015 TME_HVEM_HV_Anf 3;
BA_ "GenSigSendType" SG_ 1015 TME_HVK_EKK_SOLL 0;
BA_ "GenSigSwitchedByIgnition" SG_ 1015 TME_HVK_EKK_SOLL 0;
BA_ "Fehlerwert" SG_ 1015 TME_HVK_EKK_SOLL 3;
BA_ "GenSigSendType" SG_ 1015 TME_HVPTC_Fehlerstatus 0;
BA_ "GenSigStartValue" SG_ 1015 TME_HVPTC_Fehlerstatus 7;
BA_ "GenSigSwitchedByIgnition" SG_ 1015 TME_HVPTC_Fehlerstatus 0;
BA_ "GenSigSendType" SG_ 1015 TME_HVPTC_Istmodus 0;
BA_ "GenSigStartValue" SG_ 1015 TME_HVPTC_Istmodus 7;
BA_ "GenSigSwitchedByIgnition" SG_ 1015 TME_HVPTC_Istmodus 0;
BA_ "Fehlerwert" SG_ 1015 TME_HVPTC_Istmodus 5;
BA_ "GenSigSendType" SG_ 1015 TME_Kuehlerluefer_3 0;
BA_ "GenSigStartValue" SG_ 1015 TME_Kuehlerluefer_3 126;
BA_ "GenSigSwitchedByIgnition" SG_ 1015 TME_Kuehlerluefer_3 0;
BA_ "Fehlerwert" SG_ 1015 TME_Kuehlerluefer_3 127;
BA_ "GenSigSendType" SG_ 1015 TME_OBD_Lampe_Anf 0;
BA_ "GenSigSwitchedByIgnition" SG_ 1015 TME_OBD_Lampe_Anf 0;
BA_ "GenSigSendType" SG_ 1015 TME_PWM_Pumpe1_tNT_Soll 0;
BA_ "GenSigStartValue" SG_ 1015 TME_PWM_Pumpe1_tNT_Soll 126;
BA_ "GenSigSwitchedByIgnition" SG_ 1015 TME_PWM_Pumpe1_tNT_Soll 0;
BA_ "Fehlerwert" SG_ 1015 TME_PWM_Pumpe1_tNT_Soll 127;
BA_ "GenSigSendType" SG_ 1015 TME_StartStopp_Info 0;
BA_ "Fehlerwert" SG_ 1015 TME_StartStopp_Info 3;
BA_ "GenSigSendType" SG_ 1015 TME_StartStopp_Info_Prio 0;
BA_ "GenSigSwitchedByIgnition" SG_ 1015 TME_StartStopp_Info_Prio 0;
BA_ "GenSigSendType" SG_ 1015 TME_Strom_Kuehlerluefter 0;
BA_ "GenSigStartValue" SG_ 1015 TME_Strom_Kuehlerluefter 30;
BA_ "GenSigSwitchedByIgnition" SG_ 1015 TME_Strom_Kuehlerluefter 0;
BA_ "Fehlerwert" SG_ 1015 TME_Strom_Kuehlerluefter 31;
BA_ "GenSigSendType" SG_ 1017 TME_Anf_KL 0;
BA_ "GenSigStartValue" SG_ 1017 TME_Anf_KL 126;
BA_ "GenSigSwitchedByIgnition" SG_ 1017 TME_Anf_KL 0;
BA_ "Fehlerwert" SG_ 1017 TME_Anf_KL 127;
BA_ "GenSigSendType" SG_ 1017 TME_EM1_IstVolumenstrom 0;
BA_ "GenSigStartValue" SG_ 1017 TME_EM1_IstVolumenstrom 30;
BA_ "GenSigSwitchedByIgnition" SG_ 1017 TME_EM1_IstVolumenstrom 0;
BA_ "Fehlerwert" SG_ 1017 TME_EM1_IstVolumenstrom 31;
BA_ "GenSigSendType" SG_ 1017 TME_EM2_IstVolumenstrom 0;
BA_ "GenSigStartValue" SG_ 1017 TME_EM2_IstVolumenstrom 30;
BA_ "GenSigSwitchedByIgnition" SG_ 1017 TME_EM2_IstVolumenstrom 0;
BA_ "Fehlerwert" SG_ 1017 TME_EM2_IstVolumenstrom 31;
BA_ "GenSigSendType" SG_ 1017 TME_EM3_IstVolumenstrom 0;
BA_ "GenSigStartValue" SG_ 1017 TME_EM3_IstVolumenstrom 30;
BA_ "GenSigSwitchedByIgnition" SG_ 1017 TME_EM3_IstVolumenstrom 0;
BA_ "Fehlerwert" SG_ 1017 TME_EM3_IstVolumenstrom 31;
BA_ "GenSigSendType" SG_ 1017 TME_Fehler_ElWaPu1 0;
BA_ "GenSigSwitchedByIgnition" SG_ 1017 TME_Fehler_ElWaPu1 0;
BA_ "Fehlerwert" SG_ 1017 TME_Fehler_ElWaPu1 1;
BA_ "GenSigSendType" SG_ 1017 TME_MMTR_Status 0;
BA_ "GenSigStartValue" SG_ 1017 TME_MMTR_Status 14;
BA_ "GenSigSwitchedByIgnition" SG_ 1017 TME_MMTR_Status 0;
BA_ "Fehlerwert" SG_ 1017 TME_MMTR_Status 15;
BA_ "GenSigSendType" SG_ 1017 TME_Nachlaufzeit 0;
BA_ "GenSigSwitchedByIgnition" SG_ 1017 TME_Nachlaufzeit 0;
BA_ "GenSigSendType" SG_ 1017 TME_NT_Kreis_Status 0;
BA_ "GenSigSwitchedByIgnition" SG_ 1017 TME_NT_Kreis_Status 0;
BA_ "Fehlerwert" SG_ 1017 TME_NT_Kreis_Status 1;
BA_ "GenSigSendType" SG_ 1017 TME_Pumpe1_Status 0;
BA_ "GenSigSwitchedByIgnition" SG_ 1017 TME_Pumpe1_Status 0;
BA_ "GenSigSendType" SG_ 1017 TME_PWM_Pumpe2_HK_Soll 0;
BA_ "GenSigStartValue" SG_ 1017 TME_PWM_Pumpe2_HK_Soll 126;
BA_ "GenSigSwitchedByIgnition" SG_ 1017 TME_PWM_Pumpe2_HK_Soll 0;
BA_ "Fehlerwert" SG_ 1017 TME_PWM_Pumpe2_HK_Soll 127;
BA_ "GenSigSendType" SG_ 1017 TME_Status_KL 0;
BA_ "GenSigSwitchedByIgnition" SG_ 1017 TME_Status_KL 0;
BA_ "GenSigSendType" SG_ 1017 TME_Ventil1_Status 0;
BA_ "GenSigSwitchedByIgnition" SG_ 1017 TME_Ventil1_Status 0;
BA_ "GenSigSendType" SG_ 1375 TME_Absperrventil1_oeffnen 0;
BA_ "GenSigSwitchedByIgnition" SG_ 1375 TME_Absperrventil1_oeffnen 0;
BA_ "GenSigSendType" SG_ 1375 TME_AC_LED 3;
BA_ "GenSigSwitchedByIgnition" SG_ 1375 TME_AC_LED 0;
BA_ "GenSigSendType" SG_ 1375 TME_AC_Rueckmeldung 0;
BA_ "GenSigSwitchedByIgnition" SG_ 1375 TME_AC_Rueckmeldung 0;
BA_ "Fehlerwert" SG_ 1375 TME_AC_Rueckmeldung 3;
BA_ "GenSigSendType" SG_ 1375 TME_Freigabe_Luft_PTC 0;
BA_ "GenSigSwitchedByIgnition" SG_ 1375 TME_Freigabe_Luft_PTC 0;
BA_ "GenSigSendType" SG_ 1375 TME_Freigabe_Vorkond 3;
BA_ "GenSigSwitchedByIgnition" SG_ 1375 TME_Freigabe_Vorkond 0;
BA_ "GenSigSendType" SG_ 1375 TME_Frischluftklappe_Soll 0;
BA_ "GenSigStartValue" SG_ 1375 TME_Frischluftklappe_Soll 126;
BA_ "GenSigSwitchedByIgnition" SG_ 1375 TME_Frischluftklappe_Soll 0;
BA_ "Fehlerwert" SG_ 1375 TME_Frischluftklappe_Soll 127;
BA_ "GenSigSendType" SG_ 1375 TME_Heizstrategie 3;
BA_ "GenSigSwitchedByIgnition" SG_ 1375 TME_Heizstrategie 0;
BA_ "Fehlerwert" SG_ 1375 TME_Heizstrategie 15;
BA_ "GenSigSendType" SG_ 1375 TME_Heizungspumpen_Anst 0;
BA_ "GenSigStartValue" SG_ 1375 TME_Heizungspumpen_Anst 14;
BA_ "GenSigSwitchedByIgnition" SG_ 1375 TME_Heizungspumpen_Anst 0;
BA_ "Fehlerwert" SG_ 1375 TME_Heizungspumpen_Anst 13;
BA_ "GenSigSendType" SG_ 1375 TME_Kbr_Innenraum 3;
BA_ "GenSigSwitchedByIgnition" SG_ 1375 TME_Kbr_Innenraum 0;
BA_ "GenSigSendType" SG_ 1375 TME_Klima_Defizit 0;
BA_ "GenSigStartValue" SG_ 1375 TME_Klima_Defizit 254;
BA_ "GenSigSwitchedByIgnition" SG_ 1375 TME_Klima_Defizit 0;
BA_ "Fehlerwert" SG_ 1375 TME_Klima_Defizit 255;
BA_ "GenSigSendType" SG_ 1375 TME_Kuehlmittel_Sensor 0;
BA_ "GenSigSwitchedByIgnition" SG_ 1375 TME_Kuehlmittel_Sensor 0;
BA_ "GenSigSendType" SG_ 1375 TME_Nachlaufzeit_Heizp 0;
BA_ "GenSigSwitchedByIgnition" SG_ 1375 TME_Nachlaufzeit_Heizp 0;
BA_ "GenSigSendType" SG_ 1375 TME_Systemstatus 3;
BA_ "GenSigSwitchedByIgnition" SG_ 1375 TME_Systemstatus 0;
BA_ "Fehlerwert" SG_ 1375 TME_Systemstatus 3;
BA_ "GenSigSendType" SG_ 1375 TME_Temp_KM_vor_HWT 0;
BA_ "GenSigStartValue" SG_ 1375 TME_Temp_KM_vor_HWT 254;
BA_ "GenSigSwitchedByIgnition" SG_ 1375 TME_Temp_KM_vor_HWT 0;
BA_ "Fehlerwert" SG_ 1375 TME_Temp_KM_vor_HWT 255;
BA_ "GenSigSendType" SG_ 1375 TME_Umluftklappe_Soll 0;
BA_ "GenSigSwitchedByIgnition" SG_ 1375 TME_Umluftklappe_Soll 0;
BA_ "Fehlerwert" SG_ 1375 TME_Umluftklappe_Soll 127;
BA_ "GenSigSendType" SG_ 1375 TME_Verdampfer_Status 3;
BA_ "GenSigSwitchedByIgnition" SG_ 1375 TME_Verdampfer_Status 0;
BA_ "GenSigSendType" SG_ 1375 TME_VoKo_Strategie_Anzeige 3;
BA_ "GenSigStartValue" SG_ 1375 TME_VoKo_Strategie_Anzeige 14;
BA_ "GenSigSwitchedByIgnition" SG_ 1375 TME_VoKo_Strategie_Anzeige 0;
BA_ "Fehlerwert" SG_ 1375 TME_VoKo_Strategie_Anzeige 15;
BA_ "GenSigSendType" SG_ 1375 TME_Waermepumpe_aktiv 0;
BA_ "GenSigSwitchedByIgnition" SG_ 1375 TME_Waermepumpe_aktiv 0;
BA_ "GenSigSendType" SG_ 1375 TME_Zuheizer_Freigabe 3;
BA_ "GenSigSwitchedByIgnition" SG_ 1375 TME_Zuheizer_Freigabe 0;
BA_ "GenSigSendType" SG_ 1373 TME_Geblaese 0;
BA_ "GenSigSwitchedByIgnition" SG_ 1373 TME_Geblaese 0;
BA_ "GenSigSendType" SG_ 1373 TME_IstSpannung_EKK_HV 0;
BA_ "GenSigStartValue" SG_ 1373 TME_IstSpannung_EKK_HV 255;
BA_ "GenSigSwitchedByIgnition" SG_ 1373 TME_IstSpannung_EKK_HV 0;
BA_ "GenSigSendType" SG_ 1373 TME_Klimadefizit 0;
BA_ "GenSigSwitchedByIgnition" SG_ 1373 TME_Klimadefizit 0;
BA_ "GenSigSendType" SG_ 1373 TME_Kond_Innen_Betrieb 3;
BA_ "GenSigSwitchedByIgnition" SG_ 1373 TME_Kond_Innen_Betrieb 0;
BA_ "GenSigSendType" SG_ 1373 TME_Kond_Innen_Betriebsdauer 3;
BA_ "GenSigSwitchedByIgnition" SG_ 1373 TME_Kond_Innen_Betriebsdauer 0;
BA_ "GenSigSendType" SG_ 1373 TME_Kond_Innen_Status 3;
BA_ "GenSigSwitchedByIgnition" SG_ 1373 TME_Kond_Innen_Status 0;
BA_ "GenSigSendType" SG_ 1373 TME_Kuehlmittel_Temp_Pumpe1_tNT 0;
BA_ "GenSigStartValue" SG_ 1373 TME_Kuehlmittel_Temp_Pumpe1_tNT 254;
BA_ "GenSigSwitchedByIgnition" SG_ 1373 TME_Kuehlmittel_Temp_Pumpe1_tNT 0;
BA_ "Fehlerwert" SG_ 1373 TME_Kuehlmittel_Temp_Pumpe1_tNT 255;
BA_ "GenSigSendType" SG_ 1373 TME_SKE_Status_2 0;
BA_ "GenSigSwitchedByIgnition" SG_ 1373 TME_SKE_Status_2 0;
BA_ "Fehlerwert" SG_ 1373 TME_SKE_Status_2 3;
BA_ "GenSigSendType" SG_ 1373 TME_STH_aktiv 3;
BA_ "GenSigSwitchedByIgnition" SG_ 1373 TME_STH_aktiv 0;
BA_ "Fehlerwert" SG_ 1373 TME_STH_aktiv 3;
BA_ "GenSigSendType" SG_ 1373 TME_STH_Ansteuerung 3;
BA_ "GenSigSwitchedByIgnition" SG_ 1373 TME_STH_Ansteuerung 0;
BA_ "GenSigSendType" SG_ 1373 TME_STH_Status 3;
BA_ "GenSigSwitchedByIgnition" SG_ 1373 TME_STH_Status 0;
BA_ "Fehlerwert" SG_ 1373 TME_STH_Status 7;
BA_ "GenSigSendType" SG_ 1373 TME_STL_aktiv 3;
BA_ "GenSigSwitchedByIgnition" SG_ 1373 TME_STL_aktiv 0;
BA_ "Fehlerwert" SG_ 1373 TME_STL_aktiv 3;
BA_ "GenSigSendType" SG_ 1373 TME_Temp_KM_vor_LE 0;
BA_ "GenSigStartValue" SG_ 1373 TME_Temp_KM_vor_LE 254;
BA_ "GenSigSwitchedByIgnition" SG_ 1373 TME_Temp_KM_vor_LE 0;
BA_ "Fehlerwert" SG_ 1373 TME_Temp_KM_vor_LE 255;
BA_ "GenSigSendType" SG_ 1373 TME_Thermomanagement 0;
BA_ "GenSigSwitchedByIgnition" SG_ 1373 TME_Thermomanagement 0;
BA_ "GenSigSendType" SG_ 1373 TME_Verdampfertemperatur 0;
BA_ "GenSigStartValue" SG_ 1373 TME_Verdampfertemperatur 1022;
BA_ "GenSigSwitchedByIgnition" SG_ 1373 TME_Verdampfertemperatur 0;
BA_ "Fehlerwert" SG_ 1373 TME_Verdampfertemperatur 1023;
BA_ "GenSigSendType" SG_ 1657 TME_Eingriff_SKE_Oeffnung 0;
BA_ "GenSigSwitchedByIgnition" SG_ 1657 TME_Eingriff_SKE_Oeffnung 0;
BA_ "GenSigSendType" SG_ 1657 TME_EKK_ProtectionMode 0;
BA_ "GenSigSwitchedByIgnition" SG_ 1657 TME_EKK_ProtectionMode 0;
BA_ "GenSigSendType" SG_ 1657 TME_Klimaanforderung 0;
BA_ "GenSigSwitchedByIgnition" SG_ 1657 TME_Klimaanforderung 0;
BA_ "GenSigSendType" SG_ 1657 TME_Klimaleistung 0;
BA_ "GenSigStartValue" SG_ 1657 TME_Klimaleistung 126;
BA_ "GenSigSwitchedByIgnition" SG_ 1657 TME_Klimaleistung 0;
BA_ "GenSigSendType" SG_ 1657 TME_SKE_Pos_Summe 0;
BA_ "GenSigStartValue" SG_ 1657 TME_SKE_Pos_Summe 14;
BA_ "GenSigSwitchedByIgnition" SG_ 1657 TME_SKE_Pos_Summe 0;
BA_ "GenSigSendType" SG_ 1657 TME_SKE_Position_1 0;
BA_ "GenSigStartValue" SG_ 1657 TME_SKE_Position_1 3;
BA_ "GenSigSwitchedByIgnition" SG_ 1657 TME_SKE_Position_1 0;
BA_ "GenSigSendType" SG_ 1657 TME_SKE_PosResp 0;
BA_ "GenSigStartValue" SG_ 1657 TME_SKE_PosResp 1;
BA_ "GenSigSwitchedByIgnition" SG_ 1657 TME_SKE_PosResp 0;
BA_ "GenSigSendType" SG_ 1657 TME_SKE_Status 0;
BA_ "GenSigSwitchedByIgnition" SG_ 1657 TME_SKE_Status 0;
BA_ "Fehlerwert" SG_ 1657 TME_SKE_Status 3;
BA_ "GenSigSendType" SG_ 1657 TME_Status_Kuehlmittel_Tmp_CrChk 0;
BA_ "GenSigSwitchedByIgnition" SG_ 1657 TME_Status_Kuehlmittel_Tmp_CrChk 0;
BA_ "GenSigSendType" SG_ 1657 TME_Systemtemp 0;
BA_ "GenSigStartValue" SG_ 1657 TME_Systemtemp 254;
BA_ "GenSigSwitchedByIgnition" SG_ 1657 TME_Systemtemp 0;
BA_ "Fehlerwert" SG_ 1657 TME_Systemtemp 255;
BA_ "GenSigSendType" SG_ 1657 TME_TCP_Kond_active 0;
BA_ "GenSigSwitchedByIgnition" SG_ 1657 TME_TCP_Kond_active 0;
BA_ "GenSigSendType" SG_ 1657 TME_Temp_KM_nach_EM 0;
BA_ "GenSigStartValue" SG_ 1657 TME_Temp_KM_nach_EM 254;
BA_ "GenSigSwitchedByIgnition" SG_ 1657 TME_Temp_KM_nach_EM 0;
BA_ "Fehlerwert" SG_ 1657 TME_Temp_KM_nach_EM 255;
BA_ "GenSigSendType" SG_ 1657 TME_Temp_KM_vor_eATL 0;
BA_ "GenSigSwitchedByIgnition" SG_ 1657 TME_Temp_KM_vor_eATL 0;
BA_ "Fehlerwert" SG_ 1657 TME_Temp_KM_vor_eATL 255;
BA_ "GenSigSendType" SG_ 1657 TME_Temperatur_Ruecklauf_VKM 0;
BA_ "GenSigStartValue" SG_ 1657 TME_Temperatur_Ruecklauf_VKM 254;
BA_ "GenSigSwitchedByIgnition" SG_ 1657 TME_Temperatur_Ruecklauf_VKM 0;
BA_ "Fehlerwert" SG_ 1657 TME_Temperatur_Ruecklauf_VKM 255;
BA_ "GenSigSendType" SG_ 1657 TME_Waermebilanz 0;
BA_ "GenSigSwitchedByIgnition" SG_ 1657 TME_Waermebilanz 0;
BA_ "GenSigSendType" SG_ 1657 TME_Waermebilanz_Status 0;
BA_ "GenSigSwitchedByIgnition" SG_ 1657 TME_Waermebilanz_Status 0;
BA_ "Fehlerwert" SG_ 1657 TME_Waermebilanz_Status 3;
BA_ "GenSigSendType" SG_ 977 ASW_Warnung_aktiv_BFS 3;
BA_ "GenSigSwitchedByIgnition" SG_ 977 ASW_Warnung_aktiv_BFS 0;
BA_ "GenSigSendType" SG_ 977 BFS_Status_eTAG 0;
BA_ "GenSigSwitchedByIgnition" SG_ 977 BFS_Status_eTAG 0;
BA_ "Fehlerwert" SG_ 977 BFS_Status_eTAG 3;
BA_ "GenSigSendType" SG_ 977 BT_ASW_HMI_defekt 0;
BA_ "GenSigSwitchedByIgnition" SG_ 977 BT_ASW_HMI_defekt 0;
BA_ "GenSigSendType" SG_ 977 BT_EC_Spiegel_Helligkeit 3;
BA_ "GenSigSwitchedByIgnition" SG_ 977 BT_EC_Spiegel_Helligkeit 0;
BA_ "GenSigSendType" SG_ 977 BT_FH_Bew_hoch 3;
BA_ "GenSigSwitchedByIgnition" SG_ 977 BT_FH_Bew_hoch 0;
BA_ "GenSigSendType" SG_ 977 BT_FH_Bew_tief 3;
BA_ "GenSigSwitchedByIgnition" SG_ 977 BT_FH_Bew_tief 0;
BA_ "GenSigSendType" SG_ 977 BT_FH_Block 3;
BA_ "GenSigSwitchedByIgnition" SG_ 977 BT_FH_Block 0;
BA_ "GenSigSendType" SG_ 977 BT_FH_Fang 3;
BA_ "GenSigSwitchedByIgnition" SG_ 977 BT_FH_Fang 0;
BA_ "GenSigSendType" SG_ 977 BT_FH_normiert 3;
BA_ "GenSigSwitchedByIgnition" SG_ 977 BT_FH_normiert 0;
BA_ "GenSigSendType" SG_ 977 BT_FH_Oeffnung 3;
BA_ "GenSigSwitchedByIgnition" SG_ 977 BT_FH_Oeffnung 0;
BA_ "GenSigSendType" SG_ 977 BT_FH_Pos_oben 3;
BA_ "GenSigSwitchedByIgnition" SG_ 977 BT_FH_Pos_oben 0;
BA_ "GenSigSendType" SG_ 977 BT_FH_S_AutoHoch 3;
BA_ "GenSigSwitchedByIgnition" SG_ 977 BT_FH_S_AutoHoch 0;
BA_ "GenSigSendType" SG_ 977 BT_FH_S_AutoTief 3;
BA_ "GenSigSwitchedByIgnition" SG_ 977 BT_FH_S_AutoTief 0;
BA_ "GenSigSendType" SG_ 977 BT_FH_S_ManHoch 3;
BA_ "GenSigSwitchedByIgnition" SG_ 977 BT_FH_S_ManHoch 0;
BA_ "GenSigSendType" SG_ 977 BT_FH_S_ManTief 3;
BA_ "GenSigSwitchedByIgnition" SG_ 977 BT_FH_S_ManTief 0;
BA_ "GenSigSendType" SG_ 977 BT_FH_Thermo 3;
BA_ "GenSigSwitchedByIgnition" SG_ 977 BT_FH_Thermo 0;
BA_ "GenSigSendType" SG_ 977 BT_gesafet 3;
BA_ "GenSigSwitchedByIgnition" SG_ 977 BT_gesafet 0;
BA_ "GenSigSendType" SG_ 977 BT_Kisi_Fehler 3;
BA_ "GenSigSwitchedByIgnition" SG_ 977 BT_Kisi_Fehler 0;
BA_ "Fehlerwert" SG_ 977 BT_Kisi_Fehler 1;
BA_ "GenSigSendType" SG_ 977 BT_Lock_Taster 3;
BA_ "GenSigSwitchedByIgnition" SG_ 977 BT_Lock_Taster 0;
BA_ "GenSigSendType" SG_ 977 BT_Lock_Taster_inv 3;
BA_ "GenSigSwitchedByIgnition" SG_ 977 BT_Lock_Taster_inv 0;
BA_ "GenSigSendType" SG_ 977 BT_Oben_Block_erw 3;
BA_ "GenSigSwitchedByIgnition" SG_ 977 BT_Oben_Block_erw 0;
BA_ "GenSigSendType" SG_ 977 BT_Schliesstaster 3;
BA_ "GenSigSwitchedByIgnition" SG_ 977 BT_Schliesstaster 0;
BA_ "GenSigSendType" SG_ 977 BT_Schluesselschalter_auf 3;
BA_ "GenSigSwitchedByIgnition" SG_ 977 BT_Schluesselschalter_auf 0;
BA_ "GenSigSendType" SG_ 977 BT_Schluesselschalter_zu 3;
BA_ "GenSigSwitchedByIgnition" SG_ 977 BT_Schluesselschalter_zu 0;
BA_ "GenSigSendType" SG_ 977 BT_Schluesselschalter_zu_inv 3;
BA_ "GenSigSwitchedByIgnition" SG_ 977 BT_Schluesselschalter_zu_inv 0;
BA_ "GenSigSendType" SG_ 977 BT_SP_ausgerastet 3;
BA_ "GenSigSwitchedByIgnition" SG_ 977 BT_SP_ausgerastet 0;
BA_ "GenSigSendType" SG_ 977 BT_Sp_Blk_def 3;
BA_ "GenSigSwitchedByIgnition" SG_ 977 BT_Sp_Blk_def 0;
BA_ "GenSigSendType" SG_ 977 BT_SP_Heizung_aktiv 3;
BA_ "GenSigSwitchedByIgnition" SG_ 977 BT_SP_Heizung_aktiv 0;
BA_ "GenSigSendType" SG_ 977 BT_Sp_Heizung_Anf 0;
BA_ "GenSigSwitchedByIgnition" SG_ 977 BT_Sp_Heizung_Anf 0;
BA_ "GenSigSendType" SG_ 977 BT_SP_Heizung_Status 3;
BA_ "GenSigSwitchedByIgnition" SG_ 977 BT_SP_Heizung_Status 0;
BA_ "GenSigSendType" SG_ 977 BT_SP_ht_aktiv 3;
BA_ "GenSigSwitchedByIgnition" SG_ 977 BT_SP_ht_aktiv 0;
BA_ "GenSigSendType" SG_ 977 BT_SP_lr_aktiv 3;
BA_ "GenSigSwitchedByIgnition" SG_ 977 BT_SP_lr_aktiv 0;
BA_ "GenSigSendType" SG_ 977 BT_Sperrklinke 3;
BA_ "GenSigSwitchedByIgnition" SG_ 977 BT_Sperrklinke 0;
BA_ "GenSigSendType" SG_ 977 BT_SWA_HMI_defekt 0;
BA_ "GenSigSwitchedByIgnition" SG_ 977 BT_SWA_HMI_defekt 0;
BA_ "GenSigSendType" SG_ 977 BT_TAG_betaetigt 3;
BA_ "GenSigSwitchedByIgnition" SG_ 977 BT_TAG_betaetigt 0;
BA_ "GenSigSendType" SG_ 977 BT_TCR_Mode_aktiv 0;
BA_ "GenSigSwitchedByIgnition" SG_ 977 BT_TCR_Mode_aktiv 0;
BA_ "GenSigSendType" SG_ 977 BT_TIG_betaetigt 3;
BA_ "GenSigSwitchedByIgnition" SG_ 977 BT_TIG_betaetigt 0;
BA_ "GenSigSendType" SG_ 977 BT_TSG_hinten_verbaut 3;
BA_ "GenSigSwitchedByIgnition" SG_ 977 BT_TSG_hinten_verbaut 0;
BA_ "GenSigSendType" SG_ 977 BT_Tuer_geoeffnet 3;
BA_ "GenSigSwitchedByIgnition" SG_ 977 BT_Tuer_geoeffnet 0;
BA_ "GenSigSendType" SG_ 977 BT_Tuer_Status 3;
BA_ "GenSigSwitchedByIgnition" SG_ 977 BT_Tuer_Status 0;
BA_ "Fehlerwert" SG_ 977 BT_Tuer_Status 3;
BA_ "GenSigSendType" SG_ 977 BT_Tuer_Status_QBit 0;
BA_ "GenSigSwitchedByIgnition" SG_ 977 BT_Tuer_Status_QBit 0;
BA_ "GenSigSendType" SG_ 977 BT_Tueroeffnen_Warnung 3;
BA_ "GenSigSwitchedByIgnition" SG_ 977 BT_Tueroeffnen_Warnung 0;
BA_ "GenSigSendType" SG_ 977 BT_Tuerschloss_defekt 0;
BA_ "GenSigSwitchedByIgnition" SG_ 977 BT_Tuerschloss_defekt 0;
BA_ "GenSigSendType" SG_ 977 BT_UEKB_aktiviert 3;
BA_ "GenSigSwitchedByIgnition" SG_ 977 BT_UEKB_aktiviert 0;
BA_ "GenSigSendType" SG_ 977 BT_Unlock_Taster 3;
BA_ "GenSigSwitchedByIgnition" SG_ 977 BT_Unlock_Taster 0;
BA_ "GenSigSendType" SG_ 977 BT_Unten_Block_erw 3;
BA_ "GenSigSwitchedByIgnition" SG_ 977 BT_Unten_Block_erw 0;
BA_ "GenSigSendType" SG_ 977 BT_verriegelt 3;
BA_ "GenSigSwitchedByIgnition" SG_ 977 BT_verriegelt 0;
BA_ "GenSigSendType" SG_ 977 BT_Zuziehhilfe_aktiv 3;
BA_ "GenSigSwitchedByIgnition" SG_ 977 BT_Zuziehhilfe_aktiv 0;
BA_ "GenSigSendType" SG_ 1451 TSG_FlHz_BFS_FnAbbruchHzKreis_A 3;
BA_ "GenSigSwitchedByIgnition" SG_ 1451 TSG_FlHz_BFS_FnAbbruchHzKreis_A 0;
BA_ "GenSigSendType" SG_ 1451 TSG_FlHz_BFS_FnAbbruchHzKreis_B 3;
BA_ "GenSigSwitchedByIgnition" SG_ 1451 TSG_FlHz_BFS_FnAbbruchHzKreis_B 0;
BA_ "GenSigSendType" SG_ 1451 TSG_FlHz_BFS_NTC_A 3;
BA_ "GenSigStartValue" SG_ 1451 TSG_FlHz_BFS_NTC_A 127;
BA_ "GenSigSwitchedByIgnition" SG_ 1451 TSG_FlHz_BFS_NTC_A 0;
BA_ "GenSigSendType" SG_ 1451 TSG_FlHz_BFS_NTC_B 3;
BA_ "GenSigStartValue" SG_ 1451 TSG_FlHz_BFS_NTC_B 127;
BA_ "GenSigSwitchedByIgnition" SG_ 1451 TSG_FlHz_BFS_NTC_B 0;
BA_REL_ "GenSigTimeoutTime" BU_SG_REL_ BCM1 SG_ 1517 SAD2_Rollo_Lage 5000;
BA_REL_ "GenSigTimeoutTime" BU_SG_REL_ BCM1 SG_ 1517 SAD2_Rollo_Position 5000;
BA_REL_ "GenSigTimeoutTime" BU_SG_REL_ BCM1 SG_ 1504 MD1_Position 5000;
BA_REL_ "GenSigTimeoutTime" BU_SG_REL_ BCM1 SG_ 1504 MD1_Lage 5000;
BA_REL_ "GenSigTimeoutTime" BU_SG_REL_ BCM1 SG_ 1504 MD3_Position 5000;
BA_REL_ "GenSigTimeoutTime" BU_SG_REL_ BCM1 SG_ 1504 MD3_Lage 5000;
BA_REL_ "GenSigTimeoutTime" BU_SG_REL_ BCM1 SG_ 1504 MRollo_Position 5000;
BA_REL_ "GenSigTimeoutTime" BU_SG_REL_ BCM1 SG_ 1504 MRollo_Lage 5000;
BA_REL_ "GenSigTimeoutTime" BU_SG_REL_ BCM1 SG_ 249 SARA_QBit_Nickwinkel 5000;
BA_REL_ "GenSigTimeoutTime" BU_SG_REL_ BCM1 SG_ 249 SARA_QBit_Wankwinkel 5000;
BA_REL_ "GenSigTimeoutTime" BU_SG_REL_ BCM1 SG_ 249 SARA_Nickwinkel 5000;
BA_REL_ "GenSigTimeoutTime" BU_SG_REL_ BCM1 SG_ 249 SARA_Wankwinkel 5000;
BA_REL_ "GenSigTimeoutTime" BU_SG_REL_ BCM1 SG_ 424 SARA_11_CRC 500;
BA_REL_ "GenSigTimeoutTime" BU_SG_REL_ BCM1 SG_ 424 SARA_11_BZ 500;
BA_REL_ "GenSigTimeoutTime" BU_SG_REL_ BCM1 SG_ 424 SARA_Accel_X_r 500;
BA_REL_ "GenSigTimeoutTime" BU_SG_REL_ BCM1 SG_ 424 SARA_Accel_Y_r 500;
BA_REL_ "GenSigTimeoutTime" BU_SG_REL_ BCM1 SG_ 424 SARA_Omega_Z_r 500;
BA_REL_ "GenSigTimeoutTime" BU_SG_REL_ BCM1 SG_ 424 SARA_CF_Accel_X_r 500;
BA_REL_ "GenSigTimeoutTime" BU_SG_REL_ BCM1 SG_ 424 SARA_CF_Accel_Y_r 500;
BA_REL_ "GenSigTimeoutTime" BU_SG_REL_ BCM1 SG_ 424 SARA_CF_Omega_Z_r 500;
BA_REL_ "GenSigTimeoutTime" BU_SG_REL_ BCM1 SG_ 1522 KBI_Phototransistor 2000;
BA_REL_ "GenSigTimeoutTime" BU_SG_REL_ BCM1 SG_ 1522 KBI_Dimmpoti 2000;
BA_REL_ "GenSigTimeoutTime" BU_SG_REL_ BCM1 SG_ 2527679651 SM_Parken_Hupe_Anf 2000;
BA_REL_ "GenSigTimeoutTime" BU_SG_REL_ BCM1 SG_ 2527679651 SM_Parken_UGDO_Anf 2000;
BA_REL_ "GenSigTimeoutTime" BU_SG_REL_ BCM1 SG_ 2527679651 SM_Parken_UGDO_Aktion 2000;
BA_REL_ "GenSigTimeoutTime" BU_SG_REL_ BCM1 SG_ 980 SMLS_01_CRC 2000;
BA_REL_ "GenSigTimeoutTime" BU_SG_REL_ BCM1 SG_ 980 SMLS_01_BZ 2000;
BA_REL_ "GenSigTimeoutTime" BU_SG_REL_ BCM1 SG_ 980 BH_Blinker_li 2000;
BA_REL_ "GenSigTimeoutTime" BU_SG_REL_ BCM1 SG_ 980 BH_Blinker_re 2000;
BA_REL_ "GenSigTimeoutTime" BU_SG_REL_ BCM1 SG_ 980 BH_Lichthupe 2000;
BA_REL_ "GenSigTimeoutTime" BU_SG_REL_ BCM1 SG_ 980 BH_Fernlicht 2000;
BA_REL_ "GenSigTimeoutTime" BU_SG_REL_ BCM1 SG_ 980 WH_Tipwischen 2000;
BA_REL_ "GenSigTimeoutTime" BU_SG_REL_ BCM1 SG_ 980 WH_Intervall 2000;
BA_REL_ "GenSigTimeoutTime" BU_SG_REL_ BCM1 SG_ 980 WH_WischerStufe1 2000;
BA_REL_ "GenSigTimeoutTime" BU_SG_REL_ BCM1 SG_ 980 WH_WischerStufe2 2000;
BA_REL_ "GenSigTimeoutTime" BU_SG_REL_ BCM1 SG_ 980 WH_Frontwaschen 2000;
BA_REL_ "GenSigTimeoutTime" BU_SG_REL_ BCM1 SG_ 980 WH_Heckintervall 2000;
BA_REL_ "GenSigTimeoutTime" BU_SG_REL_ BCM1 SG_ 980 WH_Heckwaschen 2000;
BA_REL_ "GenSigTimeoutTime" BU_SG_REL_ BCM1 SG_ 980 WH_Intervallstufen 2000;
BA_REL_ "GenSigTimeoutTime" BU_SG_REL_ BCM1 SG_ 980 SMLS_Hupe 2000;
BA_REL_ "GenSigTimeoutTime" BU_SG_REL_ BCM1 SG_ 980 LRH_On_Off 2000;
BA_REL_ "GenSigTimeoutTime" BU_SG_REL_ BCM1 SG_ 980 WH_SRA 2000;
BA_REL_ "GenSigTimeoutTime" BU_SG_REL_ BCM1 SG_ 980 WH_Wischer_Fehler 2000;
BA_REL_ "GenSigTimeoutTime" BU_SG_REL_ BCM1 SG_ 980 WH_Tipwischen_lang 2000;
BA_REL_ "GenSigTimeoutTime" BU_SG_REL_ BCM1 SG_ 1710 SP_S_oben 5000;
BA_REL_ "GenSigTimeoutTime" BU_SG_REL_ BCM1 SG_ 1710 SP_S_unten 5000;
BA_REL_ "GenSigTimeoutTime" BU_SG_REL_ BCM1 SG_ 1710 SP_S_links 5000;
BA_REL_ "GenSigTimeoutTime" BU_SG_REL_ BCM1 SG_ 1710 SP_S_rechts 5000;
BA_REL_ "GenSigTimeoutTime" BU_SG_REL_ BCM1 SG_ 1710 SP_Auswahl_li 5000;
BA_REL_ "GenSigTimeoutTime" BU_SG_REL_ BCM1 SG_ 1710 SP_Auswahl_re 5000;
BA_REL_ "GenSigTimeoutTime" BU_SG_REL_ BCM1 SG_ 1710 SP_ARA_Status 5000;
BA_REL_ "GenSigTimeoutTime" BU_SG_REL_ BCM1 SG_ 1710 SP_S_Klappen 5000;
BA_REL_ "GenSigTimeoutTime" BU_SG_REL_ BCM1 SG_ 1710 SP_Verstellschalter_Fehler 5000;
BA_REL_ "GenSigTimeoutTime" BU_SG_REL_ BCM1 SG_ 1313 STH_Funk_ein 2000;
BA_REL_ "GenSigTimeoutTime" BU_SG_REL_ BCM1 SG_ 1313 STH_Funk_aus 2000;
BA_REL_ "GenSigTimeoutTime" BU_SG_REL_ BCM1 SG_ 1313 STH_Zusatzheizung 2000;
BA_REL_ "GenSigTimeoutTime" BU_SG_REL_ BCM1 SG_ 1313 STH_LED 2000;
BA_REL_ "GenSigTimeoutTime" BU_SG_REL_ BCM1 SG_ 1313 STH_Pumpe_ein 2000;
BA_REL_ "GenSigTimeoutTime" BU_SG_REL_ BCM1 SG_ 1313 STH_Geblaese 2000;
BA_REL_ "GenSigTimeoutTime" BU_SG_REL_ BCM1 SG_ 1313 STH_EKP_Anst 2000;
BA_REL_ "GenSigTimeoutTime" BU_SG_REL_ BCM1 SG_ 1313 STH_Ventiloeffnungszeit 2000;
BA_REL_ "GenSigTimeoutTime" BU_SG_REL_ BCM1 SG_ 1313 STH_Ventil_Status 2000;
BA_REL_ "GenSigTimeoutTime" BU_SG_REL_ BCM1 SG_ 1313 STH_Fehler_ElWaPu 2000;
BA_REL_ "GenSigTimeoutTime" BU_SG_REL_ BCM1 SG_ 1313 STH_Waermeeintrag 2000;
BA_REL_ "GenSigTimeoutTime" BU_SG_REL_ BCM1 SG_ 1313 STH_KVS 2000;
BA_REL_ "GenSigTimeoutTime" BU_SG_REL_ BCM1 SG_ 1313 STH_Fehlerstatus 2000;
BA_REL_ "GenSigTimeoutTime" BU_SG_REL_ BCM1 SG_ 1313 STH_Heizleistung 2000;
BA_REL_ "GenSigTimeoutTime" BU_SG_REL_ BCM1 SG_ 1313 STH_Wassertemp 2000;
BA_REL_ "GenSigTimeoutTime" BU_SG_REL_ BCM1 SG_ 1313 STH_Texte 2000;
BA_REL_ "GenSigTimeoutTime" BU_SG_REL_ BCM1 SG_ 1313 STH_Motorvorwaermung 2000;
BA_REL_ "GenSigTimeoutTime" BU_SG_REL_ BCM1 SG_ 1313 STH_Servicemode 2000;
BA_REL_ "GenSigTimeoutTime" BU_SG_REL_ BCM1 SG_ 1313 STH_war_aktiv 2000;
BA_REL_ "GenSigTimeoutTime" BU_SG_REL_ BCM1 SG_ 1313 STH_KVS_Ueberlauf 2000;
BA_REL_ "GenSigTimeoutTime" BU_SG_REL_ BCM1 SG_ 1650 STH_ZZ_Monat 5000;
BA_REL_ "GenSigTimeoutTime" BU_SG_REL_ BCM1 SG_ 1650 STH_ZZ_Tag 5000;
BA_REL_ "GenSigTimeoutTime" BU_SG_REL_ BCM1 SG_ 1650 STH_ZZ_Betriebsmodus 5000;
BA_REL_ "GenSigTimeoutTime" BU_SG_REL_ BCM1 SG_ 1650 STH_ZZ_Minute 5000;
BA_REL_ "GenSigTimeoutTime" BU_SG_REL_ BCM1 SG_ 1650 STH_ZZ_Status_Timer 5000;
BA_REL_ "GenSigTimeoutTime" BU_SG_REL_ BCM1 SG_ 1650 STH_ZZ_Stunde 5000;
BA_REL_ "GenSigTimeoutTime" BU_SG_REL_ BCM1 SG_ 1650 STH_ZZ_Betriebsdauer 5000;
BA_REL_ "GenSigTimeoutTime" BU_SG_REL_ BCM1 SG_ 505 STP_Funktion_freigegeben 5000;
BA_REL_ "GenSigTimeoutTime" BU_SG_REL_ BCM1 SG_ 1172 STS_Standlicht 2000;
BA_REL_ "GenSigTimeoutTime" BU_SG_REL_ BCM1 SG_ 1172 STS_Fahrlicht 2000;
BA_REL_ "GenSigTimeoutTime" BU_SG_REL_ BCM1 SG_ 1172 STS_Signalhorn 2000;
BA_REL_ "GenSigTimeoutTime" BU_SG_REL_ BCM1 SG_ 783 SWA_FT_RueckLED 2000;
BA_REL_ "GenSigTimeoutTime" BU_SG_REL_ BCM1 SG_ 1413 SI_QRS_Mode 5000;
BA_REL_ "GenSigTimeoutTime" BU_SG_REL_ BCM1 SG_ 1413 SI_T_Mode 5000;
BA_REL_ "GenSigTimeoutTime" BU_SG_REL_ BCM1 SG_ 1413 SI_NWDF 5000;
BA_REL_ "GenSigTimeoutTime" BU_SG_REL_ BCM1 SG_ 1413 SI_NWDF_gueltig 5000;
BA_REL_ "GenSigTimeoutTime" BU_SG_REL_ BCM1 SG_ 1413 SI_T_Schutz 5000;
BA_REL_ "GenSigTimeoutTime" BU_SG_REL_ BCM1 SG_ 1413 SI_BUS_01 5000;
BA_REL_ "GenSigTimeoutTime" BU_SG_REL_ BCM1 SG_ 1413 SI_BUS_03 5000;
BA_REL_ "GenSigTimeoutTime" BU_SG_REL_ BCM1 SG_ 1413 SI_BUS_04 5000;
BA_REL_ "GenSigTimeoutTime" BU_SG_REL_ BCM1 SG_ 1413 SI_BUS_06 5000;
BA_REL_ "GenSigTimeoutTime" BU_SG_REL_ BCM1 SG_ 1413 SI_BUS_10 5000;
BA_REL_ "GenSigTimeoutTime" BU_SG_REL_ BCM1 SG_ 1413 SI_BUS_13 5000;
BA_REL_ "GenSigTimeoutTime" BU_SG_REL_ BCM1 SG_ 1017 TME_Ventil1_Status 2000;
BA_REL_ "GenSigTimeoutTime" BU_SG_REL_ BCM1 SG_ 1017 TME_Fehler_ElWaPu1 2000;
BA_REL_ "GenSigTimeoutTime" BU_SG_REL_ BCM1 SG_ 1017 TME_Pumpe1_Status 2000;
BA_REL_ "GenSigTimeoutTime" BU_SG_REL_ BCM1 SG_ 1375 TME_AC_LED 5000;
BA_REL_ "GenSigTimeoutTime" BU_SG_REL_ BCM1 SG_ 1375 TME_Heizstrategie 5000;
BA_REL_ "GenSigTimeoutTime" BU_SG_REL_ BCM1 SG_ 1375 TME_Systemstatus 5000;
BA_REL_ "GenSigTimeoutTime" BU_SG_REL_ BCM1 SG_ 1375 TME_Kbr_Innenraum 5000;
BA_REL_ "GenSigTimeoutTime" BU_SG_REL_ BCM1 SG_ 1375 TME_Freigabe_Vorkond 5000;
BA_REL_ "GenSigTimeoutTime" BU_SG_REL_ BCM1 SG_ 1375 TME_Verdampfer_Status 5000;
BA_REL_ "GenSigTimeoutTime" BU_SG_REL_ BCM1 SG_ 1375 TME_AC_Rueckmeldung 5000;
BA_REL_ "GenSigTimeoutTime" BU_SG_REL_ BCM1 SG_ 1375 TME_Frischluftklappe_Soll 5000;
BA_REL_ "GenSigTimeoutTime" BU_SG_REL_ BCM1 SG_ 1375 TME_Freigabe_Luft_PTC 5000;
BA_REL_ "GenSigTimeoutTime" BU_SG_REL_ BCM1 SG_ 1375 TME_Umluftklappe_Soll 5000;
BA_REL_ "GenSigTimeoutTime" BU_SG_REL_ BCM1 SG_ 1375 TME_Waermepumpe_aktiv 5000;
BA_REL_ "GenSigTimeoutTime" BU_SG_REL_ BCM1 SG_ 1375 TME_Klima_Defizit 5000;
BA_REL_ "GenSigTimeoutTime" BU_SG_REL_ BCM1 SG_ 1375 TME_Temp_KM_vor_HWT 5000;
BA_REL_ "GenSigTimeoutTime" BU_SG_REL_ BCM1 SG_ 1373 TME_Kond_Innen_Betrieb 5000;
BA_REL_ "GenSigTimeoutTime" BU_SG_REL_ BCM1 SG_ 1373 TME_Klimadefizit 5000;
BA_REL_ "GenSigTimeoutTime" BU_SG_REL_ BCM1 SG_ 1373 TME_Kond_Innen_Betriebsdauer 5000;
BA_REL_ "GenSigTimeoutTime" BU_SG_REL_ BCM1 SG_ 1373 TME_Kond_Innen_Status 5000;
BA_REL_ "GenSigTimeoutTime" BU_SG_REL_ BCM1 SG_ 1373 TME_STH_Ansteuerung 5000;
BA_REL_ "GenSigTimeoutTime" BU_SG_REL_ BCM1 SG_ 1373 TME_STH_aktiv 5000;
BA_REL_ "GenSigTimeoutTime" BU_SG_REL_ BCM1 SG_ 1373 TME_STL_aktiv 5000;
BA_REL_ "GenSigTimeoutTime" BU_SG_REL_ BCM1 SG_ 1657 TME_Klimaanforderung 5000;
BA_REL_ "GenSigTimeoutTime" BU_SG_REL_ BCM1 SG_ 1657 TME_Temperatur_Ruecklauf_VKM 5000;
BA_REL_ "GenSigTimeoutTime" BU_SG_REL_ BCM1 SG_ 977 BT_Tuer_geoeffnet 1000;
BA_REL_ "GenSigTimeoutTime" BU_SG_REL_ BCM1 SG_ 977 BT_TIG_betaetigt 1000;
BA_REL_ "GenSigTimeoutTime" BU_SG_REL_ BCM1 SG_ 977 BT_Sp_Blk_def 1000;
BA_REL_ "GenSigTimeoutTime" BU_SG_REL_ BCM1 SG_ 977 BT_FH_Oeffnung 1000;
BA_REL_ "GenSigTimeoutTime" BU_SG_REL_ BCM1 SG_ 977 BT_SP_Heizung_Status 1000;
BA_REL_ "GenSigTimeoutTime" BU_SG_REL_ BCM1 SG_ 977 ASW_Warnung_aktiv_BFS 1000;
BA_REL_ "GenSigTimeoutTime" BU_SG_REL_ BCM1 SG_ 1451 TSG_FlHz_BFS_NTC_A 5000;
BA_REL_ "GenSigTimeoutTime" BU_SG_REL_ BCM1 SG_ 1451 TSG_FlHz_BFS_FnAbbruchHzKreis_A 5000;
BA_REL_ "GenSigTimeoutTime" BU_SG_REL_ BCM1 SG_ 1451 TSG_FlHz_BFS_NTC_B 5000;
BA_REL_ "GenSigTimeoutTime" BU_SG_REL_ BCM1 SG_ 1451 TSG_FlHz_BFS_FnAbbruchHzKreis_B 5000;
BA_REL_ "GenSigTimeoutTime" BU_SG_REL_ Gateway SG_ 1440 LS_Helligkeit_IR 2000;
BA_REL_ "GenSigTimeoutTime" BU_SG_REL_ Gateway SG_ 1440 LS_Helligkeit_FW 2000;
BA_REL_ "GenSigTimeoutTime" BU_SG_REL_ Gateway SG_ 1440 RS_Regenmenge 2000;
BA_REL_ "GenSigTimeoutTime" BU_SG_REL_ Gateway SG_ 1440 RS_Wischergeschwindigkeit 2000;
BA_REL_ "GenSigTimeoutTime" BU_SG_REL_ Gateway_PAG SG_ 1440 LS_Helligkeit_IR 2000;
BA_REL_ "GenSigTimeoutTime" BU_SG_REL_ Gateway_PAG SG_ 1440 LS_Helligkeit_FW 2000;
BA_REL_ "GenSigTimeoutTime" BU_SG_REL_ Gateway_PAG SG_ 1440 RS_Regenmenge 2000;
BA_REL_ "GenSigTimeoutTime" BU_SG_REL_ Gateway_PAG SG_ 1440 RS_Wischergeschwindigkeit 2000;
BA_REL_ "GenSigTimeoutTime" BU_SG_REL_ Klima_MSB SG_ 1440 RS_Regenmenge 2000;
BA_REL_ "GenSigTimeoutTime" BU_SG_REL_ Klima_MSB SG_ 1517 SAD2_Rollo_Lage 5000;
BA_REL_ "GenSigTimeoutTime" BU_SG_REL_ Klima_MSB SG_ 1517 SAD2_Rollo_Position 5000;
BA_REL_ "GenSigTimeoutTime" BU_SG_REL_ Klima_MSB SG_ 1504 MD1_Position 5000;
BA_REL_ "GenSigTimeoutTime" BU_SG_REL_ Klima_MSB SG_ 1504 MD1_Lage 5000;
BA_REL_ "GenSigTimeoutTime" BU_SG_REL_ Klima_MSB SG_ 1504 MD3_Position 5000;
BA_REL_ "GenSigTimeoutTime" BU_SG_REL_ Klima_MSB SG_ 1504 MD3_Lage 5000;
BA_REL_ "GenSigTimeoutTime" BU_SG_REL_ Klima_MSB SG_ 1504 MRollo_Position 5000;
BA_REL_ "GenSigTimeoutTime" BU_SG_REL_ Klima_MSB SG_ 1504 MRollo_Lage 5000;
BA_REL_ "GenSigTimeoutTime" BU_SG_REL_ Klima_MSB SG_ 249 SARA_QBit_Nickwinkel 5000;
BA_REL_ "GenSigTimeoutTime" BU_SG_REL_ Klima_MSB SG_ 249 SARA_QBit_Wankwinkel 5000;
BA_REL_ "GenSigTimeoutTime" BU_SG_REL_ Klima_MSB SG_ 249 SARA_Nickwinkel 5000;
BA_REL_ "GenSigTimeoutTime" BU_SG_REL_ Klima_MSB SG_ 249 SARA_Wankwinkel 5000;
BA_REL_ "GenSigTimeoutTime" BU_SG_REL_ Klima_MSB SG_ 980 LRH_On_Off 2000;
BA_REL_ "GenSigTimeoutTime" BU_SG_REL_ Klima_MSB SG_ 1467 SoSe_SunInt_2D_Li 5000;
BA_REL_ "GenSigTimeoutTime" BU_SG_REL_ Klima_MSB SG_ 1467 SoSe_SunInt_2D_Re 5000;
BA_REL_ "GenSigTimeoutTime" BU_SG_REL_ Klima_MSB SG_ 1313 STH_Funk_ein 2000;
BA_REL_ "GenSigTimeoutTime" BU_SG_REL_ Klima_MSB SG_ 1313 STH_Funk_aus 2000;
BA_REL_ "GenSigTimeoutTime" BU_SG_REL_ Klima_MSB SG_ 1313 STH_Zusatzheizung 2000;
BA_REL_ "GenSigTimeoutTime" BU_SG_REL_ Klima_MSB SG_ 1313 STH_LED 2000;
BA_REL_ "GenSigTimeoutTime" BU_SG_REL_ Klima_MSB SG_ 1313 STH_Pumpe_ein 2000;
BA_REL_ "GenSigTimeoutTime" BU_SG_REL_ Klima_MSB SG_ 1313 STH_Geblaese 2000;
BA_REL_ "GenSigTimeoutTime" BU_SG_REL_ Klima_MSB SG_ 1313 STH_EKP_Anst 2000;
BA_REL_ "GenSigTimeoutTime" BU_SG_REL_ Klima_MSB SG_ 1313 STH_Ventiloeffnungszeit 2000;
BA_REL_ "GenSigTimeoutTime" BU_SG_REL_ Klima_MSB SG_ 1313 STH_Ventil_Status 2000;
BA_REL_ "GenSigTimeoutTime" BU_SG_REL_ Klima_MSB SG_ 1313 STH_Fehler_ElWaPu 2000;
BA_REL_ "GenSigTimeoutTime" BU_SG_REL_ Klima_MSB SG_ 1313 STH_Waermeeintrag 2000;
BA_REL_ "GenSigTimeoutTime" BU_SG_REL_ Klima_MSB SG_ 1313 STH_KVS 2000;
BA_REL_ "GenSigTimeoutTime" BU_SG_REL_ Klima_MSB SG_ 1313 STH_Fehlerstatus 2000;
BA_REL_ "GenSigTimeoutTime" BU_SG_REL_ Klima_MSB SG_ 1313 STH_Heizleistung 2000;
BA_REL_ "GenSigTimeoutTime" BU_SG_REL_ Klima_MSB SG_ 1313 STH_Wassertemp 2000;
BA_REL_ "GenSigTimeoutTime" BU_SG_REL_ Klima_MSB SG_ 1313 STH_Texte 2000;
BA_REL_ "GenSigTimeoutTime" BU_SG_REL_ Klima_MSB SG_ 1313 STH_Motorvorwaermung 2000;
BA_REL_ "GenSigTimeoutTime" BU_SG_REL_ Klima_MSB SG_ 1313 STH_Servicemode 2000;
BA_REL_ "GenSigTimeoutTime" BU_SG_REL_ Klima_MSB SG_ 1313 STH_war_aktiv 2000;
BA_REL_ "GenSigTimeoutTime" BU_SG_REL_ Klima_MSB SG_ 1313 STH_KVS_Ueberlauf 2000;
BA_REL_ "GenSigTimeoutTime" BU_SG_REL_ Klima_MSB SG_ 1650 STH_ZZ_Monat 5000;
BA_REL_ "GenSigTimeoutTime" BU_SG_REL_ Klima_MSB SG_ 1650 STH_ZZ_Tag 5000;
BA_REL_ "GenSigTimeoutTime" BU_SG_REL_ Klima_MSB SG_ 1650 STH_ZZ_Betriebsmodus 5000;
BA_REL_ "GenSigTimeoutTime" BU_SG_REL_ Klima_MSB SG_ 1650 STH_ZZ_Minute 5000;
BA_REL_ "GenSigTimeoutTime" BU_SG_REL_ Klima_MSB SG_ 1650 STH_ZZ_Status_Timer 5000;
BA_REL_ "GenSigTimeoutTime" BU_SG_REL_ Klima_MSB SG_ 1650 STH_ZZ_Stunde 5000;
BA_REL_ "GenSigTimeoutTime" BU_SG_REL_ Klima_MSB SG_ 1650 STH_ZZ_Betriebsdauer 5000;
BA_REL_ "GenSigTimeoutTime" BU_SG_REL_ Klima_MSB SG_ 1413 SI_QRS_Mode 5000;
BA_REL_ "GenSigTimeoutTime" BU_SG_REL_ Klima_MSB SG_ 1413 SI_T_Mode 5000;
BA_REL_ "GenSigTimeoutTime" BU_SG_REL_ Klima_MSB SG_ 1413 SI_NWDF 5000;
BA_REL_ "GenSigTimeoutTime" BU_SG_REL_ Klima_MSB SG_ 1413 SI_NWDF_gueltig 5000;
BA_REL_ "GenSigTimeoutTime" BU_SG_REL_ Klima_MSB SG_ 1015 TME_StartStopp_Info 1000;
BA_REL_ "GenSigTimeoutTime" BU_SG_REL_ Klima_MSB SG_ 1017 TME_Ventil1_Status 2000;
BA_REL_ "GenSigTimeoutTime" BU_SG_REL_ Klima_MSB SG_ 1017 TME_Fehler_ElWaPu1 2000;
BA_REL_ "GenSigTimeoutTime" BU_SG_REL_ Klima_MSB SG_ 1017 TME_MMTR_Status 2000;
BA_REL_ "GenSigTimeoutTime" BU_SG_REL_ Klima_MSB SG_ 1375 TME_AC_LED 5000;
BA_REL_ "GenSigTimeoutTime" BU_SG_REL_ Klima_MSB SG_ 1375 TME_Heizstrategie 5000;
BA_REL_ "GenSigTimeoutTime" BU_SG_REL_ Klima_MSB SG_ 1375 TME_Systemstatus 5000;
BA_REL_ "GenSigTimeoutTime" BU_SG_REL_ Klima_MSB SG_ 1375 TME_Kbr_Innenraum 5000;
BA_REL_ "GenSigTimeoutTime" BU_SG_REL_ Klima_MSB SG_ 1375 TME_Freigabe_Vorkond 5000;
BA_REL_ "GenSigTimeoutTime" BU_SG_REL_ Klima_MSB SG_ 1375 TME_Verdampfer_Status 5000;
BA_REL_ "GenSigTimeoutTime" BU_SG_REL_ Klima_MSB SG_ 1375 TME_AC_Rueckmeldung 5000;
BA_REL_ "GenSigTimeoutTime" BU_SG_REL_ Klima_MSB SG_ 1375 TME_Frischluftklappe_Soll 5000;
BA_REL_ "GenSigTimeoutTime" BU_SG_REL_ Klima_MSB SG_ 1375 TME_Freigabe_Luft_PTC 5000;
BA_REL_ "GenSigTimeoutTime" BU_SG_REL_ Klima_MSB SG_ 1375 TME_Umluftklappe_Soll 5000;
BA_REL_ "GenSigTimeoutTime" BU_SG_REL_ Klima_MSB SG_ 1375 TME_Waermepumpe_aktiv 5000;
BA_REL_ "GenSigTimeoutTime" BU_SG_REL_ Klima_MSB SG_ 1375 TME_Klima_Defizit 5000;
BA_REL_ "GenSigTimeoutTime" BU_SG_REL_ Klima_MSB SG_ 1375 TME_Temp_KM_vor_HWT 5000;
BA_REL_ "GenSigTimeoutTime" BU_SG_REL_ Klima_MSB SG_ 1373 TME_Klimadefizit 5000;
BA_REL_ "GenSigTimeoutTime" BU_SG_REL_ Klima_MSB SG_ 1373 TME_Kond_Innen_Betriebsdauer 5000;
BA_REL_ "GenSigTimeoutTime" BU_SG_REL_ Klima_MSB SG_ 1657 TME_TCP_Kond_active 5000;
BA_REL_ "GenSigTimeoutTime" BU_SG_REL_ Klima_MSB SG_ 1657 TME_Temperatur_Ruecklauf_VKM 5000;
BA_REL_ "GenSigTimeoutTime" BU_SG_REL_ Klima_MSB SG_ 977 BT_Tuer_geoeffnet 1000;
BA_REL_ "GenSigTimeoutTime" BU_SG_REL_ Klima_MSB SG_ 977 BT_FH_Oeffnung 1000;
BA_REL_ "GenSigTimeoutTime" BU_SG_REL_ Klima_MSB SG_ 1451 TSG_FlHz_BFS_NTC_A 5000;
BA_REL_ "GenSigTimeoutTime" BU_SG_REL_ Klima_MSB SG_ 1451 TSG_FlHz_BFS_FnAbbruchHzKreis_A 5000;
BA_REL_ "GenSigTimeoutTime" BU_SG_REL_ Lift_VA SG_ 424 SARA_Accel_X_r 500;
BA_REL_ "GenSigTimeoutTime" BU_SG_REL_ Lift_VA SG_ 424 SARA_Accel_Y_r 500;
BA_REL_ "GenSigTimeoutTime" BU_SG_REL_ Lift_VA SG_ 1413 SI_T_Mode 5000;
BA_REL_ "GenSigTimeoutTime" BU_SG_REL_ Lift_VA SG_ 1413 SI_NWDF 5000;
BA_REL_ "GenSigTimeoutTime" BU_SG_REL_ Lift_VA SG_ 1413 SI_NWDF_gueltig 5000;
BA_REL_ "GenSigTimeoutTime" BU_SG_REL_ Lift_VA SG_ 1413 SI_T_Schutz 5000;
BA_REL_ "GenSigTimeoutTime" BU_SG_REL_ Lift_VA SG_ 977 BT_Tuer_geoeffnet 1000;
BA_REL_ "GenSigTimeoutTime" BU_SG_REL_ VAS_L SG_ 1440 LS_Helligkeit_IR 2000;
BA_REL_ "GenSigTimeoutTime" BU_SG_REL_ VAS_L SG_ 1440 LS_Helligkeit_FW 2000;
BA_REL_ "GenSigTimeoutTime" BU_SG_REL_ VAS_L SG_ 1440 LS_defekt 2000;
BA_REL_ "GenSigTimeoutTime" BU_SG_REL_ VAS_L SG_ 1440 LS_Verbau 2000;
BA_REL_ "GenSigTimeoutTime" BU_SG_REL_ VAS_L SG_ 1440 RS_Verbau 2000;
BA_REL_ "GenSigTimeoutTime" BU_SG_REL_ VAS_L SG_ 1440 RS_defekt 2000;
BA_REL_ "GenSigTimeoutTime" BU_SG_REL_ VAS_L SG_ 1440 RS_Wischergeschwindigkeit 2000;
BA_REL_ "GenSigTimeoutTime" BU_SG_REL_ VAS_L SG_ 424 SARA_Accel_X_r 500;
BA_REL_ "GenSigTimeoutTime" BU_SG_REL_ VAS_L SG_ 424 SARA_Accel_Y_r 500;
BA_REL_ "GenSigTimeoutTime" BU_SG_REL_ VAS_L SG_ 424 SARA_Omega_Z_r 500;
BA_REL_ "GenSigTimeoutTime" BU_SG_REL_ VAS_L SG_ 424 SARA_CF_Accel_X_r 500;
BA_REL_ "GenSigTimeoutTime" BU_SG_REL_ VAS_L SG_ 424 SARA_CF_Accel_Y_r 500;
BA_REL_ "GenSigTimeoutTime" BU_SG_REL_ VAS_L SG_ 424 SARA_CF_Omega_Z_r 500;
BA_REL_ "GenSigTimeoutTime" BU_SG_REL_ VAS_L SG_ 980 WH_Tipwischen 2000;
BA_REL_ "GenSigTimeoutTime" BU_SG_REL_ VAS_L SG_ 1710 SP_Hzg_Taster 5000;
BA_REL_ "GenSigTimeoutTime" BU_SG_REL_ VAS_L SG_ 1710 SP_S_oben 5000;
BA_REL_ "GenSigTimeoutTime" BU_SG_REL_ VAS_L SG_ 1710 SP_S_unten 5000;
BA_REL_ "GenSigTimeoutTime" BU_SG_REL_ VAS_L SG_ 1710 SP_S_links 5000;
BA_REL_ "GenSigTimeoutTime" BU_SG_REL_ VAS_L SG_ 1710 SP_S_rechts 5000;
BA_REL_ "GenSigTimeoutTime" BU_SG_REL_ VAS_L SG_ 1710 SP_Auswahl_li 5000;
BA_REL_ "GenSigTimeoutTime" BU_SG_REL_ VAS_L SG_ 1710 SP_Auswahl_re 5000;
BA_REL_ "GenSigTimeoutTime" BU_SG_REL_ VAS_L SG_ 1710 SP_S_Klappen 5000;
BA_REL_ "GenSigTimeoutTime" BU_SG_REL_ VAS_L SG_ 1710 SP_Verstellschalter_Fehler 5000;
BA_REL_ "GenSigTimeoutTime" BU_SG_REL_ VAS_L SG_ 783 ASW_Status 2000;
BA_REL_ "GenSigTimeoutTime" BU_SG_REL_ VAS_L SG_ 783 SWA_Infostufe_SWA_li 2000;
BA_REL_ "GenSigTimeoutTime" BU_SG_REL_ VAS_L SG_ 783 SWA_Warnung_SWA_li 2000;
BA_REL_ "GenSigTimeoutTime" BU_SG_REL_ VAS_L SG_ 783 ASW_Warnung_FS 2000;
BA_REL_ "GenSigTimeoutTime" BU_SG_REL_ VAS_L SG_ 783 ASW_Warnung_BFS 2000;
BA_REL_ "GenSigTimeoutTime" BU_SG_REL_ VAS_L SG_ 783 ASW_Modus 2000;
BA_REL_ "GenSigTimeoutTime" BU_SG_REL_ VAS_L SG_ 783 SWA_Modus 2000;
BA_REL_ "GenSigTimeoutTime" BU_SG_REL_ VAS_L SG_ 783 SWA_Infostufe_SWA_re 2000;
BA_REL_ "GenSigTimeoutTime" BU_SG_REL_ VAS_L SG_ 783 SWA_Warnung_SWA_re 2000;
BA_REL_ "GenSigTimeoutTime" BU_SG_REL_ VAS_L SG_ 783 SWA_Status_02 2000;
BA_REL_ "GenSigTimeoutTime" BU_SG_REL_ VAS_L SG_ 673 SWA_LED_Hell_BFS 2000;
BA_REL_ "GenSigTimeoutTime" BU_SG_REL_ VAS_L SG_ 673 SWA_LED_Hell_FS 2000;
BA_REL_ "GenSigTimeoutTime" BU_SG_REL_ VAS_L SG_ 673 SWA_LED_Modus_BFS 2000;
BA_REL_ "GenSigTimeoutTime" BU_SG_REL_ VAS_L SG_ 673 SWA_LED_Modus_FS 2000;
BA_REL_ "GenSigTimeoutTime" BU_SG_REL_ VAS_L SG_ 1413 SI_QRS_Mode 5000;
BA_REL_ "GenSigTimeoutTime" BU_SG_REL_ VAS_L SG_ 1413 SI_T_Mode 5000;
BA_REL_ "GenSigTimeoutTime" BU_SG_REL_ VAS_L SG_ 1413 SI_NWDF 5000;
BA_REL_ "GenSigTimeoutTime" BU_SG_REL_ VAS_L SG_ 1413 SI_NWDF_gueltig 5000;
BA_REL_ "GenSigTimeoutTime" BU_SG_REL_ VAS_L SG_ 977 BT_Tuer_geoeffnet 1000;
BA_REL_ "GenSigTimeoutTime" BU_SG_REL_ VAS_L SG_ 977 BT_verriegelt 1000;
BA_REL_ "GenSigTimeoutTime" BU_SG_REL_ VAS_L SG_ 977 BT_TAG_betaetigt 1000;
BA_REL_ "GenSigTimeoutTime" BU_SG_REL_ VAS_L SG_ 977 BT_TIG_betaetigt 1000;
BA_REL_ "GenSigTimeoutTime" BU_SG_REL_ VAS_R SG_ 1440 LS_Helligkeit_IR 2000;
BA_REL_ "GenSigTimeoutTime" BU_SG_REL_ VAS_R SG_ 1440 LS_Helligkeit_FW 2000;
BA_REL_ "GenSigTimeoutTime" BU_SG_REL_ VAS_R SG_ 1440 LS_defekt 2000;
BA_REL_ "GenSigTimeoutTime" BU_SG_REL_ VAS_R SG_ 1440 LS_Verbau 2000;
BA_REL_ "GenSigTimeoutTime" BU_SG_REL_ VAS_R SG_ 1440 RS_Verbau 2000;
BA_REL_ "GenSigTimeoutTime" BU_SG_REL_ VAS_R SG_ 1440 RS_defekt 2000;
BA_REL_ "GenSigTimeoutTime" BU_SG_REL_ VAS_R SG_ 1440 RS_Wischergeschwindigkeit 2000;
BA_REL_ "GenSigTimeoutTime" BU_SG_REL_ VAS_R SG_ 424 SARA_Accel_X_r 500;
BA_REL_ "GenSigTimeoutTime" BU_SG_REL_ VAS_R SG_ 424 SARA_Accel_Y_r 500;
BA_REL_ "GenSigTimeoutTime" BU_SG_REL_ VAS_R SG_ 424 SARA_Omega_Z_r 500;
BA_REL_ "GenSigTimeoutTime" BU_SG_REL_ VAS_R SG_ 424 SARA_CF_Accel_X_r 500;
BA_REL_ "GenSigTimeoutTime" BU_SG_REL_ VAS_R SG_ 424 SARA_CF_Accel_Y_r 500;
BA_REL_ "GenSigTimeoutTime" BU_SG_REL_ VAS_R SG_ 424 SARA_CF_Omega_Z_r 500;
BA_REL_ "GenSigTimeoutTime" BU_SG_REL_ VAS_R SG_ 980 WH_Tipwischen 2000;
BA_REL_ "GenSigTimeoutTime" BU_SG_REL_ VAS_R SG_ 1710 SP_Hzg_Taster 5000;
BA_REL_ "GenSigTimeoutTime" BU_SG_REL_ VAS_R SG_ 1710 SP_S_oben 5000;
BA_REL_ "GenSigTimeoutTime" BU_SG_REL_ VAS_R SG_ 1710 SP_S_unten 5000;
BA_REL_ "GenSigTimeoutTime" BU_SG_REL_ VAS_R SG_ 1710 SP_S_links 5000;
BA_REL_ "GenSigTimeoutTime" BU_SG_REL_ VAS_R SG_ 1710 SP_S_rechts 5000;
BA_REL_ "GenSigTimeoutTime" BU_SG_REL_ VAS_R SG_ 1710 SP_Auswahl_li 5000;
BA_REL_ "GenSigTimeoutTime" BU_SG_REL_ VAS_R SG_ 1710 SP_Auswahl_re 5000;
BA_REL_ "GenSigTimeoutTime" BU_SG_REL_ VAS_R SG_ 1710 SP_S_Klappen 5000;
BA_REL_ "GenSigTimeoutTime" BU_SG_REL_ VAS_R SG_ 1710 SP_Verstellschalter_Fehler 5000;
BA_REL_ "GenSigTimeoutTime" BU_SG_REL_ VAS_R SG_ 783 ASW_Status 2000;
BA_REL_ "GenSigTimeoutTime" BU_SG_REL_ VAS_R SG_ 783 SWA_Infostufe_SWA_li 2000;
BA_REL_ "GenSigTimeoutTime" BU_SG_REL_ VAS_R SG_ 783 SWA_Warnung_SWA_li 2000;
BA_REL_ "GenSigTimeoutTime" BU_SG_REL_ VAS_R SG_ 783 ASW_Warnung_FS 2000;
BA_REL_ "GenSigTimeoutTime" BU_SG_REL_ VAS_R SG_ 783 ASW_Warnung_BFS 2000;
BA_REL_ "GenSigTimeoutTime" BU_SG_REL_ VAS_R SG_ 783 ASW_Modus 2000;
BA_REL_ "GenSigTimeoutTime" BU_SG_REL_ VAS_R SG_ 783 SWA_Modus 2000;
BA_REL_ "GenSigTimeoutTime" BU_SG_REL_ VAS_R SG_ 783 SWA_Infostufe_SWA_re 2000;
BA_REL_ "GenSigTimeoutTime" BU_SG_REL_ VAS_R SG_ 783 SWA_Warnung_SWA_re 2000;
BA_REL_ "GenSigTimeoutTime" BU_SG_REL_ VAS_R SG_ 783 SWA_Status_02 2000;
BA_REL_ "GenSigTimeoutTime" BU_SG_REL_ VAS_R SG_ 673 SWA_LED_Hell_BFS 2000;
BA_REL_ "GenSigTimeoutTime" BU_SG_REL_ VAS_R SG_ 673 SWA_LED_Hell_FS 2000;
BA_REL_ "GenSigTimeoutTime" BU_SG_REL_ VAS_R SG_ 673 SWA_LED_Modus_BFS 2000;
BA_REL_ "GenSigTimeoutTime" BU_SG_REL_ VAS_R SG_ 673 SWA_LED_Modus_FS 2000;
BA_REL_ "GenSigTimeoutTime" BU_SG_REL_ VAS_R SG_ 1413 SI_QRS_Mode 5000;
BA_REL_ "GenSigTimeoutTime" BU_SG_REL_ VAS_R SG_ 1413 SI_T_Mode 5000;
BA_REL_ "GenSigTimeoutTime" BU_SG_REL_ VAS_R SG_ 1413 SI_NWDF 5000;
BA_REL_ "GenSigTimeoutTime" BU_SG_REL_ VAS_R SG_ 1413 SI_NWDF_gueltig 5000;
BA_REL_ "GenSigTimeoutTime" BU_SG_REL_ VAS_R SG_ 977 BT_Tuer_geoeffnet 1000;
BA_REL_ "GenSigTimeoutTime" BU_SG_REL_ VAS_R SG_ 977 BT_verriegelt 1000;
BA_REL_ "GenSigTimeoutTime" BU_SG_REL_ VAS_R SG_ 977 BT_TAG_betaetigt 1000;
BA_REL_ "GenSigTimeoutTime" BU_SG_REL_ VAS_R SG_ 977 BT_TIG_betaetigt 1000;
VAL_ 1440 LS_Helligkeit_IR 254 "Init" 255 "Fehler" ;
VAL_ 1440 LS_Helligkeit_FW 1022 "Init" 1023 "Fehler" ;
VAL_ 1440 LS_defekt 0 "OK" 1 "defekt" ;
VAL_ 1440 LS_Verbau 0 "Init" 1 "Lichtsensor_verbaut" ;
VAL_ 1440 RS_Regenmenge 0 "0" 1 "0,0_bis_0,3" 2 "0,31_bis_1,4" 3 "1,41_bis_2,0" 4 "2,01_bis_2,8" 5 "2,81_bis_3,3" 6 "3,31_bis_4,0" 7 "4,01_bis_5,0" 8 "5,01_bis_7,0" 9 "7,01_bis_9,0" 10 "9,01_bis_11,0" 11 "11,01_bis_15,0" 12 "15,01_bis_22,0" 13 ">22,01" 14 "Init" 15 "Fehler" ;
VAL_ 1440 RS_Verbau 0 "Init" 1 "Regensensor verbaut" ;
VAL_ 1440 RS_Verglasung_schliessen 0 "Verglasung nicht schliessen" 1 "Verglasung schliessen" ;
VAL_ 1440 RS_defekt 0 "OK" 1 "defekt" ;
VAL_ 1440 RS_Wischergeschwindigkeit 0 "kein Wischen" 1 "42 Huebe/min" 2 "45 Huebe/min" 3 "48 Huebe/min" 4 "51 Huebe/min" 5 "54 Huebe/min" 6 "57 Huebe/min" 7 "60 Huebe/min" ;
VAL_ 1440 RLS_Vorfeldhelligkeit_Boost 0 "groesser_24413_Lux" 1 "bis_24413_Lux" 2 "bis_22193_Lux" 3 "bis_20176_Lux" 4 "bis_18342_Lux" 5 "bis_16647_Lux" 6 "bis_15158_Lux" 7 "bis_13780_Lux" 8 "bis_12527_Lux" 9 "bis_11388_Lux" 10 "bis_10353_Lux" 11 "bis_9412_Lux" 12 "bis_8556_Lux" 13 "bis_7778_Lux" 14 "bis_7071_Lux" 15 "bis_6428_Lux" ;
VAL_ 1517 SAD2_Deckel_Lage 0 "Austelllage" 1 "Schiebelage" ;
VAL_ 1517 SAD2_Deckel_normiert 0 "inaktiv" 1 "aktiv" ;
VAL_ 1517 SAD2_Deckel_Thermoschutz 0 "inaktiv" 1 "aktiv" ;
VAL_ 1517 SAD2_Deckel_UEKB_aktiv 0 "inaktiv" 1 "aktiv" ;
VAL_ 1517 SAD2_Deckel_Position 126 "Init" 127 "nicht_normiert" ;
VAL_ 1517 SAD2_Rollo_Lage 0 "Austelllage" 1 "Schiebelage" ;
VAL_ 1517 SAD2_Rollo_Position 126 "Init" 127 "nicht_normiert" ;
VAL_ 1517 SAD2_Rollo_normiert 0 "inaktiv" 1 "aktiv" ;
VAL_ 1517 SAD2_Rollo_Thermoschutz 0 "inaktiv" 1 "aktiv" ;
VAL_ 1517 SAD2_Rollo_UEKB_aktiv 0 "inaktiv" 1 "aktiv" ;
VAL_ 1504 MD1_Position 126 "Init" 127 "nicht_normiert" ;
VAL_ 1504 MD1_Lage 0 "Ausstelllage" 1 "Schiebelage" ;
VAL_ 1504 MD3_Lage 0 "Ausstelllage" 1 "Schiebelage" ;
VAL_ 1504 MRollo_Position 126 "Init" 127 "nicht_normiert" ;
VAL_ 1504 MRollo_Lage 0 "Ausstelllage" 1 "Schiebelage" ;
VAL_ 1504 SAD_normiert 0 "inaktiv" 1 "aktiv" ;
VAL_ 1504 SAD_Thermoschutz 0 "inaktiv" 1 "aktiv" ;
VAL_ 1504 SAD_UEKB_aktiv 0 "inaktiv" 1 "aktiv" ;
VAL_ 1504 Rollo_normiert 0 "inaktiv" 1 "aktiv" ;
VAL_ 1504 Rollo_Thermoschutz 0 "inaktiv" 1 "aktiv" ;
VAL_ 1504 Rollo_UEKB_aktiv 0 "inaktiv" 1 "aktiv" ;
VAL_ 1504 SAD_Taster_Deckel_hi 0 "nicht_betaetigt" 1 "man_sl_zu" 2 "auto_sl_zu" 3 "man_sl_auf" 4 "auto_sl_auf" 5 "man_al_auf" 6 "auto_al_auf" 7 "man_al_zu" 8 "auto_al_zu" 14 "fehler_schalter_haengt" 15 "fehler_schalter_unplausibel" ;
VAL_ 1504 SAD_Taster_Deckel_vo 0 "nicht_betaetigt" 1 "man_sl_zu" 2 "auto_sl_zu" 3 "man_sl_auf" 4 "auto_sl_auf" 5 "man_al_auf" 6 "auto_al_auf" 7 "man_al_zu" 8 "auto_al_zu" 14 "fehler_schalter_haengt" 15 "fehler_schalter_unplausibel" ;
VAL_ 1504 SAD_Taster_Rollo_hi 0 "nicht_betaetigt" 1 "man_zu" 2 "auto_zu" 3 "man_auf" 4 "auto_auf" 6 "fehler_schalter_haengt" 7 "fehler_schalter_unplausibel" ;
VAL_ 1504 SAD_Taster_Rollo_vo 0 "nicht_betaetigt" 1 "man_zu" 2 "auto_zu" 3 "man_auf" 4 "auto_auf" 6 "fehler_schalter_haengt" 7 "fehler_schalter_unplausibel" ;
VAL_ 1504 SAD_Anf_ESC_Zuschaltung 0 "inaktiv" 1 "aktiv" ;
VAL_ 1504 SAD_Text 0 "inaktiv" 1 "aktiv" ;
VAL_ 249 SARA_QBit_Nickwinkel 0 "gueltiger_Wert" 1 "Ersatz_Init_oder_Fehlerwert" ;
VAL_ 249 SARA_QBit_Wankwinkel 0 "gueltiger_Wert" 1 "Ersatz_Init_oder_Fehlerwert" ;
VAL_ 249 SARA_Nickwinkel 8191 "Init" ;
VAL_ 249 SARA_Wankwinkel 8191 "Init" ;
VAL_ 424 SARA_Accel_X_r 0 "nicht_verbaut" 8191 "Fehler" ;
VAL_ 424 SARA_Accel_Y_r 0 "nicht_verbaut" 8191 "Fehler" ;
VAL_ 424 SARA_Omega_Z_r 0 "nicht_verbaut" 8191 "Fehler" ;
VAL_ 424 SARA_CF_Accel_X_r 0 "gueltiger_Wert" 1 "nicht_belegt" 2 "nicht_belegt" 3 "temporaerer_Fehler" 4 "Init" 5 "Sensor_nicht_verbaut_Signal_nicht_berrechnet" 6 "Sensor_nicht_abgeglichen" 7 "Sensor_defekt" ;
VAL_ 424 SARA_CF_Accel_Y_r 0 "gueltiger_Wert" 1 "nicht_belegt" 2 "nicht_belegt" 3 "temporaerer_Fehler" 4 "Init" 5 "Sensor_nicht_verbaut_Signal_nicht_berrechnet" 6 "Sensor_nicht_abgeglichen" 7 "Sensor_defekt" ;
VAL_ 424 SARA_CF_Omega_Z_r 0 "gueltiger_Wert" 1 "nicht_belegt" 2 "nicht_belegt" 3 "temporaerer_Fehler" 4 "Init" 5 "Sensor_nicht_verbaut_Signal_nicht_berrechnet" 6 "Sensor_nicht_abgeglichen" 7 "Sensor_defekt" ;
VAL_ 1522 KBI_Phototransistor 254 "Init" 255 "Fehler" ;
VAL_ 1522 KBI_Dimmpoti 126 "Nicht verfügbar" 127 "Fehler" ;
VAL_ 2527679651 SM_Parken_blinken 0 "aus" 1 "links" 2 "rechts" 3 "warnblinken" ;
VAL_ 2527679651 SM_Parken_Hupe_Anf 0 "Keine_Anforderung" 1 "Hupen" ;
VAL_ 2527679651 SM_Parken_UGDO_Anf 0 "Keine_Anforderung" 1 "Garage_1" 2 "Garage_2" 3 "Garage_3" 4 "Garage_4" 5 "Garage_5" 6 "Garage_6" 7 "Garage_7" 8 "Garage_8" 9 "Garage_9" 10 "Garage_10" 11 "Garage_11" 12 "Garage_12" 13 "Garage_13" 14 "Garage_14" 15 "Garage_15" ;
VAL_ 2527679651 SM_Parken_UGDO_Aktion 0 "Keine_Anforderung" 1 "Garage_oeffnen_oder_toggeln" 2 "Garage_schliessen" 3 "Garage_stoppen" 4 "Status_Anfrage" ;
VAL_ 2527679651 SM_Parken_Komfortschliessen_Anf 0 "Keine_Anforderung" 1 "Komfortschliessen" ;
VAL_ 980 BH_Blinker_li 0 "nicht_betaetigt" 1 "Blinkerhebel_Pos_li_betaetigt" ;
VAL_ 980 BH_Blinker_re 0 "nicht_betaetigt" 1 "Blinkerhebel_Pos_re_betaetigt" ;
VAL_ 980 BH_Lichthupe 0 "nicht_betaetigt" 1 "Blinkerhebel in Richtung Lichthupe betaetigt" ;
VAL_ 980 BH_Fernlicht 0 "nicht_betaetigt" 1 "Blinkerhebel_in_Richtung_Fernlicht_betaetigt" ;
VAL_ 980 WH_Tipwischen 0 "nicht_betaetigt" 1 "betaetigt" ;
VAL_ 980 WH_Intervall 0 "aus" 1 "Wischerhebel in Stellung Intervall" ;
VAL_ 980 WH_WischerStufe1 0 "aus" 1 "Wischerhebel in Stufe Wischen 1" ;
VAL_ 980 WH_WischerStufe2 0 "aus" 1 "Wischerhebel in Stufe Wischen 2" ;
VAL_ 980 WH_Frontwaschen 0 "aus" 1 "Wischerhebel in Stellung Wisch Wasch vorne" ;
VAL_ 980 WH_Heckintervall 0 "nicht_betaetigt" 1 "Wischerhebel in Stellung Heckintervall" ;
VAL_ 980 WH_Heckwaschen 0 "nicht_betaetigt" 1 "Wischerhebel in Stellung Wisch Wasch hinten" ;
VAL_ 980 WH_Intervallstufen 0 "Init / Default" 1 "Intervallstufe 1" 5 "Intervallstufe 2" 9 "Intervallstufe 3" 13 "Intervallstufe 4" 15 "Fehler" ;
VAL_ 980 FAS_Taster 0 "nicht_betaetigt" 1 "betaetigt" ;
VAL_ 980 FAS_Taster_Fehler 0 "kein_Fehler" 1 "Fehler" ;
VAL_ 980 SMLS_Hupe 0 "nicht_betaetigt" 1 "Hupe_gedrueckt" ;
VAL_ 980 LRH_On_Off 0 "LRH_aus__keine Anzeige" 1 "LRH_aus" 2 "LRH_ein" 3 "Fehler" ;
VAL_ 980 LRH_aktiv 0 "inaktiv" 1 "aktiv" ;
VAL_ 980 SMLS_P_verriegelt_plausibel 0 "unplausibel" 1 "plausibel" ;
VAL_ 980 WH_SRA 0 "SRA_Aus" 1 "SRA_Ein" ;
VAL_ 980 WH_Wischer_Fehler 0 "kein_Fehler" 1 "Fehler" ;
VAL_ 980 BH_Blinker_Fehler 0 "kein_Fehler" 1 "Fehler" ;
VAL_ 980 SMLS_PTT 0 "nicht_betaetigt" 1 "PTT_gedrueckt" ;
VAL_ 980 WH_Tipwischen_lang 0 "nicht_betaetigt" 1 "betaetigt" ;
VAL_ 1467 SoSe_SunInt_2D_Li 254 "Init" 255 "Fehler" ;
VAL_ 1467 SoSe_SunInt_2D_Re 254 "Init" 255 "Fehler" ;
VAL_ 1710 SP_FT_oben 0 "nicht_betaetigt" 1 "betaetigt" ;
VAL_ 1710 SP_FT_unten 0 "nicht_betaetigt" 1 "betaetigt" ;
VAL_ 1710 SP_FT_links 0 "nicht_betaetigt" 1 "betaetigt" ;
VAL_ 1710 SP_FT_rechts 0 "nicht_betaetigt" 1 "betaetigt" ;
VAL_ 1710 SP_BT_oben 0 "nicht_betaetigt" 1 "betaetigt" ;
VAL_ 1710 SP_BT_unten 0 "nicht_betaetigt" 1 "betaetigt" ;
VAL_ 1710 SP_BT_links 0 "nicht_betaetigt" 1 "betaetigt" ;
VAL_ 1710 SP_BT_rechts 0 "nicht_betaetigt" 1 "betaetigt" ;
VAL_ 1710 SP_abklappen 0 "Spiegel_abklappen_nicht_aktiv" 1 "Spiegel_abklappen_aktiv" ;
VAL_ 1710 SP_anklappen 0 "Spiegle_anklappen_nicht_aktiv" 1 "Spiegel_anklappen_aktiv" ;
VAL_ 1710 SP_normieren 0 "Spiegel_nicht_normiert" 1 "Spiegel_normiert" ;
VAL_ 1710 SP_Hzg_Taster 0 "nicht_betaetigt" 1 "betaetigt" ;
VAL_ 1710 SP_S_oben 1 "Spiegelschalter in Stellung oben" ;
VAL_ 1710 SP_S_unten 1 "Spiegelschalter in Stellung unten" ;
VAL_ 1710 SP_S_links 1 "Spiegelschalter in Stellung links" ;
VAL_ 1710 SP_S_rechts 1 "Spiegelschalter in Stellung rechts" ;
VAL_ 1710 SP_Auswahl_li 1 "Spiegelschalter in Stellung Auswahl links" ;
VAL_ 1710 SP_Auswahl_re 1 "Spiegelschalter in Stellung Auswahl rechts" ;
VAL_ 1710 SP_ARA_Status 0 "TSG nicht im ARA-Modus" 1 "TSG im ARA-Modus" ;
VAL_ 1710 SP_S_Klappen 1 "Spiegelschalter in Stellung Klappen" ;
VAL_ 1710 SP_Verstellschalter_Fehler 0 "kein_Fehler" 1 "Fehler" ;
VAL_ 1313 STH_Funk_ein 0 "kein Funkbefehl zum Einschalten" 1 "Funkbefehl zum Einschalten erhalten" ;
VAL_ 1313 STH_Funk_aus 0 "kein Funkbefehl" 1 "Funkbefehl zum Ausschalten erhalten" ;
VAL_ 1313 STH_Zusatzheizung 0 "Zuheizer aus" 1 "Zuheizer ein" ;
VAL_ 1313 STH_LED 0 "keine Rückmeldung" 1 "Rueckmeldung Standheizung in Betrieb" ;
VAL_ 1313 STH_Geblaese 0 "kein Einschaltbefehl an die Klimaanlage, Gebläse" 1 "Einschaltbefehl an die Klimaanlage, Gebläse" ;
VAL_ 1313 STH_EKP_Anst 0 "EKP nicht ansteuern" 1 "EKP ansteuern" ;
VAL_ 1313 STH_Start_folgt 0 "kein_Start_folgt" 1 "Start_folgt" ;
VAL_ 1313 STH_Ventil_Status 0 "Ventil_offen__grosser_Kreislauf" 1 "Ventil_geschlossen__kleiner_Kreislauf" ;
VAL_ 1313 STH_Fehler_ElWaPu 0 "kein_Fehler" 1 "Fehler" ;
VAL_ 1313 STH_Pumpen_Anf_extern 0 "nicht_angefordert" 1 "angefordert" ;
VAL_ 1313 STH_KL_HUP 0 "Aus" 1 "Ein" ;
VAL_ 1313 STH_Fehlerstatus 0 "kein_Fehler" 1 "Unterspannung" 2 "Tankfuellstand_zu_gering" 3 "Fehler_Betrieb_verhindert" 4 "Heizgeraet_verriegelt" 5 "Fehler_Betrieb_nicht_verhindert" 6 "Emissionsüberschreitung" ;
VAL_ 1313 STH_Wassertemp 254 "Init" 255 "Fehler" ;
VAL_ 1313 STH_Texte 0 "keine_Anzeige" 1 "Batteriemanagementeinschraenkung" 2 "Kraftstoffmangel" 3 "interner_Systemfehler" 4 "Heizzeitueberschreitung" ;
VAL_ 1313 STH_Motorvorwaermung 0 "keine Motorvorwärmung erfolgt" 1 "Aufheizung mit Motorvorwärmung erfolgt" ;
VAL_ 1313 STH_Servicemode 0 "Servicemode nicht aktiv" 1 "Servicemode aktiv" ;
VAL_ 1313 STH_war_aktiv 0 "war inaktiv" 1 "Standheizung war letzte halbe Stunde aktiv" ;
VAL_ 1313 STH_KVS_Ueberlauf 0 "kein Überlauf" 1 "Kraftstoffverbrauchssignal, mindestens ein Überlauf hat stattgefunden" ;
VAL_ 1313 STH_SH_ZH 0 "Heizgeraet_WZH" 1 "Heizgeraet_ZH" ;
VAL_ 1650 STH_ZZ_Monat 0 "Init" ;
VAL_ 1650 STH_ZZ_Tag 0 "Init" ;
VAL_ 1650 STH_ZZ_Betriebsmodus 0 "Don_t Care" 1 "ECO" 2 "Standard" 3 "Standard plus" 4 "Comfort" ;
VAL_ 1650 STH_ZZ_Status_Timer 0 "Don_t Care" 1 "Timer n.aktiv bzw loeschen" 2 "Timer aktiv/bzw aktivieren" ;
VAL_ 505 STP_Slave_Status 0 "STP_Slave_Init" 1 "STP_Slave_Deaktiviert" 2 "STP_Slave_Ready" 3 "Vorhalt" 4 "STP_Slave_Aktivierverhinderung" 5 "STP_Slave_Aktiv" 6 "STP_Slave_ESK_Uebernahme" 7 "STP_Slave_Uebergabe" 8 "STP_Slave_ESK0_Anf" 9 "STP_Slave_ESK1_Anf" 10 "STP_Slave_ESK2_Anf" 11 "STP_Slave_ESK3_Anf" 12 "STP_Slave_stabiler_Zustand" 13 "STP_Slave_Notlauf_Aktiv" 14 "STP_Slave_nicht_verfuegbar" 15 "STP_Slave_Error" ;
VAL_ 505 FZE_STP_Abschaltbedingung 0 "Vorhalt" 1 "STP_Abschaltbedingung_liegt_nicht_an" 2 "Vorhalt" 3 "STP_ESK0" 4 "STP_ESK1" 5 "STP_ESK2" 6 "STP_ESK3" 7 "STP_NL" ;
VAL_ 505 ACA_HF_Grund_AV_AB 0 "Liegt_nicht_an_oder_init" 1 "LRR_Kriterium" 2 "Fahrerbeobachtung" 3 "Fahrerlenkeingriff" 4 "Vorhalt" 5 "Vorhalt" 6 "Vorhalt" 7 "Vorhalt" ;
VAL_ 505 FZE_STP_Status 0 "Init" 1 "Ready" 2 "Fehler_reversible" 3 "Fehler_irreversible" ;
VAL_ 505 STP_Notlaufaktivierung 0 "Notlauf_nicht_angefordert" 1 "Notlauf_angefordert" ;
VAL_ 505 STP_Funktion_freigegeben 0 "nicht_freigegeben" 1 "freigegeben" ;
VAL_ 505 ACA_QF_Status_Anzeige 0 "ACA_QF_nicht_codiert" 1 "ACA_QF_INIT" 2 "ACA_QF_AUS" 3 "ACA_QF_PASSIV" 4 "ACA_QF_AKTIV" 5 "ACA_QF_UEBERLENKT" 6 "ACA_QF_Abschaltreaktion" 7 "ACA_QF_reversibler_Fehler" 8 "ACA_QF_irreversibler_Fehler" 9 "ACA_QF_Sensor_Blindheit" ;
VAL_ 505 ACF_SwuFahrerUnaufmerksam 0 "Swu_Fahrer_Nicht_unaufmerksam" 1 "Swu_Fahrer_unaufmerksam" ;
VAL_ 505 ACA_QF_Fahreruebernahme 0 "keine" 1 "Uebernahme_1" 2 "Uebernahme_2" 3 "Uebernahme_3" ;
VAL_ 505 ACA_HF_Status 0 "ACA_HF_nicht_codiert" 1 "ACA_HF_Init" 2 "ACA_HF_aus" 3 "ACA_HF_nicht_verfuegbar" 4 "ACA_HF_verfuegbar" 5 "ACA_HF_aktiv" 6 "Vorhalt" 7 "ACA_HF_reversibler_Fehler" 8 "ACA_HF_irreversibler_Fehler" 9 "ACA_HF_Uebernahme_1" 10 "ACA_HF_Uebernahme_2" 11 "Vorhalt" 12 "Vorhalt" 13 "Vorhalt" 14 "Vorhalt" 15 "Vorhalt" ;
VAL_ 505 FZE_Spurwechsel_erkannt_li 0 "kein_Spurwechsel_erkannt" 1 "Spurwechsel_erkannt_links" ;
VAL_ 505 FZE_Spurwechsel_erkannt_re 0 "kein_Spurwechsel_erkannt" 1 "Spurwechsel_erkannt_rechts" ;
VAL_ 505 ACF_Spurwechsel_moeglich 0 "keine_Spurwechselmoeglichkeit_vorhanden" 1 "Spurwechselmoeglichkeit_vorhanden" ;
VAL_ 505 ACF_Spurwechsel_wahrscheinlich 0 "kein_Spurwechsel" 1 "Spurwechsel_wahrscheinlich" ;
VAL_ 505 FZE_STP_Aktivierverhinderung 0 "liegt_nicht_an" 1 "Fahrer_nicht_erkannt" 2 "Vorhalt" 3 "Vorhalt" ;
VAL_ 1172 STS_Car_not_under_theft 0 "false" 1 "true" ;
VAL_ 1172 STS_Car_under_theft 0 "false" 1 "true" ;
VAL_ 1172 STS_Door_Lock 0 "Init" 1 "door_lock" ;
VAL_ 1172 STS_Anlassersperre 0 "inaktiv" 1 "aktiv" ;
VAL_ 1172 STS_Typencodierung 0 "Basis" 1 "E-Gas" 4 "Sonderschutz" ;
VAL_ 1172 STS_Spiegel_Anklappen 0 "Init" 1 "Spiegel_anklappen" ;
VAL_ 1172 GW_STS2_Privatsphaere 0 "Aus" 1 "Ein" ;
VAL_ 1172 STS_Standlicht 0 "inaktiv" 1 "aktiv" ;
VAL_ 1172 STS_Fahrlicht 0 "inaktiv" 1 "aktiv" ;
VAL_ 1172 STS_Alarm_still 0 "inaktiv" 1 "aktiv" ;
VAL_ 1172 STS_Texte 0 "kein_Text" 1 "Text_01" 2 "Text_02" 3 "Text_03" 4 "Text_04" 5 "Text_05" 6 "Text_06" 7 "Text_07" 8 "Text_08" 9 "Text_09" 10 "Text_10" 11 "Text_11" 12 "Text_12" 13 "Text_13" 14 "Init" 15 "Fehler" ;
VAL_ 1172 STS_Laderelais 0 "Relais_offen" 1 "Relais_geschlossen" ;
VAL_ 1172 STS_Summer 0 "inaktiv" 1 "aktiv" ;
VAL_ 1172 STS_Alarm_Blinker 0 "Init" ;
VAL_ 1172 STS_Notstart 0 "kein_Notstart" 1 "Notstart" ;
VAL_ 1172 STS_Signalhorn 0 "inaktiv" 1 "aktiv" ;
VAL_ 1172 STS_Leerlaufschaltung 0 "inaktiv" 1 "aktiv" ;
VAL_ 783 SWA_Anzeigen 0 "keine_Anzeige" 1 "Text_1_SWA_zurzeit_nicht_verfuegbar" 2 "Text_2_SWA_Systemstoerung" 3 "Text_3_SWA_zurzeit_nicht_verfuegbar_Keine_Sensorsicht" 4 "Text_4_SWA_zurzeit_nicht_verfuegbar_Anhaengerbetrieb" 5 "Text_5_SWA_Eskalation" 6 "Text_6_SWA_eingeschränkt" ;
VAL_ 783 SWA_Blindheit_erkannt 0 "nicht erkannt" 1 "erkannt" ;
VAL_ 783 SWA_rel_Nichtverf 0 "verfuegbar" 1 "nicht verfuegbar" ;
VAL_ 783 SWA_rel_Fehler 0 "kein Fehler" 1 "Fehler" ;
VAL_ 783 SWA_Sta_aktiv 0 "Aus" 1 "Ein" ;
VAL_ 783 SWA_Sta_passiv 0 "Aus" 1 "Ein" ;
VAL_ 783 SWA_FT_RueckLED 0 "inaktiv" 1 "aktiv" ;
VAL_ 783 ASW_Status 0 "Passiv" 1 "Aktiv" 2 "Fehler" 3 "AUS" ;
VAL_ 783 SWA_Standziele_li 0 "Abstand i.O." 1 "Abstand zu gering" ;
VAL_ 783 SWA_Kolonne_li 0 "zwei_oder_weniger_Fahrzeuge_auf_der_Spur" 1 "mehr_als_zwei_Fahrzeuge_auf_der_Spur" ;
VAL_ 783 SWA_Infostufe_SWA_li 0 "keine_Aktion" 1 "Aktion" ;
VAL_ 783 SWA_Warnung_SWA_li 0 "keine Warnung" 1 "Warnung aktiv" ;
VAL_ 783 ASW_Warnung_FS 0 "inaktiv" 1 "aktiv" ;
VAL_ 783 ASW_Warnung_BFS 0 "inaktiv" 1 "aktiv" ;
VAL_ 783 ASW_Kombitexte 0 "keine Anzeige.    //    Prio 5" 1 "Text_1_ASW_zur_Zeit_nicht_verfuegbar_und_Akustik    //    Prio 2" 2 "Text_2_ASW_Systemfehler_und_Akustik    //    Prio 1" 3 "Text_3_ASW_Sensor_blockiert_und_Akustik    //    Prio 3" 4 "Text_4_ASW_im_Anhaengerbetrieb_nicht_verfuegbar_und_Akustik    //    Prio 4" 5 "Text_5_ASW_Warnung_FS_und_Akustik" 6 "Text_6_ASW_Warnung_BFS_und_Akustik" 7 "Text_7_ASW_aus" ;
VAL_ 783 SWA_Kolonne_mi 0 "zwei_oder_weniger_Fahrzeuge_auf_der_Spur" 1 "mehr_als_zwei_Fahrzeuge_auf_der_Spur" ;
VAL_ 783 ASW_Modus 0 "kein_Fehler_KL15" 1 "kein_Fehler_KL30" 2 "reserve" 3 "Anhaengerbetrieb" 4 "Init_nicht_codiert" 5 "keine_Sensorsicht_blindheit" 6 "Zur_zeit_nicht_verfuegbar_temp_Fehler" 7 "Systemstoerung_dauer_fehler" ;
VAL_ 783 SWA_Modus 0 "kein_Fehler_verfuegbar" 1 "kein_Fehler_eingeschr_Reichweite" 2 "reserve" 3 "Anhaengerbetrieb" 4 "Init_nicht_codiert" 5 "keine_Sensorsicht_blindheit" 6 "Zur_zeit_nicht_verfuegbar_temp_Fehler" 7 "Systemstoerung_dauer_fehler" ;
VAL_ 783 SWA_Standziele_re 0 "Abstand i.O." 1 "Abstand zu gering" ;
VAL_ 783 SWA_Kolonne_re 0 "zwei_oder_weniger_Fahrzeuge_auf_der_Spur" 1 "mehr_als_zwei_Fahrzeuge_auf_der_Spur" ;
VAL_ 783 SWA_Infostufe_SWA_re 0 "keine_Aktion" 1 "Aktion" ;
VAL_ 783 SWA_Warnung_SWA_re 0 "keine Warnung" 1 "Warnung aktiv" ;
VAL_ 783 HRE_Anzeigetexte 0 "keine_Anzeige" 1 "BSD_RTA_zZt_nicht_verfuegbar" 2 "BSD_RTA_Systemfehler" 3 "BSD_RTA_Sensor_blockiert" 4 "BSD_RTA_Anhaengerbetrieb" 5 "RTA_Warnung" 6 "BSD_Warnung" 7 "Fahreruebernahme_Notbremsung" 8 "RTA_nicht_verfuegbar" 9 "BSD_RTA_ASW_zZt_nicht_verfuegbar" 10 "BSD_RTA_ASW_Systemfehler" 11 "BSD_RTA_ASW_Sensor_blockiert" 12 "BSD_RTA_ASW_Anhaengerbetrieb" ;
VAL_ 783 SWA_Status_02 0 "aus" 1 "passiv" 2 "aktiv" 3 "Fehler" ;
VAL_ 783 Heckradar_Kombitexte 0 "keine Anzeige.    //    Prio 5" 1 "Text_1_SWA_und_ASW_zur_Zeit_nicht_verfuegbar_und_Akustik    //    Prio 2" 2 "Text_2_SWA_und_ASW_Systemfehler_und_Akustik    //    Prio 1" 3 "Text_3_SWA_und_ASW_Sensor_blockiert_und_Akustik    //    Prio 3" 4 "Text_4_SWA_und_ASW_im_Anhaengerbetrieb_nicht_verfuegbar_und_Akustik    //    Prio 4" 5 "Text_1_SWA_und_RCTA_zur_Zeit_nicht_verfuegbar_und_Akustik // Prio 2" 6 "Text_2_SWA_und_RCTA_Systemfehler_und_Akustik // Prio 1" 7 "		Text_3_SWA_und_RCTA_Sensor_blockiert_und_Akustik // Prio 3" 8 "Text_4_SWA_und_RCTA_im_Anhaengerbetrieb_nicht_verfuegbar_und_Akustik // Prio 4" 9 "Text_1_ASW_und_RCTA_zur_Zeit_nicht_verfuegbar_und_Akustik // Prio 2" 10 "Text_2_ASW_und_RCTA_Systemfehler_und_Akustik // Prio 1" 11 "Text_3_ASW_und_RCTA_Sensor_blockiert_und_Akustik // Prio 3" 12 "Text_4_ASW_und_RCTA_im_Anhaengerbetrieb_nicht_verfuegbar_und_Akustik // Prio 4" 13 "Text_1_SWA_und_ASW_und_RCTA_zur_Zeit_nicht_verfuegbar_und_Akustik // Prio 2" 14 "Text_2_SWA_und_ASW_und_RCTA_Systemfehler_und_Akustik // Prio 1" 15 "Text_3_SWA_und_ASW_und_RCTA_Sensor_blockiert_und_Akustik // Prio 3" 16 "Text_4_SWA_und_ASW_und_RCTA_im_Anhaengerbetrieb_nicht_verfuegbar_und_Akustik // Prio 4" 17 "reserviert" 18 "reserviert" 19 "reserviert" 20 "reserviert" 21 "reserviert" 22 "reserviert" 23 "reserviert" 24 "reserviert" 25 "reserviert" 26 "reserviert" 27 "reserviert" 28 "reserviert" 29 "reserviert" ;
VAL_ 783 RCTA_Kombitexte 0 "keine_Anzeige" 1 "RCTA_zur_Zeit_nicht_verfuegbar" 2 "RCTA_Systemfehler" 3 "RCTA_Sensor_blockiert" 4 "RCTA_im_Anhaengerbetrieb" 5 "RTA_Warnung" 6 "Fahreruebernahme_Notbremsung" 7 "Eingeschraenkt_verfuegbar_ESCaus" ;
VAL_ 673 SWA_LED_Hell_BFS 126 "Init" 127 "Fehler" ;
VAL_ 673 SWA_LED_Hell_FS 126 "Init" 127 "Fehler" ;
VAL_ 673 SWA_LED_Modus_BFS 0 "LED_aus" 1 "Infostufe" 2 "Warnstufe" 3 "Aufpruefen_Kl15" 4 "Aufpruefen_BAP" ;
VAL_ 673 SWA_LED_Modus_FS 0 "LED_aus" 1 "Infostufe" 2 "Warnstufe" 3 "Aufpruefen_Kl15" 4 "Aufpruefen_BAP" ;
VAL_ 1413 SI_Sammel_SG_Fehler 61 "Reserviert" 62 "Overflow" 63 "ungueltig" ;
VAL_ 1413 SI_Diagnose_Aktiv 0 "inaktiv" 1 "aktiv" ;
VAL_ 1413 SI_QRS_Mode 0 "QRS_Messmodus_nicht_aktiv" 1 "QRS_Messmodus_aktiv" ;
VAL_ 1413 SI_T_Mode 0 "Transportmodus_nicht_aktiv" 1 "Transportmodus_aktiv" ;
VAL_ 1413 SI_NWDF 0 "Ueberwachung_nicht_freigegeben" 1 "Ueberwachung_freigegeben" ;
VAL_ 1413 SI_NWDF_gueltig 0 "NWDF_wird_nicht_unterstuetzt" 1 "NWDF_wird_unterstuetzt" ;
VAL_ 1413 SI_Sammelfehler 0 "kein_Sammelfehler" 1 "Sammelfehler" ;
VAL_ 1413 GW_KD_Fehler 0 "kein_KD_Fehler" 1 "KD_Fehler" ;
VAL_ 1413 SI_T_Schutz 0 "Transportschutz_nicht_aktiv" 1 "Transportschutz_aktiv" ;
VAL_ 1413 SI_BUS_01 0 "keine_Busruhe" 1 "Busruhe" ;
VAL_ 1413 SI_BUS_02 0 "keine_Busruhe" 1 "Busruhe" ;
VAL_ 1413 SI_BUS_03 0 "keine_Busruhe" 1 "Busruhe" ;
VAL_ 1413 SI_BUS_04 0 "keine_Busruhe" 1 "Busruhe" ;
VAL_ 1413 SI_BUS_05 0 "keine_Busruhe" 1 "Busruhe" ;
VAL_ 1413 SI_BUS_06 0 "keine_Busruhe" 1 "Busruhe" ;
VAL_ 1413 SI_BUS_07 0 "keine_Busruhe" 1 "Busruhe" ;
VAL_ 1413 SI_BUS_08 0 "keine_Busruhe" 1 "Busruhe" ;
VAL_ 1413 SI_BUS_09 0 "keine_Busruhe" 1 "Busruhe" ;
VAL_ 1413 SI_BUS_10 0 "keine_Busruhe" 1 "Busruhe" ;
VAL_ 1413 SI_BUS_11 0 "keine_Busruhe" 1 "Busruhe" ;
VAL_ 1413 SI_BUS_12 0 "keine_Busruhe" 1 "Busruhe" ;
VAL_ 1413 SI_BUS_13 0 "keine_Busruhe" 1 "Busruhe" ;
VAL_ 1413 SI_BUS_14 0 "keine_Busruhe" 1 "Busruhe" ;
VAL_ 1413 SI_BUS_15 0 "keine_Busruhe" 1 "Busruhe" ;
VAL_ 1413 SI_Bus_Identifikation 16 "CAN_Diagnose" 17 "CAN_Antrieb" 18 "CAN_Komfort" 19 "CAN_Infotainment" 20 "CAN_Fahrwerk" 21 "CAN_Extended" 22 "CAN_Hybrid" 23 "CAN_Lade" 24 "CAN_Kombi" 25 "CAN_Komfort_2" 26 "CAN_AFS" 27 "CAN_MIB" 33 "CAN_FahrerAssistenzSysteme" 34 "CAN_Migration" 35 "CAN_Connect" 36 "CAN_AnzeigeBedienung" 37 "CAN_ElectricalVehicle" 40 "CAN_Telematik" 41 "CAN_MFL" 42 "CAN_FahrerAssistenzSysteme_2" 47 "CAN_Komfort_3" 48 "FlexRay_A" 49 "FlexRay_B" 97 "VLAN_FAS" 98 "VLAN_Infotainment" 99 "VLAN_Connect" 100 "VLAN_Komfort" 101 "VLAN_Antrieb" 102 "VLAN_Diagnose" 103 "VLAN_Internet" 104 "VLAN_Gateway" 105 "VLAN_Remote_FC" 106 "VLAN_Connect_2" 107 "VLAN_Licht" 108 "VLAN_Charge" 109 "VLAN_Cockpit" 176 "HCP1_CANFD01" 177 "HCP1_CANFD02" 178 "HCP1_CANFD03" 179 "HCP1_CANFD04" 180 "HCP1_CANFD05" 181 "HCP1_CANFD06" 182 "HCP1_CANFD07" 183 "HCP1_CANFD08" 186 "HCP4_CANFD03" 187 "HCP4_CANFD04" 188 "HCP1_CANFD09" 189 "HCP4_CANFD06" 190 "HCP4_CANFD07" 191 "HCP4_CANFD08" 192 "HCP4_CANFD09" 193 "HCP4_CANFD10" 194 "HCP1_CANFD10" 195 "ICAS1_CANFD2_HCP5_CANFD02" 196 "HCP1_CANFD11" 197 "WU_HCP1_CANFD" 199 "WU_HCP2_CANFD" 200 "WU_HCP3_CANFD" 201 "WU_HCP4_CANFD" 202 "HCP3_CANFD02" 204 "ESC_CANFD" 205 "HCP4_CANFD11" 206 "HCP4_CANFD12" 207 "HCP5_CANFD04" 208 "HCP5_CANFD05" 212 "WU_ConMod_CANFD" 213 "WU_PASD_CANFD" 215 "CAN_MobileDeviceKey" ;
VAL_ 1413 SI_CAB 0 "inaktiv" 1 "CAB_01__Tueren" 2 "CAB_02__Anhaenger" 4 "CAB_03__Nightvision" 8 "CAB_04__Sitzverstellung" 16 "CAB_05__Klappen" 32 "CAB_06__Infotainment" 64 "CAB_07__Sub_Infotainment" 128 "CAB_08__Anzeige" 256 "CAB_09__Laden" 512 "CAB_10__Klima" 1024 "CAB_11__FlexRay" 262144 "CAB_19_VLAN_Remote_FC" 524288 "CAB_20_VLAN_Komfort" 1048576 "CAB_21_VLAN_Internet" 2097152 "CAB_22_VLAN_Connect" 4194304 "CAB_23_VLAN_Infotainment" 8388608 "CAB_24_VLAN_FAS" ;
VAL_ 1015 KL_HV_Energie_Anf 253 "nicht_berechnet" 254 "Init" 255 "Fehler" ;
VAL_ 1015 TME_Kuehlerluefer_3 126 "Init" 127 "Fehler" ;
VAL_ 1015 TME_StartStopp_Info_Prio 0 "Motorlauf_zwingend" 1 "Motorlauf_nicht_zwingend" ;
VAL_ 1015 TME_HVEM_HV_Anf 0 "INIT" 1 "HV_Netz_nicht_angefordert" 2 "HV_Netz_angefordert" 3 "Fehler" ;
VAL_ 1015 TME_StartStopp_Info 0 "Stoppfreigabe" 1 "Stoppverbot" 2 "Startanforderung" 3 "Fehler" ;
VAL_ 1015 TME_OBD_Lampe_Anf 0 "kein_MIL_Request" 1 "MIL_Request" ;
VAL_ 1015 TME_HVPTC_Istmodus 0 "Standby" 1 "Regelung_aktiv" 2 "Freigabe_ausgesetzt" 5 "Fehler" 7 "Init" ;
VAL_ 1015 TME_HVPTC_Fehlerstatus 0 "Komponente_IO" 1 "Keine_HV_Spannung" 2 "Eingeschr_KompFkt_Entlad_defekt" 3 "Eingeschr_KompFkt_Interlock" 4 "Entlad_defekt_keine_HV_Spannung" 6 "Keine_Komponentenfunktion" 7 "Init" ;
VAL_ 1015 TME_EKK_Istmodus 0 "Standby" 1 "Regelung_aktiv" 2 "Freigabe_ausgesetzt" 5 "Fehler" 7 "Init" ;
VAL_ 1015 TME_EKK_Fehlerstatus 0 "Komponente_IO" 1 "Keine_HV_Spannung" 3 "Eingeschr_KompFkt_Interlock" 6 "Keine_Komponentenfunktion" 7 "Init" ;
VAL_ 1015 TME_HVK_EKK_SOLL 0 "Init" 1 "Off" 2 "On" 3 "Fehler" ;
VAL_ 1015 TME_Strom_Kuehlerluefter 30 "Init" 31 "Fehler" ;
VAL_ 1015 TME_PWM_Pumpe1_tNT_Soll 126 "Init" 127 "Fehler" ;
VAL_ 1017 TME_NT_Kreis_Status 0 "kein_Fehler" 1 "Fehler" ;
VAL_ 1017 TME_Ventil1_Status 0 "Ventil_offen__grosser_Kreislauf" 1 "Ventil_geschlossen__kleiner_Kreislauf" ;
VAL_ 1017 TME_Fehler_ElWaPu1 0 "kein_Fehler" 1 "Fehler" ;
VAL_ 1017 TME_Pumpe1_Status 0 "inaktiv" 1 "aktiv" ;
VAL_ 1017 TME_Nachlaufzeit 0 "Init" ;
VAL_ 1017 TME_Anf_KL 126 "Init" 127 "Fehler" ;
VAL_ 1017 TME_Status_KL 0 "kein_Fehler" 1 "Fehler_KL_1" 2 "Fehler_KL_2" 3 "Fehler_KL_1_und_KL_2" ;
VAL_ 1017 TME_MMTR_Status 0 "Nicht_verbaut" 1 "Nicht_verfuegbar" 2 "Inaktiv" 3 "Aktiv_Running" 4 "Fertig_TrackReady" 6 "Abgebrochen_Fehler" 14 "Init" 15 "Fehler" ;
VAL_ 1017 TME_EM1_IstVolumenstrom 30 "Init" 31 "Fehler" ;
VAL_ 1017 TME_EM2_IstVolumenstrom 30 "Init" 31 "Fehler" ;
VAL_ 1017 TME_EM3_IstVolumenstrom 30 "Init" 31 "Fehler" ;
VAL_ 1017 TME_PWM_Pumpe2_HK_Soll 126 "Init" 127 "Fehler" ;
VAL_ 1375 TME_VoKo_Strategie_Anzeige 0 "Inaktiv" 1 "Standby" 2 "Lueften_elektrisch" 3 "Lueften_konventionell" 4 "Kuehlen_elektrisch" 5 "Reheat_elektrisch" 6 "Heizen_elektrisch" 7 "Heizen_verbrennungstechnisch" 8 "Reserve" 14 "Init" 15 "Fehler" ;
VAL_ 1375 TME_Zuheizer_Freigabe 0 "keine_Freigabe" 1 "Freigabe" ;
VAL_ 1375 TME_AC_LED 0 "LED_aus" 1 "LED_ein" ;
VAL_ 1375 TME_Heizstrategie 0 "Init" 1 "Aus" 2 "Spuelen" 3 "Kanalkuehlung" 4 "Kuehhlwasserzirkulation" 5 "aktive_Kuehlung" 6 "Heizen" 7 "Reheat" 8 "Heizen_elektrisch" 9 "Heizen_verbrennungstechnisch" 10 "Konditionierung_n_moeglich" 11 "Heizstrategie_11" 12 "Heizstrategie_12" 13 "Heizstrategie_13" 14 "Heizstrategie_14" 15 "Fehler" ;
VAL_ 1375 TME_Systemstatus 0 "System_IO" 1 "System_reduziert__Akkustik" 2 "System_reduziert__HV_Management" 3 "Fehler" ;
VAL_ 1375 TME_Kbr_Innenraum 0 "nicht_verfuegbar" 1 "verfuegbar" ;
VAL_ 1375 TME_Freigabe_Vorkond 0 "keine_Freigabe" 1 "Freigabe" ;
VAL_ 1375 TME_Verdampfer_Status 0 "inaktiv" 1 "aktiv" ;
VAL_ 1375 TME_Kuehlmittel_Sensor 0 "Kuehlkreis_OK" 1 "Kuehlmittelmangel_Pumpenfehler" ;
VAL_ 1375 TME_AC_Rueckmeldung 0 "EKK_laeuft_nicht" 1 "EKK_laeuft_reduziert" 2 "EKK_laeuft" 3 "Fehler" ;
VAL_ 1375 TME_Heizungspumpen_Anst 13 "Fehler" 14 "Init" 15 "nicht_verbaut" ;
VAL_ 1375 TME_Frischluftklappe_Soll 126 "Init" 127 "Fehler" ;
VAL_ 1375 TME_Freigabe_Luft_PTC 0 "keine_Freigabe" 1 "Freigabe" ;
VAL_ 1375 TME_Umluftklappe_Soll 126 "Init" 127 "Fehler" ;
VAL_ 1375 TME_Waermepumpe_aktiv 0 "inaktiv" 1 "aktiv" ;
VAL_ 1375 TME_Absperrventil1_oeffnen 0 "nicht_verfuegbar" 1 "Ansteuerung_Ventil_zulaessig" 2 "Ventil_oeffnen_oder_geoeffnet" 3 "Ventil_schliessen_oder_geschlossen" ;
VAL_ 1375 TME_Klima_Defizit 254 "Init" 255 "Fehler" ;
VAL_ 1375 TME_Temp_KM_vor_HWT 254 "Init" 255 "Fehler" ;
VAL_ 1373 TME_Geblaese 0 "Geblaese_aus_INIT" 1 "Geblaese_Regelung" 2 "Geblaese_Notlauf" ;
VAL_ 1373 TME_Kond_Innen_Betrieb 0 "INIT" 1 "Voko_aktiv" 2 "Voko_inaktiv" 3 "Systemfehler_Standheizung" 4 "Systemfehler_HV_Komponente" 5 "Systemfehler_Sthzg_und_HV_Komp" 6 "Systemeinschr_Kraftstoff_Reserve" 7 "Systemeinschr_HV_Batt_low" 8 "Systemeinschr_LV_Batt_low" 9 "Systemeinschr_Verdeck_Position" ;
VAL_ 1373 TME_Klimadefizit 0 "Kein_Leistungsdefizit" 1 "Leistungsdefizit_erkannt" ;
VAL_ 1373 TME_STH_Status 0 "INIT" 1 "Sthzg_iO" 2 "Tankwarnung" 3 "BEM_Einschraenkung" 4 "Systemstoerung" 5 "__" 6 "__" 7 "Fehler" ;
VAL_ 1373 TME_Kond_Innen_Status 0 "INIT" 1 "Kond_Innen_moeglich" 2 "Systemfehler_Standheizung" 3 "Systemfehler_HV_Komp" 4 "Systemfehler_Sthzg_und_HV_Komp" 5 "Systemeinschr_Kraftstoff_Reserve" 6 "Systemeinschr_HV_Batt_low" 7 "Systemeinschr_LV_Batt_low" 8 "Systemeinschr_Verdeck_Position" 9 "Reserve" 10 "Reserve" 11 "Reserve" 12 "Reserve" 13 "Reserve" 14 "Reserve" 15 "Reserve" ;
VAL_ 1373 TME_STH_Ansteuerung 0 "AUS" 1 "EIN" ;
VAL_ 1373 TME_Verdampfertemperatur 1022 "Init" 1023 "Fehler" ;
VAL_ 1373 TME_Temp_KM_vor_LE 254 "Init" 255 "Fehler" ;
VAL_ 1373 TME_Kuehlmittel_Temp_Pumpe1_tNT 254 "Init" 255 "Fehler" ;
VAL_ 1373 TME_STH_aktiv 0 "INIT" 1 "Standheizung_aktiv" 2 "Standheizung_nicht_aktiv" 3 "Fehler" ;
VAL_ 1373 TME_SKE_Status_2 0 "Init" 1 "geschlossen" 2 "offen" 3 "Fehler" ;
VAL_ 1373 TME_STL_aktiv 0 "INIT" 1 "Standlueften_aktiv" 2 "Standlueften_nicht_aktiv" 3 "Fehler" ;
VAL_ 1373 TME_Thermomanagement 0 "keine_Freigabe_TMM__max_Heizbedarf" 1 "kleine_Freigabe_TMM" 2 "mittlere_Freigabe_TMM" 3 "volle_Freigabe_TMM__kein_Heizbedarf" ;
VAL_ 1373 TME_IstSpannung_EKK_HV 255 "Init/ Not Avail" ;
VAL_ 1657 TME_TCP_Kond_active 0 "TCP_Konditionierung_inaktiv" 1 "TCP_Konditionierung_aktiv" ;
VAL_ 1657 TME_Temp_KM_vor_eATL 254 "Init" 255 "Fehler" ;
VAL_ 1657 TME_Temp_KM_nach_EM 253 "Nicht_verbaut" 254 "Init" 255 "Fehler" ;
VAL_ 1657 TME_EKK_ProtectionMode 0 "ProtectionMode_inactive" 1 "ProtectionMode_active" ;
VAL_ 1657 TME_Klimaanforderung 0 "keine_Anforderung_durch_TME" 1 "Klimaleistungspraediktion_aktiv" 2 "berechnung_Vorkonditionierung_aktiv" 3 "Vorkonditionierung_aktiv" ;
VAL_ 1657 TME_SKE_Pos_Summe 14 "Init" ;
VAL_ 1657 TME_Waermebilanz_Status 0 "kein_Fehler" 1 "TP_TC_OBDI" 2 "TP_TC_OBDII" 3 "Fehler" ;
VAL_ 1657 TME_Waermebilanz 0 "kein_Waermestrom" 1 "kleiner_Waermestrom" 2 "mittlerer_Waermestrom" 3 "hoher_Waermestrom" ;
VAL_ 1657 TME_Klimaleistung 126 "Init" ;
VAL_ 1657 TME_SKE_PosResp 0 "SKE_Soll_nicht_erreicht" 1 "SKE_Soll_erreicht" ;
VAL_ 1657 TME_SKE_Position_1 0 "Geoeffnet" 1 "Teilgeschlossen" 2 "Geschlossen" 3 "Init" ;
VAL_ 1657 TME_Systemtemp 254 "Init" 255 "Fehler" ;
VAL_ 1657 TME_Eingriff_SKE_Oeffnung 0 "Init" 1 "offen" 2 "teilgeschlossen" 3 "geschlossen" ;
VAL_ 1657 TME_SKE_Status 0 "Init" 1 "geschlossen" 2 "offen" 3 "Fehler" ;
VAL_ 1657 TME_Status_Kuehlmittel_Tmp_CrChk 0 "Pruefung_nicht_erfolgt" 1 "kein_Fehler_Kuehlmittel_Temp" 2 "Fehler_Kuehlmittel_Temp" ;
VAL_ 1657 TME_Temperatur_Ruecklauf_VKM 254 "Init" 255 "Fehler" ;
VAL_ 977 BT_Tuer_geoeffnet 0 "geschlossen" 1 "offen" ;
VAL_ 977 BT_verriegelt 0 "Init" 1 "verriegelt" ;
VAL_ 977 BT_gesafet 0 "Init" 1 "gesafet" ;
VAL_ 977 BT_Schluesselschalter_auf 0 "Init" 1 "Schluesselschalter_auf_betaetigt" ;
VAL_ 977 BT_Schluesselschalter_zu 0 "Init" 1 "Schluesselschalter_zu_betaetigt" ;
VAL_ 977 BT_Unlock_Taster 0 "Init" 1 "Unlock_Taster_betaetigt" ;
VAL_ 977 BT_Lock_Taster 0 "Init" 1 "Lock_Taster_betaetigt" ;
VAL_ 977 BT_Sperrklinke 0 "Schloss_in_Vorraste_und_Hauptraste" 1 "Tuer_auf_oder_Tuer_Position_zwischen_Vor_und_Hauptraste" ;
VAL_ 977 BT_TAG_betaetigt 0 "Init" 1 "Tuerinnengriff_betaetigt" ;
VAL_ 977 BT_TIG_betaetigt 0 "Init" 1 "Tuerinnengriff_betaetigt" ;
VAL_ 977 BT_Tuer_Status 0 "Init" 1 "Tuer_geschlossen" 2 "Tuer_offen" 3 "Fehler" ;
VAL_ 977 BT_TSG_hinten_verbaut 0 "nicht verbaut" 1 "verbaut" ;
VAL_ 977 BT_Sp_Blk_def 0 "iO" 1 "Spiegel_Blinker_defekt" ;
VAL_ 977 BT_FH_S_ManHoch 0 "Init" 1 "FH_Schalter_man_hoch_gedrueckt" ;
VAL_ 977 BT_FH_S_AutoHoch 0 "Init" 1 "FH_Schalter_auto_hoch_gedrueckt" ;
VAL_ 977 BT_FH_S_ManTief 0 "Init" 1 "FH_Schalter_man_tief_gedrueckt" ;
VAL_ 977 BT_FH_S_AutoTief 0 "Init" 1 "FH_Schalter_auto_tief_gedrueckt" ;
VAL_ 977 BT_FH_Bew_hoch 0 "Init" 1 "FH_ist_in_Bewegung_hoch" ;
VAL_ 977 BT_FH_Bew_tief 0 "Init" 1 "FH_ist_in_Bewegung_tief" ;
VAL_ 977 BT_FH_Fang 0 "ausserhalb_Fangbereich" 1 "innerhalb_Fangbereich" ;
VAL_ 977 BT_FH_Block 0 "Init" 1 "Fensterheber_Block" ;
VAL_ 977 BT_FH_Thermo 0 "Init" 1 "Thermoschutz_aktiv" ;
VAL_ 977 BT_UEKB_aktiviert 0 "Init" 1 "aktiv" ;
VAL_ 977 BT_Kisi_Fehler 0 "kein_Fehler" 1 "Fehler" ;
VAL_ 977 BT_FH_normiert 0 "Init" 1 "Fenster_normiert" ;
VAL_ 977 BT_Schliesstaster 1 "betaetigt" ;
VAL_ 977 BT_Zuziehhilfe_aktiv 0 "Init" 1 "Zuziehhilfe_aktiv" ;
VAL_ 977 BT_SP_ausgerastet 0 "Init" 1 "Spiegel_ausgerastet" ;
VAL_ 977 BT_SP_lr_aktiv 0 "Init" 1 "Spiegel_xAchse_aktiv" ;
VAL_ 977 BT_SP_ht_aktiv 0 "Init" 1 "Spiegel_yAchse_aktiv" ;
VAL_ 977 BT_SP_Heizung_aktiv 1 "BF Spiegelheizung ein" ;
VAL_ 977 BT_Oben_Block_erw 0 "Fensterheber_nicht_in_Blockerwar" 1 "Fensterheber_in_Blockerwartung_o" ;
VAL_ 977 BT_Unten_Block_erw 0 "Fensterheber_nicht_in_Blockerwar" 1 "Fensterheber_in_Blockerwartung_u" ;
VAL_ 977 BT_Tuer_Status_QBit 0 "Status_Tuerkontakt_sicher" 1 "Status_Tuerkontakt_unsicher" ;
VAL_ 977 BFS_Status_eTAG 0 "Init" 1 "Griff_ausgefahren" 2 "Griff_eingefahren" 3 "Fehler" ;
VAL_ 977 BT_TCR_Mode_aktiv 0 "TCR_Mode_deaktiv" 1 "TCR_Mode_aktiv" ;
VAL_ 977 BT_SP_Heizung_Status 0 "Init" 1 "Status_Spiegelheizung_ein" ;
VAL_ 977 ASW_Warnung_aktiv_BFS 0 "nicht_angefordert" 1 "angefordert" ;
VAL_ 977 BT_FH_Pos_oben 1 "Scheibe oben (nach Absenken auf Position) " ;
VAL_ 977 BT_Tuerschloss_defekt 0 "Tuerschloss_funktionsfaehig" 1 "Tuerschloss_defekt" ;
VAL_ 977 BT_Tueroeffnen_Warnung 0 "Tuerwarnung_nicht_aktiv" 1 "Tuerwarnung_aktiv" ;
VAL_ 977 BT_Lock_Taster_inv 0 "Lock Taster betätigt" 1 "Lock Taster nicht betätigt" ;
VAL_ 977 BT_Schluesselschalter_zu_inv 0 "Schlüsselschalter betätigt" 1 "Schlüsselschalter nicht betätigt" ;
VAL_ 977 BT_SWA_HMI_defekt 0 "SWA_kein_Fehler" 1 "SWA_Fehler" ;
VAL_ 977 BT_ASW_HMI_defekt 0 "ASW_kein_Fehler" 1 "ASW_Fehler" ;
VAL_ 1451 TSG_FlHz_BFS_NTC_A 125 "Fehler_NTC_OpenLoad_KS_Plus" 126 "Fehler_NTC_Overload_KS_Minus" 127 "Init" ;
VAL_ 1451 TSG_FlHz_BFS_FnAbbruchHzKreis_A 0 "OK" 1 "FunktionsAbbruch" ;
VAL_ 1451 TSG_FlHz_BFS_NTC_B 125 "Fehler_NTC_OpenLoad_KS_Plus" 126 "Fehler_NTC_Overload_KS_Minus" 127 "Init" ;
VAL_ 1451 TSG_FlHz_BFS_FnAbbruchHzKreis_B 0 "OK" 1 "FunktionsAbbruch" ;
